VERSION ""

NS_ :

BS_:

BU_: Airbag_MQB BAP_Tester_MQB BMS_MQB Datenlogger_MQB Gateway_MQB Getriebe_DQ_Hybrid_MQB Getriebe_DQ_MQB LEH_MQB Motor_Diesel_MQB Motor_Hybrid_MQB Motor_Otto_MQB SAK_MQB Waehlhebel_MQB Vector__XXX l c i XXX

BO_ 290 ACC_06: 8 XXX
 SG_ CHECKSUM : 0|8@1+ (1,0) [0|255] ""  XXX
 SG_ COUNTER : 8|4@1+ (1,0) [0|15] ""  XXX
 SG_ ACC_Limited_PullAwayDyn : 12|1@1+ (1,0) [0|1] ""  XXX
 SG_ ACC_Retrofit_Stop_Req : 13|1@1+ (1,0) [0|1] ""  XXX
 SG_ ACC_DynIncrease : 14|1@1+ (1.0,0.0) [0.0|1] ""  XXX
 SG_ ACC_FreewheelStrategy_TSK : 15|1@1+ (1.0,0.0) [0.0|1] ""  XXX
 SG_ ACC_Allowed_ControlDeviation_Bottom : 16|6@1+ (0.024,0) [0|1.512] "Unit_MeterPerSeconSquar"  XXX
 SG_ ACC_StartStop_Info : 22|2@1+ (1,0) [0|3] ""  XXX
 SG_ ACC_TargetAcceleration_02 : 24|11@1+ (0.005,-7.22) [-7.22|3.005] "Unit_MeterPerSeconSquar"  XXX
 SG_ ACC_Allowed_ControlDeviation_Top : 35|5@1+ (0.0625,0) [0|1.9375] "Unit_MeterPerSeconSquar"  XXX
 SG_ ACC_Neg_TargetAccel_Degree_02 : 40|8@1+ (0.05,0) [0|12.75] "Unit_MeterPerCubicSecon"  XXX
 SG_ ACC_pos_TargetAccel_Degree_02 : 48|8@1+ (0.05,0) [0|12.75] "Unit_MeterPerCubicSecon"  XXX
 SG_ ACC_PullAway : 56|1@1+ (1,0) [0|1] ""  XXX
 SG_ ACC_Stop : 57|1@1+ (1,0) [0|1] ""  XXX
 SG_ ACC_Type : 58|2@1+ (1,0) [0|3] ""  XXX
 SG_ ACC_Status_ACC : 60|3@1+ (1,0) [0|7] ""  XXX
 SG_ ACC_Minimum_Braking : 63|1@1+ (1,0) [0|1] ""  XXX

BO_ 279 ACC_10: 8 XXX
 SG_ CHECKSUM : 0|8@1+ (1,0) [0|255] ""  XXX
 SG_ COUNTER : 8|4@1+ (1,0) [0|15] ""  XXX
 SG_ AWV_AWA_Status_EPS : 12|4@1+ (1,0) [0|7] ""  XXX
 SG_ AWV1_Req_Prefill : 16|1@1+ (1,0) [0|1] ""  XXX
 SG_ ANB_CM_Info : 17|1@1+ (1,0) [0|1] ""  XXX
 SG_ AWV2_Enable : 18|1@1+ (1,0) [0|1] ""  XXX
 SG_ AWV1_HBA_Param : 19|2@1+ (1,0) [0|3] ""  XXX
 SG_ AWV2_JerkProfile : 21|3@1+ (1,0) [0|7] ""  XXX
 SG_ AWV2_PrioWarning : 24|1@1+ (1,0) [0|1] ""  XXX
 SG_ ANB_CM_Request : 25|1@1+ (1,0) [0|1] ""  XXX
 SG_ ANB_Info_PartialBraking : 26|1@1+ (1,0) [0|1] ""  XXX
 SG_ ANB_EmergencyFlash : 27|1@1+ (1,0) [0|1] ""  XXX
 SG_ ANB_PartialBraking_Enable : 28|1@1+ (1,0) [0|1] ""  XXX
 SG_ ANB_TargetBrake_Teilbrems_Decel_Req : 29|10@1+ (0.024,-20.016) [-20.016|4.536] "Unit_MeterPerSeconSquar"  XXX
 SG_ ANB_TargetBraking_Enable : 39|1@1+ (1,0) [0|1] ""  XXX
 SG_ AWV_BeforeStage : 40|1@1+ (1,0) [0|1] ""  XXX
 SG_ AWV_Hold : 41|1@1+ (1,0) [0|1] ""  XXX
 SG_ AWV_CityANB_Variant : 42|1@1+ (1,0) [0|1] ""  XXX
 SG_ PCF_Enable : 43|1@1+ (1,0) [0|1] ""  XXX
 SG_ AWV1_ECD_StartUp : 44|1@1+ (1,0) [0|1] ""  XXX
 SG_ AWV_AWA_VZ_Req_Lenkmomoffset : 46|1@1+ (1.0,0.0) [0.0|1] ""  XXX
 SG_ AWV_AWA_Req_Lenkmomoffset : 47|9@1+ (0.01,0) [0.00|5.11] "Unit_NewtoMeter"  XXX
 SG_ PCF_Time_to_collision : 56|8@1+ (0.01,0) [0|2.5] "Unit_Secon"  XXX

BO_ 304 PLA_01: 8 XXX
 SG_ CHECKSUM : 0|8@1+ (1,0) [0|255] ""  XXX
 SG_ COUNTER : 8|4@1+ (1,0) [0|15] ""  XXX
 SG_ PLA_Status_PLA_ESP : 12|4@1+ (1.0,0.0) [0.0|15] ""  XXX
 SG_ PLA_LW_Target : 16|13@1+ (0.1,0) [0.0|819.1] "Unit_DegreOfArc"  XXX
 SG_ PLA_VZ_LW_Target : 31|1@1+ (1.0,0.0) [0.0|1] ""  XXX
 SG_ PLA_Status_PLA_EPS : 32|4@1+ (1.0,0.0) [0.0|15] ""  XXX
 SG_ PLA_BrakeTorque m0 : 36|13@1+ (4,0) [0|32760] "Unit_NewtoMeter" XXX
 SG_ PLA_BrakeDeceleration m1 : 36|7@1+ (0.1,0) [0|12] "Unit_MeterPerSeconSquar" XXX
 SG_ PLA_Req_BrakeDeceleration m1 : 43|1@1+ (1,0) [0|1] "" XXX
 SG_ PLA_BrakeTorque_Decel M : 50|1@1+ (1,0) [0|1] "" XXX
 SG_ PLA_Stop : 51|1@1+ (1.0,0.0) [0.0|1] ""  XXX
 SG_ PLA_StoppingDistance : 52|11@1+ (0.01,0) [0.01|20.45] "Unit_Meter"  XXX
 SG_ PLA_01_Signal_red_cyclic : 63|1@1+ (1.0,0.0) [0.0|1] ""  XXX

BO_ 679 ACC_13: 8 XXX
 SG_ ACC_ControlSpeed : 12|10@1+ (0.32,0) [0|327.04] "Unit_KiloMeterPerHour"  XXX
 SG_ ACC_Unit_maxSetSpeed : 22|1@1+ (1,0) [0|1] ""  XXX
 SG_ ACC_maxSetSpeed : 23|9@1+ (1,0) [0|510] ""  XXX
 SG_ ACC_minControlSpeed : 32|8@1+ (0.32,0) [0|81.28] "Unit_KiloMeterPerHour"  XXX
 SG_ ACC_maxControlSpeed : 40|8@1+ (0.32,0) [0|81.28] "Unit_KiloMeterPerHour"  XXX
 SG_ ACC_SpeedLimitAssist : 48|2@1+ (1,0) [0|3] ""  XXX
 SG_ ACC_CurveAssist : 52|3@1+ (1,0) [0|7] ""  XXX
 SG_ ACC_RUV : 56|2@1+ (1,0) [0|3] ""  XXX
 SG_ ACC_SpeedoScale : 58|1@1+ (1,0) [0|1] ""  XXX
 SG_ ACC_Type_SpeedoScale_Bottom : 59|1@1+ (1,0) [0|1] ""  XXX
 SG_ ACC_ENG_Texte : 60|2@1+ (1,0) [0|3] ""  XXX
 SG_ ACC_ADAPTIVE : 63|2@0+ (1,0) [0|3] "" XXX

BO_ 681 ACC_15: 8 XXX
 SG_ AWV_Warning : 16|3@1+ (1,0) [0|7] ""  XXX
 SG_ AWV_Texte : 24|3@1+ (1,0) [0|7] ""  XXX
 SG_ AWV_Status_Display : 32|2@1+ (1,0) [0|3] ""  XXX
 SG_ AWV_OnPosition_System_FSG : 34|1@1+ (1,0) [0|1] ""  XXX
 SG_ AWV_OnPosition_Warning_FSG : 36|3@1+ (1,0) [0|7] ""  XXX
 SG_ AWV_Warnlevel : 58|6@1+ (1,0) [0|63] ""  XXX

BO_ 64 Airbag_01: 8 Airbag_MQB
 SG_ CHECKSUM : 0|8@1+ (1,0) [0|255] "" BMS_MQB,Gateway_MQB,LEH_MQB,Motor_Diesel_MQB,Motor_Hybrid_MQB,Motor_Otto_MQB
 SG_ COUNTER : 8|4@1+ (1,0) [0|15] "" BMS_MQB,Gateway_MQB,LEH_MQB,Motor_Diesel_MQB,Motor_Hybrid_MQB,Motor_Otto_MQB
 SG_ FROM_RGS_Anst : 12|4@1+ (1,0) [0|15] "" Gateway_MQB
 SG_ FROM_Front_Crash : 16|1@1+ (1,0) [0|1] "" Gateway_MQB
 SG_ FROM_Rear_Crash : 17|1@1+ (1,0) [0|1] "" Gateway_MQB
 SG_ FROM_SF_Crash : 18|1@1+ (1,0) [0|1] "" Gateway_MQB
 SG_ FROM_SB_Crash : 19|1@1+ (1,0) [0|1] "" Gateway_MQB
 SG_ FROM_Rollover_Crash : 20|1@1+ (1,0) [0|1] "" Gateway_MQB
 SG_ FROM_Crash_Int : 21|3@1+ (1,0) [0|7] "" BMS_MQB,Gateway_MQB,LEH_MQB,Motor_Diesel_MQB,Motor_Hybrid_MQB,Motor_Otto_MQB
 SG_ FROM_Lamp : 24|1@1+ (1,0) [0|1] "" Gateway_MQB
 SG_ FROM_Deactivated : 25|1@1+ (1,0) [0|1] "" Gateway_MQB
 SG_ FROM_VB_Deactivated : 26|1@1+ (1,0) [0|1] "" Gateway_MQB
 SG_ FROM_SystemError : 27|1@1+ (1,0) [0|1] "" BMS_MQB,Gateway_MQB,LEH_MQB
 SG_ FROM_Diagnostics : 28|1@1+ (1,0) [0|1] "" Gateway_MQB
 SG_ FROM_ActuatorTest : 29|1@1+ (1,0) [0|1] "" BMS_MQB,Gateway_MQB,Motor_Diesel_MQB,Motor_Hybrid_MQB,Motor_Otto_MQB
 SG_ FROM_Erh_Open_VB : 30|2@1+ (1,0) [0|3] "" Gateway_MQB
 SG_ FROM_BeltWarn_VF : 32|1@1+ (1,0) [0|1] "" Gateway_MQB
 SG_ FROM_BeltWarn_VB : 33|1@1+ (1,0) [0|1] "" Gateway_MQB
 SG_ FROM_Display_Pedestrian : 34|2@1+ (1,0) [0|3] "" Gateway_MQB
 SG_ FROM_Texte_AKS : 36|2@1+ (1,0) [0|3] "" Gateway_MQB
 SG_ FROM_PAO_Lamp_Req : 38|1@1+ (1,0) [0|1] "" Gateway_MQB
 SG_ FROM_MKB_Valid : 39|1@1+ (1,0) [0|1] "" Gateway_MQB
 SG_ FROM_MKB_Request : 40|1@1+ (1,0) [0|1] "" Gateway_MQB
 SG_ FROM_SupplyVoltage : 41|1@1+ (1,0) [0|1] "" Gateway_MQB
 SG_ FROM_Deactivation_HV : 42|3@1+ (1.0,0.0) [0.0|7] ""  BMS,Gateway_MQB,LEH_MQB,Motor_Hybrid_MQB
 SG_ FROM_EDR_Trigger : 45|2@1+ (1.0,0.0) [0.0|3] ""  Gateway_MQB
 SG_ FROM_BeltWarn_HFS : 47|1@1+ (1.0,0.0) [0.0|1] ""  Gateway_MQB
 SG_ FROM_BeltWarn_HBFS : 48|1@1+ (1.0,0.0) [0.0|1] ""  Gateway_MQB
 SG_ SC_MasterTime_Offset : 53|2@1+ (5.08,0) [0.00|15.24] "Unit_Secon"  Gateway_MQB
 SG_ SC_MasterTime : 57|7@1+ (0.04,0) [0.00|5.04] "Unit_Secon"  Gateway_MQB

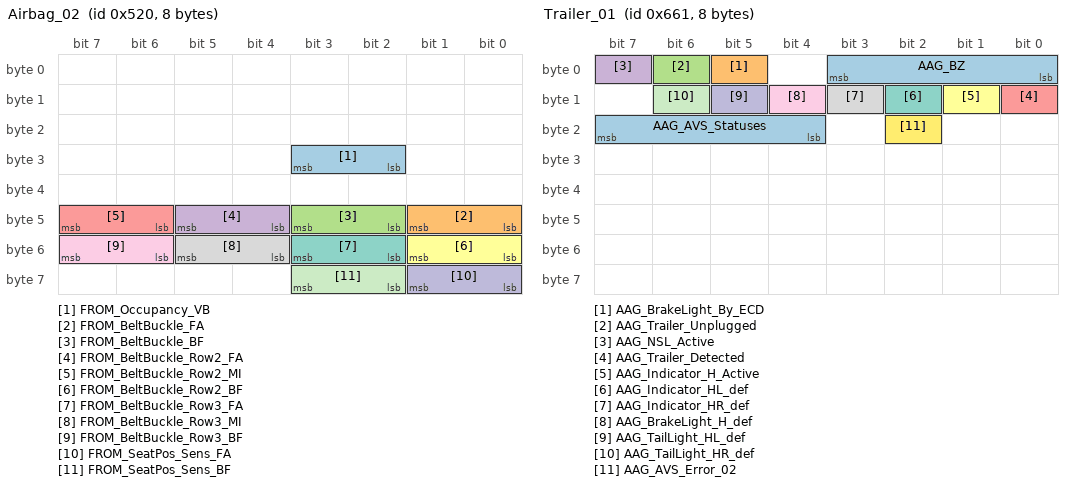
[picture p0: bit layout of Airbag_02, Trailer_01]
BO_ 1312 Airbag_02: 8 Airbag_MQB
 SG_ FROM_Occupancy_VB : 26|2@1+ (1,0) [0|3] "" Gateway_MQB
 SG_ FROM_BeltBuckle_FA : 40|2@1+ (1,0) [0|3] "" Gateway_MQB,Motor_Diesel_MQB,Motor_Otto_MQB
 SG_ FROM_BeltBuckle_BF : 42|2@1+ (1,0) [0|3] "" Gateway_MQB
 SG_ FROM_BeltBuckle_Row2_FA : 44|2@1+ (1,0) [0|3] "" Gateway_MQB
 SG_ FROM_BeltBuckle_Row2_MI : 46|2@1+ (1,0) [0|3] "" Gateway_MQB
 SG_ FROM_BeltBuckle_Row2_BF : 48|2@1+ (1,0) [0|3] "" Gateway_MQB
 SG_ FROM_BeltBuckle_Row3_FA : 50|2@1+ (1,0) [0|3] "" Gateway_MQB
 SG_ FROM_BeltBuckle_Row3_MI : 52|2@1+ (1,0) [0|3] "" Gateway_MQB
 SG_ FROM_BeltBuckle_Row3_BF : 54|2@1+ (1,0) [0|3] "" Gateway_MQB
 SG_ FROM_SeatPos_Sens_FA : 56|2@1+ (1,0) [0|3] "" Gateway_MQB
 SG_ FROM_SeatPos_Sens_BF : 58|2@1+ (1,0) [0|3] "" Gateway_MQB

BO_ 65 Airbag_03: 8 Airbag_MQB
 SG_ Airbag_03_CRC : 0|8@1+ (1,0) [0|255] "" Gateway_MQB
 SG_ Airbag_03_BZ : 8|4@1+ (1,0) [0|15] "" Gateway_MQB
 SG_ FROM_MKB_Safing : 63|1@1+ (1,0) [0|1] "" Gateway_MQB

BO_ 1633 Trailer_01: 8 Gateway_MQB
 SG_ AAG_BZ : 0|4@1+ (1,0) [0|15] "" Motor_Diesel_MQB,Motor_Hybrid_MQB,Motor_Otto_MQB
 SG_ AAG_BrakeLight_By_ECD : 5|1@1+ (1,0) [0|1] "" Motor_Diesel_MQB,Motor_Hybrid_MQB,Motor_Otto_MQB
 SG_ AAG_Trailer_Unplugged : 6|1@1+ (1,0) [0|1] "" Vector__XXX
 SG_ AAG_NSL_Active : 7|1@1+ (1,0) [0|1] "" Vector__XXX
 SG_ AAG_Trailer_Detected : 8|1@1+ (1,0) [0|1] "" Motor_Diesel_MQB,Motor_Hybrid_MQB,Motor_Otto_MQB
 SG_ AAG_Indicator_H_Active : 9|1@1+ (1,0) [0|1] "" Vector__XXX
 SG_ AAG_Indicator_HL_def : 10|1@1+ (1,0) [0|1] "" Vector__XXX
 SG_ AAG_Indicator_HR_def : 11|1@1+ (1,0) [0|1] "" Vector__XXX
 SG_ AAG_BrakeLight_H_def : 12|1@1+ (1,0) [0|1] "" Motor_Diesel_MQB,Motor_Hybrid_MQB,Motor_Otto_MQB
 SG_ AAG_TailLight_HL_def : 13|1@1+ (1,0) [0|1] "" Vector__XXX
 SG_ AAG_TailLight_HR_def : 14|1@1+ (1,0) [0|1] "" Vector__XXX
 SG_ AAG_AVS_Error_02 : 18|1@1+ (1,0) [0|1] "" Vector__XXX
 SG_ AAG_AVS_Statuses : 20|4@1+ (1,0) [0|15] "" Vector__XXX

BO_ 1626 BCM_01: 8 Gateway_MQB
 SG_ BCM_BrakePad_Sensor : 12|1@1+ (1,0) [0|1] "" Vector__XXX
 SG_ BCM_BrakeFluid_Sensor : 13|1@1+ (1,0) [0|1] "" Vector__XXX
 SG_ BCM1_Light_Warn : 14|1@1+ (1,0) [0|1] "" Vector__XXX
 SG_ BCM_WasherFluid_Sensor : 15|1@1+ (1,0) [0|1] "" Vector__XXX
 SG_ BCM_Coolant_Sensor : 16|1@1+ (1,0) [0|1] "" Motor_Diesel_MQB,Motor_Otto_MQB
 SG_ BCM1_Term_15_HW_Detected : 17|1@1+ (1,0) [0|1] "" Vector__XXX
 SG_ BCM_Eis_Offroad_Key : 18|1@1+ (1,0) [0|1] "" Getriebe_DQ_Hybrid_MQB,Getriebe_DQ_MQB,Motor_Diesel_MQB,Motor_Otto_MQB
 SG_ ZZH_EndPosition_Top : 19|1@1+ (1,0) [0|1] "" Vector__XXX
 SG_ ZZH_EndPosition_Bottom : 20|1@1+ (1,0) [0|1] "" Vector__XXX
 SG_ ZZH_EndPosition_Implausible : 21|1@1+ (1,0) [0|1] "" Vector__XXX
 SG_ BCM2_EZS_Pressed : 22|1@1+ (1,0) [0|1] "" Vector__XXX
 SG_ BCM2_SST_Pressed : 23|1@1+ (1,0) [0|1] "" Vector__XXX
 SG_ BCM_Hybrid_StartStop_Key : 24|1@1+ (1,0) [0|1] "" Getriebe_DQ_Hybrid_MQB,Getriebe_DQ_MQB,Motor_Diesel_MQB,Motor_Hybrid_MQB,Motor_Otto_MQB
 SG_ BCM1_HazardFlash_PushButton : 25|1@1+ (1,0) [0|1] "" Vector__XXX
 SG_ BCM1_Valet_Parking_PushButton : 26|1@1+ (1,0) [0|1] "" Vector__XXX
 SG_ BCM_Remotestart_Operation : 27|1@1+ (1,0) [0|1] "" Motor_Diesel_MQB,Motor_Otto_MQB
 SG_ BCM1_HSK_PushButton : 28|1@1+ (1,0) [0|1] "" Vector__XXX
 SG_ BCM1_RearBlind_PushButton : 29|1@1+ (1,0) [0|1] "" Vector__XXX
 SG_ BCM1_ReversingLight_Switch : 30|1@1+ (1,0) [0|1] "" Getriebe_DQ_Hybrid_MQB,Getriebe_DQ_MQB,Motor_Diesel_MQB,Motor_Hybrid_MQB,Motor_Otto_MQB
 SG_ BCM1_MH_Switch : 31|1@1+ (1,0) [0|1] "" Motor_Diesel_MQB,Motor_Otto_MQB
 SG_ BCM1_MH_WIV_Switch : 32|1@1+ (1,0) [0|1] "" Motor_Diesel_MQB,Motor_Hybrid_MQB,Motor_Otto_MQB
 SG_ BCM_Eco_Charisma_Key : 33|1@1+ (1,0) [0|1] "" Getriebe_DQ_Hybrid_MQB,Getriebe_DQ_MQB
 SG_ BCM_ThermalManagement : 34|2@1+ (1,0) [0|3] "" Motor_Diesel_MQB,Motor_Hybrid_MQB,Motor_Otto_MQB
 SG_ BCM_ThermalManagement_Error : 36|1@1+ (1,0) [0|1] "" Motor_Diesel_MQB,Motor_Hybrid_MQB,Motor_Otto_MQB
 SG_ BCM_ThermalManagement_Valid : 37|1@1+ (1,0) [0|1] "" Motor_Diesel_MQB,Motor_Hybrid_MQB,Motor_Otto_MQB
 SG_ BCM1_LightWarn_Texte : 38|2@1+ (1,0) [0|3] "" Vector__XXX

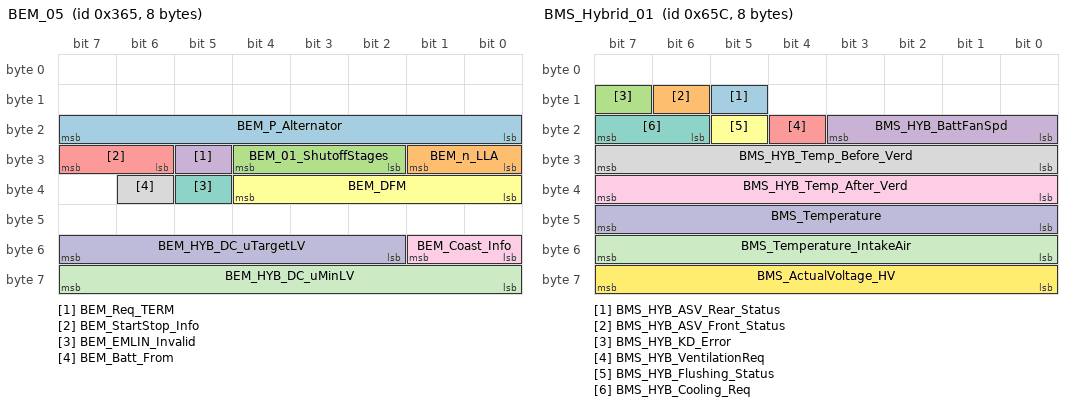
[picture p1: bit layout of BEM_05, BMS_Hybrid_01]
BO_ 869 BEM_05: 8 Gateway_MQB
 SG_ BEM_P_Alternator : 16|8@1+ (50,0) [0|12700] "Unit_Watt" Motor_Diesel_MQB,Motor_Hybrid_MQB,Motor_Otto_MQB
 SG_ BEM_n_LLA : 24|2@1+ (1,0) [0|3] "" Motor_Diesel_MQB,Motor_Hybrid_MQB,Motor_Otto_MQB
 SG_ BEM_01_ShutoffStages : 26|3@1+ (1,0) [0|7] "" Motor_Diesel_MQB,Motor_Hybrid_MQB,Motor_Otto_MQB
 SG_ BEM_Req_TERM : 29|1@1+ (1,0) [0|1] "" Motor_Diesel_MQB,Motor_Hybrid_MQB,Motor_Otto_MQB
 SG_ BEM_StartStop_Info : 30|2@1+ (1,0) [0|3] "" Motor_Diesel_MQB,Motor_Otto_MQB
 SG_ BEM_DFM : 32|5@1+ (3.225,0.025) [0.025|100] "" Motor_Diesel_MQB,Motor_Hybrid_MQB,Motor_Otto_MQB
 SG_ BEM_EMLIN_Invalid : 37|1@1+ (1,0) [0|1] "" Motor_Diesel_MQB,Motor_Hybrid_MQB,Motor_Otto_MQB
 SG_ BEM_Batt_From : 38|1@1+ (1,0) [0|1] "" Motor_Diesel_MQB,Motor_Hybrid_MQB,Motor_Otto_MQB
 SG_ BEM_Coast_Info : 48|2@1+ (1,0) [0|3] "" Getriebe_DQ_Hybrid_MQB,Getriebe_DQ_MQB,Motor_Diesel_MQB,Motor_Hybrid_MQB,Motor_Otto_MQB
 SG_ BEM_HYB_DC_uTargetLV : 50|6@1+ (0.1,10.6) [10.6|16] "Unit_Volt" LEH_MQB
 SG_ BEM_HYB_DC_uMinLV : 56|8@1+ (0.1,0) [0|25.3] "Unit_Volt" LEH_MQB

BO_ 1628 BMS_Hybrid_01: 8 BMS_MQB
 SG_ BMS_HYB_ASV_Rear_Status : 13|1@1+ (1,0) [0|1] "" Gateway_MQB
 SG_ BMS_HYB_ASV_Front_Status : 14|1@1+ (1,0) [0|1] "" Gateway_MQB
 SG_ BMS_HYB_KD_Error : 15|1@1+ (1,0) [0|1] "" Gateway_MQB
 SG_ BMS_HYB_BattFanSpd : 16|4@1+ (10,0) [0|100] "Unit_PerCent" Gateway_MQB
 SG_ BMS_HYB_VentilationReq : 20|1@1+ (1,0) [0|1] "" Gateway_MQB
 SG_ BMS_HYB_Flushing_Status : 21|1@1+ (1,0) [0|1] "" Gateway_MQB
 SG_ BMS_HYB_Cooling_Req : 22|2@1+ (1,0) [0|3] "" Gateway_MQB
 SG_ BMS_HYB_Temp_Before_Verd : 24|8@1+ (0.5,-40) [-40|86.5] "Unit_DegreCelsi" Gateway_MQB
 SG_ BMS_HYB_Temp_After_Verd : 32|8@1+ (0.5,-40) [-40|86.5] "Unit_DegreCelsi" Gateway_MQB
 SG_ BMS_Temperature : 40|8@1+ (0.5,-40) [-40|86.5] "Unit_DegreCelsi" Gateway_MQB
 SG_ BMS_Temperature_IntakeAir : 48|8@1+ (0.5,-40) [-40|86.5] "Unit_DegreCelsi" Gateway_MQB
 SG_ BMS_ActualVoltage_HV : 56|8@1+ (1,100) [100|350] "Unit_Volt" Gateway_MQB

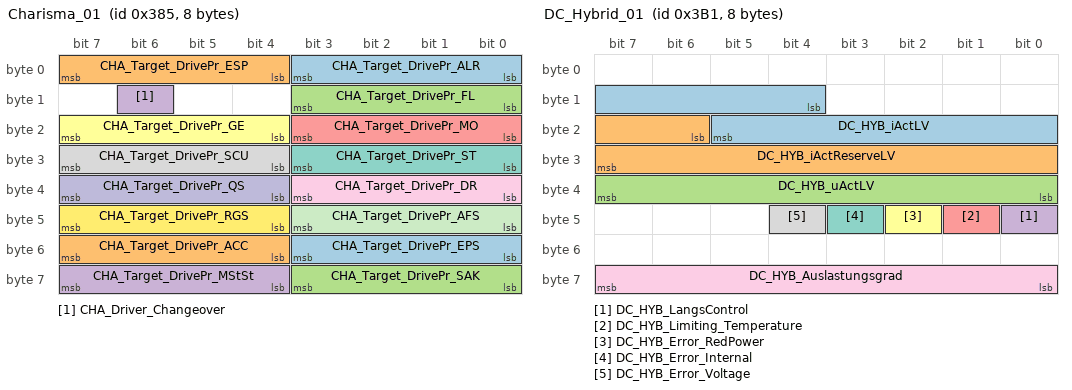
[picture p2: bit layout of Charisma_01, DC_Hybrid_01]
BO_ 901 Charisma_01: 8 Gateway_MQB
 SG_ CHA_Target_DrivePr_ALR : 0|4@1+ (1,0) [0|15] "" Vector__XXX
 SG_ CHA_Target_DrivePr_ESP : 4|4@1+ (1,0) [0|15] "" Vector__XXX
 SG_ CHA_Target_DrivePr_FL : 8|4@1+ (1,0) [0|15] "" Vector__XXX
 SG_ CHA_Driver_Changeover : 14|1@1+ (1,0) [0|1] "" Airbag_MQB,Getriebe_DQ_Hybrid_MQB,Getriebe_DQ_MQB,Motor_Diesel_MQB,Motor_Hybrid_MQB,Motor_Otto_MQB,SAK_MQB
 SG_ CHA_Target_DrivePr_MO : 16|4@1+ (1,0) [0|15] "" Motor_Diesel_MQB,Motor_Hybrid_MQB,Motor_Otto_MQB
 SG_ CHA_Target_DrivePr_GE : 20|4@1+ (1,0) [0|15] "" Getriebe_DQ_Hybrid_MQB,Getriebe_DQ_MQB
 SG_ CHA_Target_DrivePr_ST : 24|4@1+ (1,0) [0|15] "" Vector__XXX
 SG_ CHA_Target_DrivePr_SCU : 28|4@1+ (1,0) [0|15] "" Vector__XXX
 SG_ CHA_Target_DrivePr_DR : 32|4@1+ (1,0) [0|15] "" Vector__XXX
 SG_ CHA_Target_DrivePr_QS : 36|4@1+ (1,0) [0|15] "" Vector__XXX
 SG_ CHA_Target_DrivePr_AFS : 40|4@1+ (1,0) [0|15] "" Vector__XXX
 SG_ CHA_Target_DrivePr_RGS : 44|4@1+ (1,0) [0|15] "" Airbag_MQB
 SG_ CHA_Target_DrivePr_EPS : 48|4@1+ (1,0) [0|15] "" Vector__XXX
 SG_ CHA_Target_DrivePr_ACC : 52|4@1+ (1,0) [0|15] "" Vector__XXX
 SG_ CHA_Target_DrivePr_SAK : 56|4@1+ (1,0) [0|15] "" SAK_MQB
 SG_ CHA_Target_DrivePr_MStSt : 60|4@1+ (1,0) [0|15] "" Vector__XXX

BO_ 945 DC_Hybrid_01: 8 LEH_MQB
 SG_ DC_HYB_iActLV : 12|10@1+ (1,-511) [-511|510] "Unit_Amper" Gateway_MQB
 SG_ DC_HYB_iActReserveLV : 22|10@1+ (1,-511) [-511|510] "Unit_Amper" Gateway_MQB
 SG_ DC_HYB_uActLV : 32|8@1+ (0.1,0) [0|25.3] "Unit_Volt" Gateway_MQB
 SG_ DC_HYB_LangsControl : 40|1@1+ (1,0) [0|1] "" Gateway_MQB
 SG_ DC_HYB_Limiting_Temperature : 41|1@1+ (1,0) [0|1] "" Gateway_MQB
 SG_ DC_HYB_Error_RedPower : 42|1@1+ (1,0) [0|1] "" Gateway_MQB
 SG_ DC_HYB_Error_Internal : 43|1@1+ (1,0) [0|1] "" Gateway_MQB
 SG_ DC_HYB_Error_Voltage : 44|1@1+ (1,0) [0|1] "" Gateway_MQB
 SG_ DC_HYB_Auslastungsgrad : 56|8@1+ (0.4,0) [0|100] "Unit_PerCent" Gateway_MQB

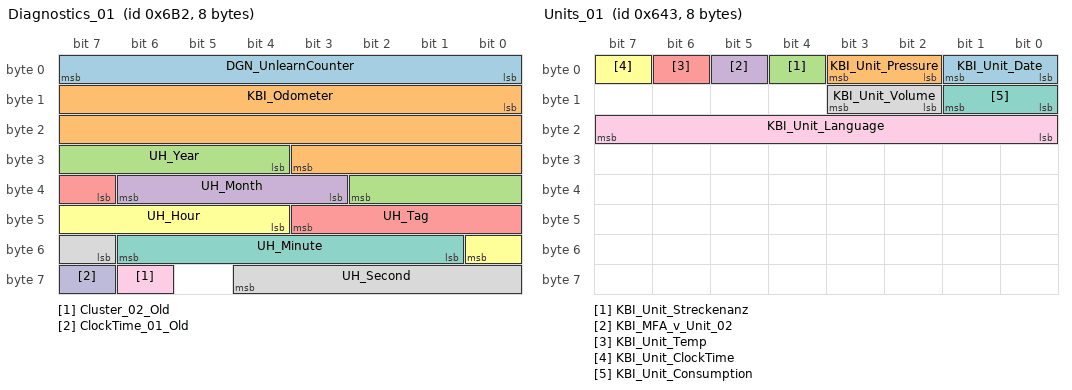
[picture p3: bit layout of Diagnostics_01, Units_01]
BO_ 1714 Diagnostics_01: 8 Gateway_MQB
 SG_ DGN_UnlearnCounter : 0|8@1+ (1,0) [0|254] "" Airbag_MQB,BMS_MQB,Getriebe_DQ_Hybrid_MQB,Getriebe_DQ_MQB,LEH_MQB,SAK_MQB
 SG_ KBI_Odometer : 8|20@1+ (1,0) [0|1048573] "Unit_KiloMeter" Airbag_MQB,BMS_MQB,Getriebe_DQ_Hybrid_MQB,Getriebe_DQ_MQB,LEH_MQB,Motor_Diesel_MQB,Motor_Hybrid_MQB,Motor_Otto_MQB,SAK_MQB
 SG_ UH_Year : 28|7@1+ (1,2000) [2000|2127] "Unit_Year" Airbag_MQB,BMS_MQB,Getriebe_DQ_Hybrid_MQB,Getriebe_DQ_MQB,LEH_MQB,Motor_Diesel_MQB,Motor_Hybrid_MQB,Motor_Otto_MQB,SAK_MQB
 SG_ UH_Month : 35|4@1+ (1,0) [1|12] "Unit_Month" Airbag_MQB,BMS_MQB,Getriebe_DQ_Hybrid_MQB,Getriebe_DQ_MQB,LEH_MQB,Motor_Diesel_MQB,Motor_Hybrid_MQB,Motor_Otto_MQB,SAK_MQB
 SG_ UH_Tag : 39|5@1+ (1,0) [1|31] "Unit_Day" Airbag_MQB,BMS_MQB,Getriebe_DQ_Hybrid_MQB,Getriebe_DQ_MQB,LEH_MQB,Motor_Diesel_MQB,Motor_Hybrid_MQB,Motor_Otto_MQB,SAK_MQB
 SG_ UH_Hour : 44|5@1+ (1,0) [0|23] "Unit_Hours" Airbag_MQB,BMS_MQB,Getriebe_DQ_Hybrid_MQB,Getriebe_DQ_MQB,LEH_MQB,Motor_Diesel_MQB,Motor_Hybrid_MQB,Motor_Otto_MQB,SAK_MQB
 SG_ UH_Minute : 49|6@1+ (1,0) [0|59] "Unit_Minut" Airbag_MQB,BMS_MQB,Getriebe_DQ_Hybrid_MQB,Getriebe_DQ_MQB,LEH_MQB,Motor_Diesel_MQB,Motor_Hybrid_MQB,Motor_Otto_MQB,SAK_MQB
 SG_ UH_Second : 55|6@1+ (1,0) [0|59] "Unit_Secon" Airbag_MQB,BMS_MQB,Getriebe_DQ_Hybrid_MQB,Getriebe_DQ_MQB,LEH_MQB,Motor_Diesel_MQB,Motor_Hybrid_MQB,Motor_Otto_MQB,SAK_MQB
 SG_ Cluster_02_Old : 62|1@1+ (1,0) [0|1] "" Airbag_MQB,BMS_MQB,LEH_MQB
 SG_ ClockTime_01_Old : 63|1@1+ (1,0) [0|1] "" Airbag_MQB,BMS_MQB,LEH_MQB

BO_ 1520 Dimming_01: 8 Gateway_MQB
 SG_ DI_TERM_58xd : 0|8@1+ (1,0) [0|253] "" Airbag_MQB
 SG_ DI_TERM_58xs : 8|7@1+ (1,0) [0|100] "Unit_PerCent" Vector__XXX
 SG_ DI_Display_NightDesign : 15|1@1+ (1,0) [0|1] "" Vector__XXX
 SG_ DI_TERM_58xt : 16|7@1+ (1,0) [0|100] "Unit_PerCent" Vector__XXX
 SG_ DI_PhotoSensor : 24|16@1+ (1,0) [0|65535] "" Vector__XXX

BO_ 1603 Units_01: 8 Gateway_MQB
 SG_ KBI_Unit_Date : 0|2@1+ (1,0) [0|3] "" Vector__XXX
 SG_ KBI_Unit_Pressure : 2|2@1+ (1,0) [0|3] "" Vector__XXX
 SG_ KBI_Unit_Streckenanz : 4|1@1+ (1,0) [0|1] "" Motor_Diesel_MQB
 SG_ KBI_MFA_v_Unit_02 : 5|1@1+ (1,0) [0|1] "" Vector__XXX
 SG_ KBI_Unit_Temp : 6|1@1+ (1,0) [0|1] "" Vector__XXX
 SG_ KBI_Unit_ClockTime : 7|1@1+ (1,0) [0|1] "" Vector__XXX
 SG_ KBI_Unit_Consumption : 8|2@1+ (1,0) [0|3] "" Vector__XXX
 SG_ KBI_Unit_Volume : 10|2@1+ (1,0) [0|3] "" Vector__XXX
 SG_ KBI_Unit_Language : 16|8@1+ (1,0) [0|255] "" Vector__XXX

BO_ 260 EPB_01: 8 Gateway_MQB
 SG_ EPB_01_CRC : 0|8@1+ (1,0) [0|255] "" Getriebe_DQ_Hybrid_MQB,Getriebe_DQ_MQB,Motor_Diesel_MQB,Motor_Hybrid_MQB,Motor_Otto_MQB
 SG_ EPB_01_BZ : 8|4@1+ (1,0) [0|15] "" Getriebe_DQ_Hybrid_MQB,Getriebe_DQ_MQB,Motor_Diesel_MQB,Motor_Hybrid_MQB,Motor_Otto_MQB
 SG_ EPB_QBit_LongAccel : 12|1@1+ (1,0) [0|1] "" Vector__XXX
 SG_ EPB_QBit_PedalTravel_Clutch : 13|1@1+ (1,0) [0|1] "" Vector__XXX
 SG_ EPB_BCM2_Engine_Wakeup : 14|1@1+ (1,0) [0|1] "" Vector__XXX
 SG_ EPB_Enable_Decel_Req : 15|1@1+ (1,0) [0|1] "" Motor_Diesel_MQB,Motor_Hybrid_MQB,Motor_Otto_MQB
 SG_ EPB_Decel_Req : 16|8@1+ (0.048,-7.968) [-7.968|4.224] "Unit_MeterPerSeconSquar" Vector__XXX
 SG_ EPB_LongAccel : 24|8@1+ (1,-128) [-128|126] "Unit_PerCentOfForceOfGravi" Vector__XXX
 SG_ EPB_PedalTravel_Clutch : 32|8@1+ (0.4,0) [8|92] "Unit_PerCent" Vector__XXX
 SG_ EPB_PullAwayRequest_Detected : 48|1@1+ (1,0) [0|1] "" Vector__XXX
 SG_ EPB_DAA_BoundaryCond_erf : 49|1@1+ (1,0) [0|1] "" Getriebe_DQ_Hybrid_MQB,Getriebe_DQ_MQB
 SG_ EPB_ErrorStatus : 50|2@1+ (1,0) [0|3] "" Vector__XXX
 SG_ EPB_Schalterposition : 52|2@1+ (1,0) [0|3] "" Motor_Diesel_MQB,Motor_Hybrid_MQB,Motor_Otto_MQB
 SG_ EPB_QBit_Schalterpos : 54|1@1+ (1,0) [0|1] "" Motor_Diesel_MQB,Motor_Hybrid_MQB,Motor_Otto_MQB
 SG_ EPB_Consistency_ACC : 55|1@1+ (1,0) [0|1] "" Vector__XXX
 SG_ EPB_ClampForce : 56|5@1+ (1,0) [0|29] "Unit_KiloNewto" Getriebe_DQ_Hybrid_MQB,Getriebe_DQ_MQB
 SG_ EPB_Status : 61|2@1+ (1,0) [0|3] "" Getriebe_DQ_Hybrid_MQB,Getriebe_DQ_MQB,Motor_Diesel_MQB,Motor_Hybrid_MQB,Motor_Otto_MQB

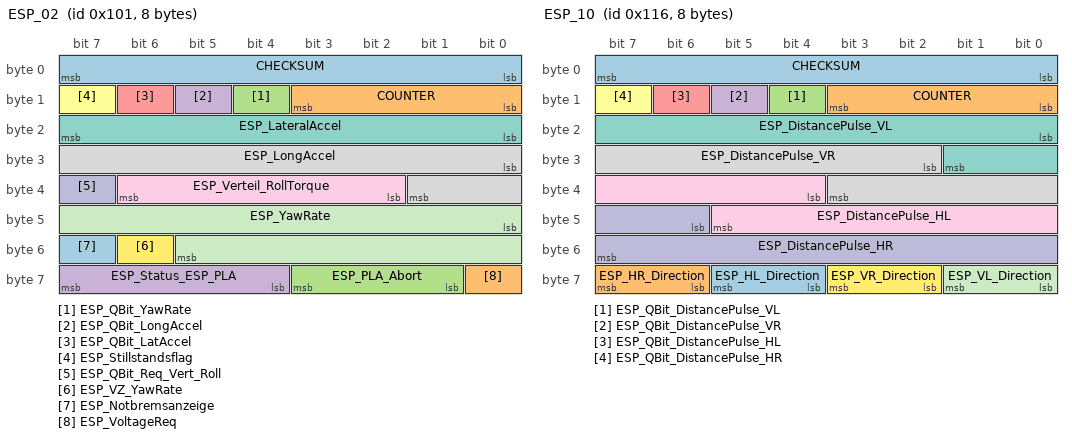
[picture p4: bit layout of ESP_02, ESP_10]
BO_ 257 ESP_02: 8 Gateway_MQB
 SG_ CHECKSUM : 0|8@1+ (1,0) [0|255] "" Airbag_MQB,Getriebe_DQ_Hybrid_MQB,Getriebe_DQ_MQB,Motor_Diesel_MQB,Motor_Hybrid_MQB,Motor_Otto_MQB
 SG_ COUNTER : 8|4@1+ (1,0) [0|15] "" Airbag_MQB,Getriebe_DQ_Hybrid_MQB,Getriebe_DQ_MQB,Motor_Diesel_MQB,Motor_Hybrid_MQB,Motor_Otto_MQB
 SG_ ESP_QBit_YawRate : 12|1@1+ (1,0) [0|1] "" Airbag_MQB,Getriebe_DQ_Hybrid_MQB,Getriebe_DQ_MQB
 SG_ ESP_QBit_LongAccel : 13|1@1+ (1,0) [0|1] "" Airbag_MQB,Getriebe_DQ_Hybrid_MQB,Getriebe_DQ_MQB,Motor_Diesel_MQB,Motor_Hybrid_MQB,Motor_Otto_MQB
 SG_ ESP_QBit_LatAccel : 14|1@1+ (1,0) [0|1] "" Airbag_MQB,Getriebe_DQ_Hybrid_MQB,Getriebe_DQ_MQB,Motor_Diesel_MQB,Motor_Hybrid_MQB,Motor_Otto_MQB
 SG_ ESP_Stillstandsflag : 15|1@1+ (1,0) [0|1] "" Vector__XXX
 SG_ ESP_LateralAccel : 16|8@1+ (0.01,-1.27) [-1.27|1.27] "Unit_ForceOfGravi" Airbag_MQB,Getriebe_DQ_Hybrid_MQB,Getriebe_DQ_MQB,Motor_Diesel_MQB,Motor_Hybrid_MQB,Motor_Otto_MQB
 SG_ ESP_LongAccel : 24|10@1+ (0.03125,-16) [-16|15.90625] "Unit_MeterPerSeconSquar" Airbag_MQB,Getriebe_DQ_Hybrid_MQB,Getriebe_DQ_MQB,Motor_Diesel_MQB,Motor_Hybrid_MQB,Motor_Otto_MQB
 SG_ ESP_Verteil_RollTorque : 34|5@1+ (0.1,-1) [-1|1] "" Vector__XXX
 SG_ ESP_QBit_Req_Vert_Roll : 39|1@1+ (1,0) [0|1] "" Vector__XXX
 SG_ ESP_YawRate : 40|14@1+ (0.01,0) [0|163.82] "Unit_DegreOfArcPerSecon" Airbag_MQB,Getriebe_DQ_Hybrid_MQB,Getriebe_DQ_MQB
 SG_ ESP_VZ_YawRate : 54|1@1+ (1,0) [0|1] "" Airbag_MQB,Getriebe_DQ_Hybrid_MQB,Getriebe_DQ_MQB
 SG_ ESP_Notbremsanzeige : 55|1@1+ (1,0) [0|1] "" Airbag_MQB
 SG_ ESP_VoltageReq : 56|1@1+ (1,0) [0|1] "" Vector__XXX
 SG_ ESP_PLA_Abort : 57|3@1+ (1,0) [0|7] "" Vector__XXX
 SG_ ESP_Status_ESP_PLA : 60|4@1+ (1,0) [0|15] "" Getriebe_DQ_Hybrid_MQB,Getriebe_DQ_MQB

BO_ 262 ESP_05: 8 Gateway_MQB
 SG_ CHECKSUM : 0|8@1+ (1,0) [0|255] "" Airbag_MQB,Getriebe_DQ_Hybrid_MQB,Getriebe_DQ_MQB,Motor_Diesel_MQB,Motor_Hybrid_MQB,Motor_Otto_MQB
 SG_ COUNTER : 8|4@1+ (1,0) [0|15] "" Airbag_MQB,Getriebe_DQ_Hybrid_MQB,Getriebe_DQ_MQB,Motor_Diesel_MQB,Motor_Hybrid_MQB,Motor_Otto_MQB
 SG_ ESP_QBit_BrakePressure : 12|1@1+ (1,0) [0|1] "" Airbag_MQB,Getriebe_DQ_Hybrid_MQB,Getriebe_DQ_MQB,Motor_Diesel_MQB,Motor_Hybrid_MQB,Motor_Otto_MQB
 SG_ ESP_QBit_Driver_Brakes : 13|1@1+ (1,0) [0|1] "" Motor_Diesel_MQB,Motor_Hybrid_MQB,Motor_Otto_MQB
 SG_ ESP_Threshold_Vacuum : 14|2@1+ (1,0) [0|3] "" Motor_Diesel_MQB,Motor_Hybrid_MQB,Motor_Otto_MQB
 SG_ ESP_BrakePressure : 16|10@1+ (0.3,-30) [-30|276.6] "Unit_Bar" Airbag_MQB,Getriebe_DQ_Hybrid_MQB,Getriebe_DQ_MQB,Motor_Diesel_MQB,Motor_Hybrid_MQB,Motor_Otto_MQB
 SG_ ESP_Driver_Brakes : 26|1@1+ (1,0) [0|1] "" Motor_Diesel_MQB,Motor_Hybrid_MQB,Motor_Otto_MQB
 SG_ ESP_Decel_TSK_Active : 27|1@1+ (1,0) [0|1] "" Getriebe_DQ_Hybrid_MQB,Getriebe_DQ_MQB,Motor_Diesel_MQB,Motor_Hybrid_MQB,Motor_Otto_MQB
 SG_ ESP_SteeringIntervention_ADS : 28|1@1+ (1,0) [0|1] "" Motor_Diesel_MQB,Motor_Hybrid_MQB,Motor_Otto_MQB
 SG_ ESP_Consistency_TSK : 29|1@1+ (1,0) [0|1] "" Motor_Diesel_MQB,Motor_Hybrid_MQB,Motor_Otto_MQB
 SG_ ESP_BrakeJerk_AWV2 : 30|1@1+ (1,0) [0|1] "" Getriebe_DQ_Hybrid_MQB,Getriebe_DQ_MQB,Motor_Diesel_MQB,Motor_Hybrid_MQB,Motor_Otto_MQB
 SG_ ESP_Consistency_AWV2 : 31|1@1+ (1,0) [0|1] "" Vector__XXX
 SG_ ECD_Error : 32|1@1+ (1,0) [0|1] "" Motor_Diesel_MQB,Motor_Hybrid_MQB,Motor_Otto_MQB
 SG_ ECD_Not_Available : 33|1@1+ (1,0) [0|1] "" Motor_Diesel_MQB,Motor_Hybrid_MQB,Motor_Otto_MQB
 SG_ ESP_Status_BrakesTemp : 34|1@1+ (1,0) [0|1] "" Motor_Diesel_MQB,Motor_Hybrid_MQB,Motor_Otto_MQB
 SG_ ESP_AutoHold_Standby : 35|1@1+ (1,0) [0|1] "" Vector__XXX
 SG_ ESP_HDC_Standby : 36|1@1+ (1,0) [0|1] "" Getriebe_DQ_Hybrid_MQB,Getriebe_DQ_MQB
 SG_ ESP_HBA_Active : 37|1@1+ (1,0) [0|1] "" Vector__XXX
 SG_ ESP_Prefill_Triggered : 38|1@1+ (1,0) [0|1] "" Motor_Diesel_MQB,Motor_Hybrid_MQB,Motor_Otto_MQB
 SG_ ESP_Reversing_Detected : 39|1@1+ (1,0) [0|1] "" Vector__XXX
 SG_ ESP_Status_HillStartAssist : 40|1@1+ (1,0) [0|1] "" Getriebe_DQ_Hybrid_MQB,Getriebe_DQ_MQB,Motor_Diesel_MQB,Motor_Hybrid_MQB,Motor_Otto_MQB
 SG_ ESP_HDC_Active : 41|1@1+ (1,0) [0|1] "" Getriebe_DQ_Hybrid_MQB,Getriebe_DQ_MQB
 SG_ ESP_StartStop_Info : 42|2@1+ (1,0) [0|3] "" Motor_Diesel_MQB,Motor_Otto_MQB
 SG_ ESP_Interv_HL : 44|1@1+ (1,0) [0|1] "" Vector__XXX
 SG_ ESP_Interv_HR : 45|1@1+ (1,0) [0|1] "" Vector__XXX
 SG_ ESP_Interv_VL : 46|1@1+ (1,0) [0|1] "" Vector__XXX
 SG_ ESP_Interv_VR : 47|1@1+ (1,0) [0|1] "" Vector__XXX
 SG_ ESP_BKV_Vacuum : 48|8@1+ (4,0) [0|1012] "Unit_MilliBar" Motor_Diesel_MQB,Motor_Hybrid_MQB,Motor_Otto_MQB
 SG_ ESP_AutoHold_Active : 56|1@1+ (1,0) [0|1] "" Getriebe_DQ_Hybrid_MQB,Getriebe_DQ_MQB,Motor_Diesel_MQB,Motor_Hybrid_MQB,Motor_Otto_MQB
 SG_ ESP_FStatus_HillStartAssist : 57|1@1+ (1,0) [0|1] "" Getriebe_DQ_Hybrid_MQB,Getriebe_DQ_MQB
 SG_ ESP_Decel_EPB_Active : 58|1@1+ (1,0) [0|1] "" Vector__XXX
 SG_ ECD_BrakeLight : 59|1@1+ (1,0) [0|1] "" Motor_Diesel_MQB,Motor_Hybrid_MQB,Motor_Otto_MQB
 SG_ ESP_Decel_EPB_Avail : 60|1@1+ (1,0) [0|1] "" Vector__XXX
 SG_ ESP_Status_BrakePressure : 61|1@1+ (1,0) [0|1] "" Motor_Diesel_MQB,Motor_Hybrid_MQB,Motor_Otto_MQB
 SG_ ESP_Request_EPB : 62|2@1+ (1,0) [0|3] "" Vector__XXX

BO_ 914 ESP_07: 8 Gateway_MQB
 SG_ ESP_07_CRC : 0|8@1+ (1,0) [0|255] "" Airbag_MQB,Motor_Diesel_MQB,Motor_Hybrid_MQB,Motor_Otto_MQB
 SG_ ESP_07_BZ : 8|4@1+ (1,0) [0|15] "" Airbag_MQB,Motor_Diesel_MQB,Motor_Hybrid_MQB,Motor_Otto_MQB
 SG_ ESP_ACC_LDE : 12|1@1+ (1,0) [0|1] "" Vector__XXX
 SG_ ESP_Quattro_Drive : 13|1@1+ (1,0) [0|1] "" Vector__XXX
 SG_ ESP_Coding_ADS : 14|2@1+ (1,0) [0|3] "" Vector__XXX
 SG_ ESP_RTA_HL : 16|8@1+ (0.048828125,-6.20117) [-6.20117|6.152345625] "Unit_PerCent" Vector__XXX
 SG_ ESP_RTA_HR : 24|8@1+ (0.048828125,-6.20117) [-6.20117|6.152345625] "Unit_PerCent" Vector__XXX
 SG_ ESP_RTA_VR : 32|8@1+ (0.048828125,-6.20117) [-6.20117|6.152345625] "Unit_PerCent" Vector__XXX
 SG_ OBD_Error_WheelSensor_HL : 40|4@1+ (1,0) [0|15] "" Motor_Diesel_MQB,Motor_Hybrid_MQB,Motor_Otto_MQB
 SG_ OBD_Error_WheelSensor_HR : 44|4@1+ (1,0) [0|15] "" Motor_Diesel_MQB,Motor_Hybrid_MQB,Motor_Otto_MQB
 SG_ OBD_Error_WheelSensor_VL : 48|4@1+ (1,0) [0|15] "" Motor_Diesel_MQB,Motor_Hybrid_MQB,Motor_Otto_MQB
 SG_ OBD_Error_WheelSensor_VR : 52|4@1+ (1,0) [0|15] "" Motor_Diesel_MQB,Motor_Hybrid_MQB,Motor_Otto_MQB
 SG_ ESP_Qualification_DriveType : 56|1@1+ (1,0) [0|1] "" Vector__XXX
 SG_ ESP_Offroad_Mode : 57|1@1+ (1,0) [0|1] "" Vector__XXX
 SG_ ESP_MKB_ausloesbar : 58|1@1+ (1,0) [0|1] "" Airbag_MQB
 SG_ ESP_MKB_Status : 59|1@1+ (1,0) [0|1] "" Airbag_MQB
 SG_ ESP_CM_Variant : 60|1@1+ (1,0) [0|1] "" Vector__XXX
 SG_ ESP_OBD_Status : 61|1@1+ (1,0) [0|1] "" Vector__XXX

BO_ 278 ESP_10: 8 Gateway_MQB
 SG_ CHECKSUM : 0|8@1+ (1,0) [0|255] "" Airbag_MQB,Motor_Diesel_MQB,Motor_Hybrid_MQB,Motor_Otto_MQB
 SG_ COUNTER : 8|4@1+ (1,0) [0|15] "" Airbag_MQB,Motor_Diesel_MQB,Motor_Hybrid_MQB,Motor_Otto_MQB
 SG_ ESP_QBit_DistancePulse_VL : 12|1@1+ (1,0) [0|1] "" Getriebe_DQ_Hybrid_MQB,Getriebe_DQ_MQB,Motor_Diesel_MQB,Motor_Hybrid_MQB,Motor_Otto_MQB
 SG_ ESP_QBit_DistancePulse_VR : 13|1@1+ (1,0) [0|1] "" Getriebe_DQ_Hybrid_MQB,Getriebe_DQ_MQB,Motor_Diesel_MQB,Motor_Hybrid_MQB,Motor_Otto_MQB
 SG_ ESP_QBit_DistancePulse_HL : 14|1@1+ (1,0) [0|1] "" Getriebe_DQ_Hybrid_MQB,Getriebe_DQ_MQB,Motor_Diesel_MQB,Motor_Hybrid_MQB,Motor_Otto_MQB
 SG_ ESP_QBit_DistancePulse_HR : 15|1@1+ (1,0) [0|1] "" Getriebe_DQ_Hybrid_MQB,Getriebe_DQ_MQB,Motor_Diesel_MQB,Motor_Hybrid_MQB,Motor_Otto_MQB
 SG_ ESP_DistancePulse_VL : 16|10@1+ (1,0) [0|1000] "" Getriebe_DQ_Hybrid_MQB,Getriebe_DQ_MQB,Motor_Diesel_MQB,Motor_Hybrid_MQB,Motor_Otto_MQB
 SG_ ESP_DistancePulse_VR : 26|10@1+ (1,0) [0|1000] "" Getriebe_DQ_Hybrid_MQB,Getriebe_DQ_MQB,Motor_Diesel_MQB,Motor_Hybrid_MQB,Motor_Otto_MQB
 SG_ ESP_DistancePulse_HL : 36|10@1+ (1,0) [0|1000] "" Getriebe_DQ_Hybrid_MQB,Getriebe_DQ_MQB,Motor_Diesel_MQB,Motor_Hybrid_MQB,Motor_Otto_MQB
 SG_ ESP_DistancePulse_HR : 46|10@1+ (1,0) [0|1000] "" Getriebe_DQ_Hybrid_MQB,Getriebe_DQ_MQB,Motor_Diesel_MQB,Motor_Hybrid_MQB,Motor_Otto_MQB
 SG_ ESP_VL_Direction : 56|2@1+ (1,0) [0|3] "" Airbag_MQB,Getriebe_DQ_Hybrid_MQB,Getriebe_DQ_MQB,Motor_Diesel_MQB,Motor_Hybrid_MQB,Motor_Otto_MQB
 SG_ ESP_VR_Direction : 58|2@1+ (1,0) [0|3] "" Airbag_MQB,Getriebe_DQ_Hybrid_MQB,Getriebe_DQ_MQB,Motor_Diesel_MQB,Motor_Hybrid_MQB,Motor_Otto_MQB
 SG_ ESP_HL_Direction : 60|2@1+ (1,0) [0|3] "" Airbag_MQB,Getriebe_DQ_Hybrid_MQB,Getriebe_DQ_MQB,Motor_Diesel_MQB,Motor_Hybrid_MQB,Motor_Otto_MQB
 SG_ ESP_HR_Direction : 62|2@1+ (1,0) [0|3] "" Airbag_MQB,Getriebe_DQ_Hybrid_MQB,Getriebe_DQ_MQB,Motor_Diesel_MQB,Motor_Hybrid_MQB,Motor_Otto_MQB

BO_ 178 ESP_19: 8 Gateway_MQB
 SG_ ESP_HL_WheelSpeed_02 : 0|16@1+ (0.0075,0) [0|491.49] "Unit_KiloMeterPerHour" Airbag_MQB,Getriebe_DQ_Hybrid_MQB,Getriebe_DQ_MQB,Motor_Diesel_MQB,Motor_Hybrid_MQB,Motor_Otto_MQB
 SG_ ESP_HR_WheelSpeed_02 : 16|16@1+ (0.0075,0) [0|491.49] "Unit_KiloMeterPerHour" Airbag_MQB,Getriebe_DQ_Hybrid_MQB,Getriebe_DQ_MQB,Motor_Diesel_MQB,Motor_Hybrid_MQB,Motor_Otto_MQB
 SG_ ESP_VL_WheelSpeed_02 : 32|16@1+ (0.0075,0) [0|491.49] "Unit_KiloMeterPerHour" Airbag_MQB,Getriebe_DQ_Hybrid_MQB,Getriebe_DQ_MQB,Motor_Diesel_MQB,Motor_Hybrid_MQB,Motor_Otto_MQB
 SG_ ESP_VR_WheelSpeed_02 : 48|16@1+ (0.0075,0) [0|491.49] "Unit_KiloMeterPerHour" Airbag_MQB,Getriebe_DQ_Hybrid_MQB,Getriebe_DQ_MQB,Motor_Diesel_MQB,Motor_Hybrid_MQB,Motor_Otto_MQB

BO_ 1629 ESP_20: 8 Gateway_MQB
 SG_ CHECKSUM : 0|8@1+ (1,0) [0|255] ""  XXX
 SG_ COUNTER : 8|4@1+ (1,0) [0|15] ""  XXX
 SG_ BR_SystemType : 12|2@1+ (1,0) [0|3] ""  XXX
 SG_ ESP_VoltageReq_02 : 14|2@1+ (1,0) [0|3] ""  XXX
 SG_ ESP_ToothCount : 16|8@1+ (1,0) [0|255] ""  XXX
 SG_ ESP_Charisma_DrivePr : 24|4@1+ (1,0) [0|15] ""  XXX
 SG_ ESP_Charisma_Status : 28|2@1+ (1,0) [0|3] ""  XXX
 SG_ ESP_Restart_Disp_01 : 30|1@1+ (1,0) [0|1] ""  XXX
 SG_ ESP_Restart_Disp_02 : 31|1@1+ (1,0) [0|1] ""  XXX
 SG_ ESP_Restart_Disp_03 : 32|1@1+ (1,0) [0|1] ""  XXX
 SG_ ESP_Restart_Disp_04 : 33|1@1+ (1,0) [0|1] ""  XXX
 SG_ ESP_StopInhibit_Disp_01 : 34|1@1+ (1,0) [0|1] ""  XXX
 SG_ ESP_StopInhibit_Disp_02 : 35|1@1+ (1,0) [0|1] ""  XXX
 SG_ ESP_StopInhibit_Disp_03 : 36|1@1+ (1,0) [0|1] ""  XXX
 SG_ ESP_StopInhibit_Disp_04 : 37|1@1+ (1,0) [0|1] ""  XXX
 SG_ ESP_StopInhibit_Disp_05 : 38|1@1+ (1,0) [0|1] ""  XXX
 SG_ ESP_StopInhibit_Disp_06 : 39|1@1+ (1,0) [0|1] ""  XXX
 SG_ ESP_StopInhibit_Disp_07 : 40|1@1+ (1,0) [0|1] ""  XXX
 SG_ ESP_StopInhibit_Disp_Std : 41|1@1+ (1,0) [0|1] ""  XXX
 SG_ ESP_Dachrelingsensor : 42|2@1+ (1,0) [0|3] ""  XXX
 SG_ ESP_StopInhibit_Disp_08 : 44|1@1+ (1,0) [0|1] ""  XXX
 SG_ HDC_Charisma_DrivePr : 45|4@1+ (1,0) [0|15] ""  XXX
 SG_ HDC_Charisma_Status : 49|2@1+ (1,0) [0|3] ""  XXX
 SG_ BR_QBit_TyreCircumference : 51|1@1+ (1,0) [0|1] ""  XXX
 SG_ BR_TyreCircumference : 52|12@1+ (1,0) [0|4095] "Unit_MilliMeter"  XXX

BO_ 253 ESP_21: 8 Gateway_MQB
 SG_ CHECKSUM : 0|8@1+ (1,0) [0|255] ""  XXX
 SG_ COUNTER : 8|4@1+ (1,0) [0|15] ""  XXX
 SG_ BR_InterventionTorque : 12|10@1+ (1,-509) [-509|509] ""  XXX
 SG_ ESP_PLA_BrakeIntervention : 22|1@1+ (1.0,0.0) [0.0|1] ""  XXX
 SG_ ESP_Diagnostics : 23|1@1+ (1.0,0.0) [0.0|1] ""  XXX
 SG_ ESC_Recup_Enable : 24|1@1+ (1.0,0.0) [0.0|1] ""  XXX
 SG_ ESC_v_Signal_Qualifier_High_Low : 25|3@1+ (1.0,0.0) [0.0|7] ""  XXX
 SG_ ESP_BeforeControl : 28|1@1+ (1.0,0.0) [0.0|1] ""  XXX
 SG_ ESP_AWV3_Brake_Active : 29|1@1+ (1.0,0.0) [0.0|1] ""  XXX
 SG_ OBD_RoughRoad : 30|1@1+ (1.0,0.0) [0.0|1] ""  XXX
 SG_ OBD_QBit_RoughRoad : 31|1@1+ (1.0,0.0) [0.0|1] ""  XXX
 SG_ ESP_v_Signal : 32|16@1+ (0.01,0) [0.00|655.32] "Unit_KiloMeterPerHour"  XXX
 SG_ ASR_Keying_Passive : 48|1@1+ (1.0,0.0) [0.0|1] ""  XXX
 SG_ ESP_Keying_Passive : 49|1@1+ (1.0,0.0) [0.0|1] ""  XXX
 SG_ ESP_SystemStatus : 50|1@1+ (1.0,0.0) [0.0|1] ""  XXX
 SG_ ASR_ShiftIntervention : 51|2@1+ (1.0,0.0) [0.0|3] ""  XXX
 SG_ ESP_Haltebestaetigung : 53|1@1+ (1.0,0.0) [0.0|1] ""  XXX
 SG_ ESP_MKB_Abort_Speed : 54|1@1+ (1.0,0.0) [0.0|1] ""  XXX
 SG_ ESP_QBit_v_Signal : 55|1@1+ (1.0,0.0) [0.0|1] ""  XXX
 SG_ ABS_Braking : 56|1@1+ (1.0,0.0) [0.0|1] ""  XXX
 SG_ ASR_Req : 57|1@1+ (1.0,0.0) [0.0|1] ""  XXX
 SG_ MSR_Req : 58|1@1+ (1.0,0.0) [0.0|1] ""  XXX
 SG_ EBV_Intervention : 59|1@1+ (1.0,0.0) [0.0|1] ""  XXX
 SG_ EDS_Intervention : 60|1@1+ (1.0,0.0) [0.0|1] ""  XXX
 SG_ ESP_Intervention : 61|1@1+ (1.0,0.0) [0.0|1] ""  XXX
 SG_ ESP_ASP : 62|1@1+ (1.0,0.0) [0.0|1] ""  XXX
 SG_ ESP_TrailerOldBeforeGear_ACC_Active : 63|1@1+ (1.0,0.0) [0.0|1] ""  XXX

BO_ 987 Gateway_72: 8 Gateway_MQB
 SG_ BCM_01_Old : 0|1@1+ (1,0) [0|1] "" Airbag_MQB
 SG_ SMLS_01_Old : 1|1@1+ (1,0) [0|1] "" Motor_Diesel_MQB,Motor_Otto_MQB
 SG_ ZV_02_Old : 2|1@1+ (1,0) [0|1] "" Getriebe_DQ_Hybrid_MQB,Getriebe_DQ_MQB,Motor_Diesel_MQB,Motor_Hybrid_MQB,Motor_Otto_MQB
 SG_ Wiper_01_Old : 3|1@1+ (1,0) [0|1] "" Motor_Diesel_MQB,Motor_Hybrid_MQB,Motor_Otto_MQB
 SG_ Trailer_01_Old : 4|1@1+ (1,0) [0|1] "" Getriebe_DQ_Hybrid_MQB,Getriebe_DQ_MQB
 SG_ Climate_Sensor_02_Old : 5|1@1+ (1,0) [0|1] "" Getriebe_DQ_Hybrid_MQB,Getriebe_DQ_MQB,Motor_Diesel_MQB,Motor_Hybrid_MQB,Motor_Otto_MQB
 SG_ VSG_01_Old : 6|1@1+ (1,0) [0|1] "" Airbag_MQB
 SG_ Climate_01_Old : 7|1@1+ (1,0) [0|1] "" Vector__XXX
 SG_ WFS_01_Old : 8|1@1+ (1,0) [0|1] "" Vector__XXX
 SG_ Light_Req_01_Old : 9|1@1+ (1,0) [0|1] "" Vector__XXX
 SG_ ZV_HFS_Open : 20|1@1+ (1,0) [0|1] "" Vector__XXX
 SG_ ZV_HBFS_Open : 21|1@1+ (1,0) [0|1] "" Vector__XXX
 SG_ VS_VD_Open_ver : 22|1@1+ (1,0) [0|1] "" Airbag_MQB
 SG_ VS_VD_Closed_ver : 23|1@1+ (1,0) [0|1] "" Vector__XXX
 SG_ ZV_BT_Open : 24|1@1+ (1,0) [0|1] "" Vector__XXX
 SG_ BCM1_ReversingLight_Switch : 25|1@1+ (1,0) [0|1] "" Airbag_MQB
 SG_ ZV_FT_Open : 26|1@1+ (1,0) [0|1] "" Getriebe_DQ_Hybrid_MQB,Getriebe_DQ_MQB,Motor_Diesel_MQB,Motor_Hybrid_MQB,Motor_Otto_MQB
 SG_ Wiper_Front_Active : 27|1@1+ (1,0) [0|1] "" Motor_Diesel_MQB,Motor_Hybrid_MQB,Motor_Otto_MQB
 SG_ AAG_Trailer_Detected : 28|1@1+ (1,0) [0|1] "" Getriebe_DQ_Hybrid_MQB,Getriebe_DQ_MQB
 SG_ BCM1_MH_Switch : 29|1@1+ (1,0) [0|1] "" Vector__XXX
 SG_ ZV_HD_Open : 30|1@1+ (1,0) [0|1] "" Vector__XXX
 SG_ Wash_Front_Active : 31|1@1+ (1,0) [0|1] "" Vector__XXX
 SG_ TERM_ThermalManagement : 32|2@1+ (1,0) [0|3] "" Vector__XXX
 SG_ WFS_Key_DriveAuthorisation : 34|4@1+ (1,0) [0|15] "" Vector__XXX
 SG_ BCM1_RHeadlights_Veh_Req : 38|1@1+ (1,0) [0|1] "" Vector__XXX
 SG_ BCM1_RHeadlights_Ahg_Req : 39|1@1+ (1,0) [0|1] "" Vector__XXX
 SG_ BH_HighBeam : 49|1@1+ (1,0) [0|1] "" Vector__XXX
 SG_ BH_Indicator_Left : 50|1@1+ (1,0) [0|1] "" Motor_Diesel_MQB,Motor_Otto_MQB
 SG_ BH_Indicator_Right : 51|1@1+ (1,0) [0|1] "" Motor_Diesel_MQB,Motor_Otto_MQB
 SG_ BCM1_OBD_FStatus_ATemp : 52|4@1+ (1,0) [0|15] "" Getriebe_DQ_Hybrid_MQB,Getriebe_DQ_MQB,Motor_Diesel_MQB,Motor_Hybrid_MQB,Motor_Otto_MQB
 SG_ BCM1_Outside_Temp_Unfilt : 56|8@1+ (0.5,-50) [-50|76] "Unit_DegreCelsi" Getriebe_DQ_Hybrid_MQB,Getriebe_DQ_MQB,Motor_Diesel_MQB,Motor_Hybrid_MQB,Motor_Otto_MQB

BO_ 989 Gateway_74: 8 Gateway_MQB
 SG_ LH_EPS_01_Old : 0|1@1+ (1,0) [0|1] "" Motor_Diesel_MQB
 SG_ Kessy_04_Old : 1|1@1+ (1,0) [0|1] "" Motor_Diesel_MQB,Motor_Otto_MQB
 SG_ LIN_2_Old : 2|1@1+ (1,0) [0|1] "" Getriebe_DQ_Hybrid_MQB,Getriebe_DQ_MQB
 SG_ MFG_01_Old : 3|1@1+ (1,0) [0|1] "" Motor_Diesel_MQB,Motor_Otto_MQB
 SG_ GW_74_va_14 : 4|1@1+ (1,0) [0|1] "" Vector__XXX
 SG_ Climate_02_Old : 5|1@1+ (1,0) [0|1] "" BMS_MQB
 SG_ ParkAssist_01_Old : 6|1@1+ (1,0) [0|1] "" Motor_Diesel_MQB,Motor_Otto_MQB
 SG_ ELV_01_Old : 7|1@1+ (1,0) [0|1] "" Motor_Diesel_MQB,Motor_Hybrid_MQB,Motor_Otto_MQB
 SG_ KY_StartStop_Info : 16|2@1+ (1,0) [0|3] "" Motor_Diesel_MQB,Motor_Otto_MQB
 SG_ PH_StartStop_Info : 18|2@1+ (1,0) [0|3] "" Motor_Diesel_MQB,Motor_Otto_MQB
 SG_ EPS_HandlebarPosition : 20|2@1+ (1,0) [0|3] "" Motor_Diesel_MQB
 SG_ ELV_Req_Terminal_50 : 22|1@1+ (1,0) [0|1] "" Motor_Diesel_MQB,Motor_Hybrid_MQB,Motor_Otto_MQB
 SG_ MF_StartStop_Info : 25|2@1+ (1,0) [0|3] "" Motor_Diesel_MQB,Motor_Otto_MQB
 SG_ TERM_BlowerVoltage_Target : 40|8@1+ (0.05,0.5) [2|13] "Unit_Volt" BMS_MQB
 SG_ TERM_RecirculationFlap_Status : 48|4@1+ (1,0) [0|15] "" Vector__XXX
 SG_ MFL_Tip_Down : 56|1@1+ (1,0) [0|1] "" Getriebe_DQ_Hybrid_MQB,Getriebe_DQ_MQB
 SG_ MFL_Tip_Up : 57|1@1+ (1,0) [0|1] "" Getriebe_DQ_Hybrid_MQB,Getriebe_DQ_MQB
 SG_ LS_Tiptronic_Error : 58|1@1+ (1,0) [0|1] "" Getriebe_DQ_Hybrid_MQB,Getriebe_DQ_MQB

BO_ 296 Gearbox_06: 3 Getriebe_DQ_Hybrid_MQB
 SG_ GE_WH_Lock : 0|1@1+ (1,0) [0|1] "" Waehlhebel_MQB
 SG_ GE_Ausleuchtungsmode : 1|1@1+ (1,0) [0|1] "" Waehlhebel_MQB
 SG_ GE_Test_Enable : 2|1@1+ (1,0) [0|1] "" Waehlhebel_MQB
 SG_ GE_Actual_DriveRange : 4|4@1+ (1,0) [0|15] "" Waehlhebel_MQB
 SG_ GE_TestParameter_1 : 8|8@1+ (1,0) [0|255] "" Waehlhebel_MQB
 SG_ GE_TestParameter_2 : 16|8@1+ (1,0) [0|255] "" Waehlhebel_MQB

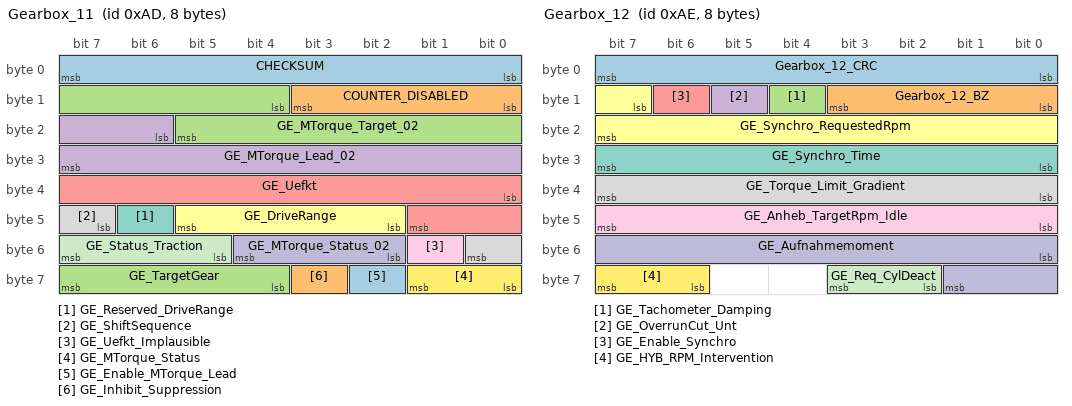
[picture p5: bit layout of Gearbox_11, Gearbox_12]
BO_ 173 Gearbox_11: 8 Getriebe_DQ_Hybrid_MQB
 SG_ CHECKSUM : 0|8@1+ (1,0) [0|255] ""  XXX
 SG_ COUNTER_DISABLED : 8|4@1+ (1,0) [0|15] ""  XXX
 SG_ GE_MTorque_Target_02 : 12|10@1+ (1,-509) [-509|509] ""  XXX
 SG_ GE_MTorque_Lead_02 : 22|10@1+ (1,-509) [-509|509] ""  XXX
 SG_ GE_Uefkt : 32|10@1+ (0.1,0) [0|102.2] ""  XXX
 SG_ GE_DriveRange : 42|4@1+ (1,0) [0|15] ""  XXX
 SG_ GE_Reserved_DriveRange : 46|1@1+ (1,0) [0|1] ""  XXX
 SG_ GE_ShiftSequence : 47|2@1+ (1,0) [0|3] ""  XXX
 SG_ GE_Uefkt_Implausible : 49|1@1+ (1,0) [0|1] ""  XXX
 SG_ GE_MTorque_Status_02 : 50|3@1+ (1,0) [0|7] ""  XXX
 SG_ GE_Status_Traction : 53|3@1+ (1,0) [0|7] ""  XXX
 SG_ GE_MTorque_Status : 56|2@1+ (1,0) [0|3] ""  XXX
 SG_ GE_Enable_MTorque_Lead : 58|1@1+ (1,0) [0|1] ""  XXX
 SG_ GE_Inhibit_Suppression : 59|1@1+ (1,0) [0|1] ""  XXX
 SG_ GE_TargetGear : 60|4@1+ (1,0) [0|15] ""  XXX

BO_ 174 Gearbox_12: 8 Getriebe_DQ_Hybrid_MQB
 SG_ Gearbox_12_CRC : 0|8@1+ (1,0) [0|255] "" Motor_Diesel_MQB,Motor_Hybrid_MQB,Motor_Otto_MQB
 SG_ Gearbox_12_BZ : 8|4@1+ (1,0) [0|15] "" Motor_Diesel_MQB,Motor_Hybrid_MQB,Motor_Otto_MQB
 SG_ GE_Tachometer_Damping : 12|1@1+ (1,0) [0|1] "" Motor_Diesel_MQB,Motor_Hybrid_MQB,Motor_Otto_MQB
 SG_ GE_OverrunCut_Unt : 13|1@1+ (1,0) [0|1] "" Motor_Diesel_MQB,Motor_Hybrid_MQB,Motor_Otto_MQB
 SG_ GE_Enable_Synchro : 14|1@1+ (1,0) [0|1] "" Motor_Diesel_MQB,Motor_Hybrid_MQB,Motor_Otto_MQB
 SG_ GE_Synchro_RequestedRpm : 15|9@1+ (25,0) [0|12750] "Unit_MinutInver" Motor_Diesel_MQB,Motor_Hybrid_MQB,Motor_Otto_MQB
 SG_ GE_Synchro_Time : 24|8@1+ (20,0) [0|5080] "Unit_MilliSecon" Motor_Diesel_MQB,Motor_Hybrid_MQB,Motor_Otto_MQB
 SG_ GE_Torque_Limit_Gradient : 32|8@1+ (10,0) [0|2540] "Unit_NewtoMeterPerSecon" Motor_Diesel_MQB,Motor_Hybrid_MQB,Motor_Otto_MQB
 SG_ GE_Anheb_TargetRpm_Idle : 40|8@1+ (10,0) [0|2540] "Unit_MinutInver" Motor_Diesel_MQB,Motor_Hybrid_MQB,Motor_Otto_MQB
 SG_ GE_Aufnahmemoment : 48|10@1+ (1,-509) [-509|509] "Unit_NewtoMeter" Motor_Diesel_MQB,Motor_Hybrid_MQB,Motor_Otto_MQB
 SG_ GE_Req_CylDeact : 58|2@1+ (1,0) [0|3] "" Vector__XXX
 SG_ GE_HYB_RPM_Intervention : 62|2@1+ (1,0) [0|3] "" Motor_Hybrid_MQB

BO_ 301 Gearbox_13: 8 Getriebe_DQ_Hybrid_MQB
 SG_ Gearbox_13_CRC : 0|8@1+ (1,0) [0|255] "" Motor_Diesel_MQB,Motor_Hybrid_MQB,Motor_Otto_MQB
 SG_ Gearbox_13_BZ : 8|4@1+ (1,0) [0|15] "" Motor_Diesel_MQB,Motor_Hybrid_MQB,Motor_Otto_MQB
 SG_ GE_StartStop_Info : 12|2@1+ (1,0) [0|3] "" Motor_Diesel_MQB,Motor_Otto_MQB
 SG_ GE_Langfr_ProtectionTorque_02 : 14|9@1+ (1,0) [0|509] "Unit_NewtoMeter" Motor_Diesel_MQB,Motor_Hybrid_MQB,Motor_Otto_MQB
 SG_ GE_InputSpeed : 48|14@1+ (1,0) [0|16381] "Unit_MinutInver" Motor_Diesel_MQB,Motor_Hybrid_MQB,Motor_Otto_MQB
 SG_ GE_LimpHome : 62|1@1+ (1,0) [0|1] "" Gateway_MQB,Motor_Diesel_MQB,Motor_Hybrid_MQB,Motor_Otto_MQB
 SG_ GE_Enable_Langfr_ProtectionTorque : 63|1@1+ (1,0) [0|1] "" Motor_Diesel_MQB,Motor_Hybrid_MQB,Motor_Otto_MQB

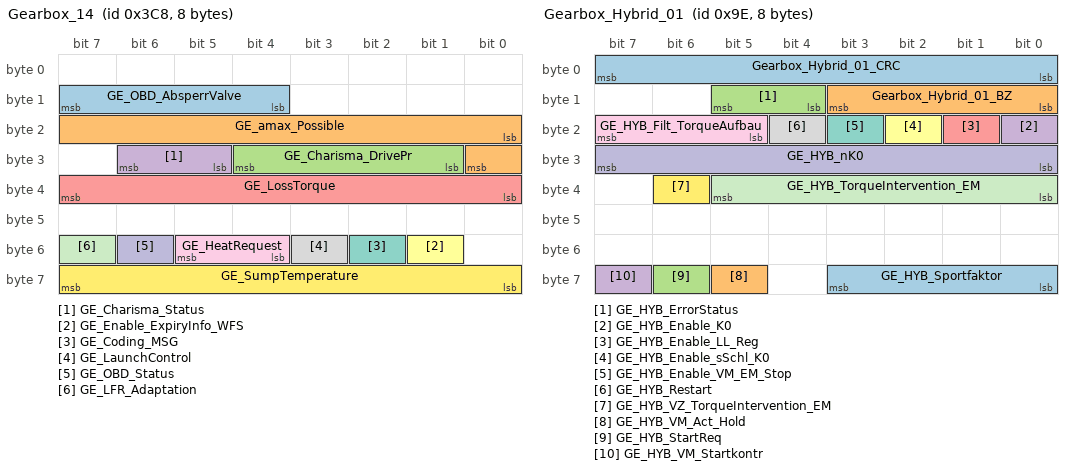
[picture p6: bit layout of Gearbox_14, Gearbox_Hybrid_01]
BO_ 968 Gearbox_14: 8 Getriebe_DQ_Hybrid_MQB
 SG_ GE_OBD_AbsperrValve : 12|4@1+ (1,0) [0|15] "" Gateway_MQB,Motor_Diesel_MQB,Motor_Hybrid_MQB,Motor_Otto_MQB
 SG_ GE_amax_Possible : 16|9@1+ (0.024,-2.016) [-2.016|10.224] "Unit_MeterPerSeconSquar" Gateway_MQB,Motor_Diesel_MQB,Motor_Hybrid_MQB,Motor_Otto_MQB
 SG_ GE_Charisma_DrivePr : 25|4@1+ (1,0) [0|15] "" Gateway_MQB
 SG_ GE_Charisma_Status : 29|2@1+ (1,0) [0|3] "" Gateway_MQB
 SG_ GE_LossTorque : 32|8@1+ (1,0) [0|254] "" Gateway_MQB,Motor_Diesel_MQB,Motor_Hybrid_MQB,Motor_Otto_MQB
 SG_ GE_Enable_ExpiryInfo_WFS : 49|1@1+ (1,0) [0|1] "" Gateway_MQB
 SG_ GE_Coding_MSG : 50|1@1+ (1,0) [0|1] "" Gateway_MQB
 SG_ GE_LaunchControl : 51|1@1+ (1,0) [0|1] "" Gateway_MQB
 SG_ GE_HeatRequest : 52|2@1+ (1,0) [0|3] "" Gateway_MQB,Motor_Diesel_MQB,Motor_Hybrid_MQB,Motor_Otto_MQB
 SG_ GE_OBD_Status : 54|1@1+ (1,0) [0|1] "" Gateway_MQB,Motor_Diesel_MQB,Motor_Hybrid_MQB,Motor_Otto_MQB
 SG_ GE_LFR_Adaptation : 55|1@1+ (1,0) [0|1] "" Gateway_MQB,Motor_Diesel_MQB,Motor_Hybrid_MQB,Motor_Otto_MQB
 SG_ GE_SumpTemperature : 56|8@1+ (1,-58) [-58|196] "Unit_DegreCelsi" Gateway_MQB,Motor_Diesel_MQB,Motor_Hybrid_MQB,Motor_Otto_MQB

BO_ 158 Gearbox_Hybrid_01: 8 Getriebe_DQ_Hybrid_MQB
 SG_ Gearbox_Hybrid_01_CRC : 0|8@1+ (1,0) [0|255] "" Motor_Hybrid_MQB
 SG_ Gearbox_Hybrid_01_BZ : 8|4@1+ (1,0) [0|15] "" Motor_Hybrid_MQB
 SG_ GE_HYB_ErrorStatus : 12|2@1+ (1,0) [0|3] "" Motor_Hybrid_MQB
 SG_ GE_HYB_Enable_K0 : 16|1@1+ (1,0) [0|1] "" Motor_Hybrid_MQB
 SG_ GE_HYB_Enable_LL_Reg : 17|1@1+ (1,0) [0|1] "" Motor_Hybrid_MQB
 SG_ GE_HYB_Enable_sSchl_K0 : 18|1@1+ (1,0) [0|1] "" Motor_Hybrid_MQB
 SG_ GE_HYB_Enable_VM_EM_Stop : 19|1@1+ (1,0) [0|1] "" Motor_Hybrid_MQB
 SG_ GE_HYB_Restart : 20|1@1+ (1,0) [0|1] "" Motor_Hybrid_MQB
 SG_ GE_HYB_Filt_TorqueAufbau : 21|3@1+ (1,0) [0|7] "" Motor_Hybrid_MQB
 SG_ GE_HYB_nK0 : 24|8@1+ (25,0) [0|6350] "Unit_MinutInver" Vector__XXX
 SG_ GE_HYB_TorqueIntervention_EM : 32|6@1+ (0.5,0) [0|31.5] "Unit_NewtoMeter" LEH_MQB
 SG_ GE_HYB_VZ_TorqueIntervention_EM : 38|1@1+ (1,0) [0|1] "" LEH_MQB
 SG_ GE_HYB_Sportfaktor : 56|4@1+ (1,0) [0|15] "" Motor_Hybrid_MQB
 SG_ GE_HYB_VM_Act_Hold : 61|1@1+ (1,0) [0|1] "" Motor_Hybrid_MQB
 SG_ GE_HYB_StartReq : 62|1@1+ (1,0) [0|1] "" Motor_Hybrid_MQB
 SG_ GE_HYB_VM_Startkontr : 63|1@1+ (1,0) [0|1] "" Motor_Hybrid_MQB

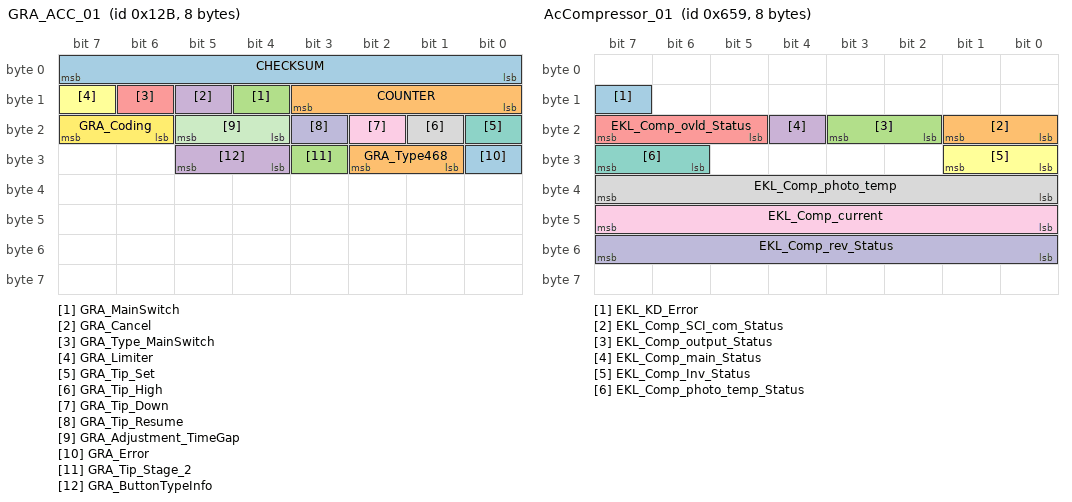
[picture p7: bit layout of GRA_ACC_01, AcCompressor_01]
BO_ 299 GRA_ACC_01: 8 Gateway_MQB
 SG_ CHECKSUM : 0|8@1+ (1,0) [0|255] "" Motor_Diesel_MQB,Motor_Hybrid_MQB,Motor_Otto_MQB
 SG_ COUNTER : 8|4@1+ (1,0) [0|15] "" Motor_Diesel_MQB,Motor_Hybrid_MQB,Motor_Otto_MQB
 SG_ GRA_MainSwitch : 12|1@1+ (1,0) [0|1] "" Motor_Diesel_MQB,Motor_Hybrid_MQB,Motor_Otto_MQB
 SG_ GRA_Cancel : 13|1@1+ (1,0) [0|1] "" Motor_Diesel_MQB,Motor_Hybrid_MQB,Motor_Otto_MQB
 SG_ GRA_Type_MainSwitch : 14|1@1+ (1,0) [0|1] "" Motor_Diesel_MQB,Motor_Hybrid_MQB,Motor_Otto_MQB
 SG_ GRA_Limiter : 15|1@1+ (1,0) [0|1] "" Getriebe_DQ_Hybrid_MQB,Getriebe_DQ_MQB,Motor_Diesel_MQB,Motor_Hybrid_MQB,Motor_Otto_MQB
 SG_ GRA_Tip_Set : 16|1@1+ (1,0) [0|1] "" Getriebe_DQ_Hybrid_MQB,Getriebe_DQ_MQB,Motor_Diesel_MQB,Motor_Hybrid_MQB,Motor_Otto_MQB
 SG_ GRA_Tip_High : 17|1@1+ (1,0) [0|1] "" Getriebe_DQ_Hybrid_MQB,Getriebe_DQ_MQB,Motor_Diesel_MQB,Motor_Hybrid_MQB,Motor_Otto_MQB
 SG_ GRA_Tip_Down : 18|1@1+ (1,0) [0|1] "" Getriebe_DQ_Hybrid_MQB,Getriebe_DQ_MQB,Motor_Diesel_MQB,Motor_Hybrid_MQB,Motor_Otto_MQB
 SG_ GRA_Tip_Resume : 19|1@1+ (1,0) [0|1] "" Getriebe_DQ_Hybrid_MQB,Getriebe_DQ_MQB,Motor_Diesel_MQB,Motor_Hybrid_MQB,Motor_Otto_MQB
 SG_ GRA_Adjustment_TimeGap : 20|2@1+ (1,0) [0|3] "" Motor_Diesel_MQB,Motor_Hybrid_MQB,Motor_Otto_MQB
 SG_ GRA_Coding : 22|2@1+ (1,0) [0|3] "" Motor_Diesel_MQB,Motor_Hybrid_MQB,Motor_Otto_MQB
 SG_ GRA_Error : 24|1@1+ (1,0) [0|1] "" Getriebe_DQ_Hybrid_MQB,Getriebe_DQ_MQB,Motor_Diesel_MQB,Motor_Hybrid_MQB,Motor_Otto_MQB
 SG_ GRA_Type468 : 25|2@1+ (1,0) [0|3] "" Motor_Diesel_MQB,Motor_Hybrid_MQB,Motor_Otto_MQB
 SG_ GRA_Tip_Stage_2 : 27|1@1+ (1,0) [0|1] "" Motor_Diesel_MQB,Motor_Hybrid_MQB,Motor_Otto_MQB
 SG_ GRA_ButtonTypeInfo : 28|2@1+ (1,0) [0|1] "" Motor_Diesel_MQB,Motor_Hybrid_MQB,Motor_Otto_MQB

BO_ 960 Terminals_Status_01: 4 Gateway_MQB
 SG_ CHECKSUM : 0|8@1+ (1,0) [0|255] "" Airbag_MQB,BMS_MQB,Motor_Diesel_MQB,Motor_Hybrid_MQB,Motor_Otto_MQB
 SG_ COUNTER : 8|4@1+ (1,0) [0|15] "" Airbag_MQB,BMS_MQB,Motor_Diesel_MQB,Motor_Hybrid_MQB,Motor_Otto_MQB
 SG_ ZAS_Term_S : 16|1@1+ (1,0) [0|1] "" Vector__XXX
 SG_ ZAS_Term_15 : 17|1@1+ (1,0) [0|1] "" Airbag_MQB,BMS_MQB,Motor_Diesel_MQB,Motor_Hybrid_MQB,Motor_Otto_MQB
 SG_ ZAS_Term_X : 18|1@1+ (1,0) [0|1] "" Vector__XXX
 SG_ ZAS_Term_50 : 19|1@1+ (1,0) [0|1] "" Vector__XXX

BO_ 949 Climate_11: 8 Gateway_MQB
 SG_ TERM_Rpm_Trailer : 0|1@1+ (1,0) [0|1] "" Motor_Diesel_MQB,Motor_Hybrid_MQB,Motor_Otto_MQB
 SG_ TERM_PreWarn_Compressor_On : 1|1@1+ (1,0) [0|1] "" Motor_Diesel_MQB,Motor_Hybrid_MQB,Motor_Otto_MQB
 SG_ TERM_AC_Switch : 2|1@1+ (1,0) [0|1] "" Vector__XXX
 SG_ TERM_Compressor_Torque_Old : 3|1@1+ (1,0) [0|1] "" Vector__XXX
 SG_ TERM_Zones : 4|2@1+ (1,0) [0|3] "" Motor_Diesel_MQB,Motor_Hybrid_MQB,Motor_Otto_MQB
 SG_ TERM_PreWarn_AuxHeater_On : 6|1@1+ (1,0) [0|1] "" Vector__XXX
 SG_ TERM_State : 7|1@1+ (1,0) [0|1] "" Motor_Diesel_MQB,Motor_Hybrid_MQB,Motor_Otto_MQB
 SG_ TERM_Comp_rev_rq : 8|8@1+ (50,0) [0|8600] "Unit_MinutInver" Vector__XXX
 SG_ TERM_Charisma_DrivePr : 16|4@1+ (1,0) [0|15] "" Vector__XXX
 SG_ TERM_Charisma_Status : 20|2@1+ (1,0) [0|3] "" Vector__XXX
 SG_ TERM_Comp_enable : 23|1@1+ (1,0) [0|1] "" Vector__XXX
 SG_ TERM_Load_Compressor : 24|8@1+ (0.25,0) [0|63.5] "Unit_NewtoMeter" Motor_Diesel_MQB,Motor_Hybrid_MQB,Motor_Otto_MQB
 SG_ TERM_Voltage_Req : 32|2@1+ (1,0) [0|3] "" Vector__XXX
 SG_ TERM_ThermalManagement : 34|2@1+ (1,0) [0|3] "" Motor_Diesel_MQB,Motor_Hybrid_MQB,Motor_Otto_MQB
 SG_ TERM_StartStop_Info : 36|2@1+ (1,0) [0|3] "" Motor_Diesel_MQB,Motor_Otto_MQB
 SG_ TERM_Req_TERM : 40|8@1+ (0.4,0) [0|101.6] "Unit_PerCent" Motor_Diesel_MQB,Motor_Hybrid_MQB,Motor_Otto_MQB
 SG_ TERM_el_AuxHeater_Stage : 48|3@1+ (1,0) [0|7] "" Motor_Diesel_MQB

BO_ 1625 AcCompressor_01: 8 Gateway_MQB
 SG_ EKL_KD_Error : 15|1@1+ (1,0) [0|1] "" Vector__XXX
 SG_ EKL_Comp_SCI_com_Status : 16|2@1+ (1,0) [0|3] "" Vector__XXX
 SG_ EKL_Comp_output_Status : 18|2@1+ (1,0) [0|3] "" Vector__XXX
 SG_ EKL_Comp_main_Status : 20|1@1+ (1,0) [0|1] "" Vector__XXX
 SG_ EKL_Comp_ovld_Status : 21|3@1+ (1,0) [0|7] "" Vector__XXX
 SG_ EKL_Comp_Inv_Status : 24|2@1+ (1,0) [0|3] "" Vector__XXX
 SG_ EKL_Comp_photo_temp_Status : 30|2@1+ (1,0) [0|3] "" Vector__XXX
 SG_ EKL_Comp_photo_temp : 32|8@1+ (1,0) [0|254] "Unit_DegreCelsi" Vector__XXX
 SG_ EKL_Comp_current : 40|8@1+ (0.1,0) [0|25.4] "Unit_Amper" Motor_Hybrid_MQB
 SG_ EKL_Comp_rev_Status : 48|8@1+ (50,0) [0|8600] "Unit_MinutInver" Vector__XXX

BO_ 2549088277 KN_Airbag_01: 8 Airbag_MQB
 SG_ Airbag_01_CompressorProtection : 0|1@1+ (1,0) [0|1] "" Vector__XXX
 SG_ Airbag_01_RunOnType : 4|4@1+ (1,0) [0|15] "" Gateway_MQB
 SG_ FROM_KD_Error : 63|1@1+ (1,0) [0|1] "" Gateway_MQB

BO_ 2549088380 KN_EEngine_01: 8 LEH_MQB
 SG_ EEngine_CompressorProtection : 0|1@1+ (1,0) [0|1] "" Vector__XXX
 SG_ EEngine_RunOnType : 4|4@1+ (1,0) [0|15] "" Gateway_MQB
 SG_ EM_HYB_KD_Error : 63|1@1+ (1,0) [0|1] "" Gateway_MQB

BO_ 2549088375 KN_Gearbox_01: 8 Getriebe_DQ_Hybrid_MQB
 SG_ Gearbox_CompressorProtection : 0|1@1+ (1,0) [0|1] "" Vector__XXX
 SG_ Gearbox_RunOnType : 4|4@1+ (1,0) [0|15] "" Gateway_MQB
 SG_ GE_KD_Error : 63|1@1+ (1,0) [0|1] "" Gateway_MQB

BO_ 2549088379 KN_Hybrid_01: 8 BMS_MQB
 SG_ Hybrid_CompressorProtection : 0|1@1+ (1,0) [0|1] "" Vector__XXX
 SG_ Hybrid_RunOnType : 4|4@1+ (1,0) [0|15] "" Gateway_MQB
 SG_ BMS_HYB_KD_Error : 63|1@1+ (1,0) [0|1] "" Gateway_MQB

BO_ 2549088374 KN_MO_01: 8 Motor_Diesel_MQB
 SG_ Engine_CompressorProtection : 0|1@1+ (1,0) [0|1] "" Vector__XXX
 SG_ Engine_RunOnType : 4|4@1+ (1,0) [0|15] "" Gateway_MQB
 SG_ MO_KD_Error : 63|1@1+ (1,0) [0|1] "" Gateway_MQB

BO_ 2549088284 KN_SAK: 8 SAK_MQB
 SG_ SAK_CompressorProtection : 0|1@1+ (1,0) [0|1] "" Vector__XXX
 SG_ SAK_RunOnType : 4|4@1+ (1,0) [0|15] "" Gateway_MQB
 SG_ SAK_KD_Error : 63|1@1+ (1,0) [0|1] "" Gateway_MQB

BO_ 779 Cluster_01: 8 Gateway_MQB
 SG_ KBI_ABS_Lamp : 0|1@1+ (1,0) [0|1] "" Vector__XXX
 SG_ KBI_ESP_Lamp : 1|1@1+ (1,0) [0|1] "" Vector__XXX
 SG_ KBI_BKL_Lamp : 2|1@1+ (1,0) [0|1] "" Vector__XXX
 SG_ KBI_Airbag_Lamp : 3|1@1+ (1,0) [0|1] "" Airbag_MQB
 SG_ KBI_SILA_Valid : 4|1@1+ (1,0) [0|1] "" Airbag_MQB
 SG_ KBI_Steering_Lamp : 5|1@1+ (1,0) [0|1] "" Vector__XXX
 SG_ KBI_Preheat_System_Lamp : 6|1@1+ (1,0) [0|1] "" Motor_Diesel_MQB
 SG_ KBI_NV_in_Display : 7|1@1+ (1,0) [0|1] "" Vector__XXX
 SG_ Cluster_01_BZ : 8|4@1+ (1,0) [0|15] "" Motor_Diesel_MQB,Motor_Hybrid_MQB,Motor_Otto_MQB
 SG_ KBI_DisplayStatus_ACC : 12|1@1+ (1,0) [0|1] "" Vector__XXX
 SG_ KBI_DisplayStatus_GRA : 13|2@1+ (1,0) [0|3] "" Motor_Diesel_MQB,Motor_Hybrid_MQB,Motor_Otto_MQB
 SG_ KBI_OilPressure_Switch : 15|1@1+ (1,0) [0|1] "" Vector__XXX
 SG_ KBI_LowFuelWarning : 16|1@1+ (1,0) [0|1] "" Motor_Diesel_MQB,Motor_Hybrid_MQB,Motor_Otto_MQB
 SG_ KBI_MFA_v_Unit_01 : 17|1@1+ (1,0) [0|1] "" Motor_Diesel_MQB,Motor_Hybrid_MQB,Motor_Otto_MQB
 SG_ KBI_In_ActuatorTest : 18|1@1+ (1,0) [0|1] "" Airbag_MQB
 SG_ KBI_DisplayFault_LDW : 19|2@1+ (1,0) [0|3] "" Vector__XXX
 SG_ KBI_Variant_USA : 21|1@1+ (1,0) [0|1] "" Vector__XXX
 SG_ KBI_OilPressureWarning : 22|1@1+ (1,0) [0|1] "" Vector__XXX
 SG_ KBI_Handbrake : 23|1@1+ (1,0) [0|1] "" Getriebe_DQ_Hybrid_MQB,Getriebe_DQ_MQB
 SG_ KBI_V_Digital : 24|9@1+ (1,0) [0|511] "" Vector__XXX
 SG_ KBI_PLA_in_Display : 33|1@1+ (1,0) [0|1] "" Vector__XXX
 SG_ KBI_DisplayFault_NV : 34|1@1+ (1,0) [0|1] "" Vector__XXX
 SG_ KBI_DisplayStatus_LIM : 35|2@1+ (1,0) [0|3] "" Motor_Diesel_MQB,Motor_Hybrid_MQB,Motor_Otto_MQB
 SG_ KBI_Displayed_Speed : 48|10@1+ (0.32,0) [0|325.12] "Unit_KiloMeterPerHour" Getriebe_DQ_Hybrid_MQB,Getriebe_DQ_MQB,Motor_Diesel_MQB,Motor_Hybrid_MQB,Motor_Otto_MQB
 SG_ KBI_Unit_Speedo : 58|1@1+ (1,0) [0|1] "" Motor_Diesel_MQB,Motor_Hybrid_MQB,Motor_Otto_MQB
 SG_ KBI_Consistency_ACC : 59|1@1+ (1,0) [0|1] "" Vector__XXX
 SG_ KBI_Error_Display_ACC : 60|1@1+ (1,0) [0|1] "" Vector__XXX
 SG_ KBI_DisplayFault_SWA : 61|2@1+ (1,0) [0|3] "" Vector__XXX

BO_ 1719 Cluster_02: 8 Gateway_MQB
 SG_ KBI_Odometer : 0|20@1+ (1,0) [0|1048573] "Unit_KiloMeter" Vector__XXX
 SG_ KBI_ParkedTime_02 : 20|17@1+ (1,0) [0|131068] "Unit_Secon" Getriebe_DQ_Hybrid_MQB,Getriebe_DQ_MQB,Motor_Diesel_MQB,Motor_Hybrid_MQB,Motor_Otto_MQB
 SG_ KBI_Contents_Tank : 40|7@1+ (1,0) [0|125] "Unit_Liter" Motor_Diesel_MQB,Motor_Hybrid_MQB,Motor_Otto_MQB
 SG_ KBI_FStatus_Tank : 47|1@1+ (1,0) [0|1] "" Motor_Diesel_MQB,Motor_Hybrid_MQB,Motor_Otto_MQB
 SG_ KBI_QBit_Outside_Temp_Filt : 55|1@1+ (1,0) [0|1] "" Getriebe_DQ_Hybrid_MQB,Getriebe_DQ_MQB,Motor_Diesel_MQB,Motor_Hybrid_MQB,Motor_Otto_MQB
 SG_ KBI_Outside_Temp_Filt : 56|8@1+ (0.5,-50) [-50|75] "Unit_DegreCelsi" Getriebe_DQ_Hybrid_MQB,Getriebe_DQ_MQB,Motor_Diesel_MQB,Motor_Hybrid_MQB,Motor_Otto_MQB

BO_ 982 Light_Rear_01: 8 Gateway_MQB
 SG_ Light_Rear_01_BZ : 0|4@1+ (1,0) [0|15] "" Motor_Diesel_MQB,Motor_Hybrid_MQB,Motor_Otto_MQB
 SG_ BCM2_BrakeLight_By_ECD : 5|1@1+ (1,0) [0|1] "" Motor_Diesel_MQB,Motor_Hybrid_MQB,Motor_Otto_MQB
 SG_ LH_OutsideLight_def : 7|1@1+ (1,0) [0|1] "" Vector__XXX
 SG_ LH_SideLight_H_Active : 8|1@1+ (1,0) [0|1] "" Vector__XXX
 SG_ LH_ParkingLight_HL_Active : 9|1@1+ (1,0) [0|1] "" Vector__XXX
 SG_ LH_ParkingLight_HR_Active : 10|1@1+ (1,0) [0|1] "" Vector__XXX
 SG_ LH_BrakeLight_H_Active : 11|1@1+ (1,0) [0|1] "" Vector__XXX
 SG_ LH_RearFog_Active : 12|1@1+ (1,0) [0|1] "" Vector__XXX
 SG_ LH_ReversingLight_Active : 13|1@1+ (1,0) [0|1] "" Vector__XXX
 SG_ LH_Indicator_HL_Act : 14|1@1+ (1,0) [0|1] "" Vector__XXX
 SG_ LH_Indicator_HR_Act : 15|1@1+ (1,0) [0|1] "" Vector__XXX
 SG_ LH_Indicator_Left_def : 16|1@1+ (1,0) [0|1] "" Vector__XXX
 SG_ LH_BrakeLight_Left_def : 17|1@1+ (1,0) [0|1] "" Vector__XXX
 SG_ LH_TailLight_Left_def : 18|1@1+ (1,0) [0|1] "" Vector__XXX
 SG_ LH_Reverse_Left_def : 19|1@1+ (1,0) [0|1] "" Vector__XXX
 SG_ LH_Fog_Left_def : 20|1@1+ (1,0) [0|1] "" Vector__XXX
 SG_ LH_End_Brake_Fog_Left_def : 21|1@1+ (1,0) [0|1] "" Vector__XXX
 SG_ LH_End_Brake_Fog_Right_def : 22|1@1+ (1,0) [0|1] "" Vector__XXX
 SG_ LH_End_Brake_Left_def : 24|1@1+ (1,0) [0|1] "" Vector__XXX
 SG_ LH_End_Fog_Left_def : 25|1@1+ (1,0) [0|1] "" Vector__XXX
 SG_ LH_SL_BRL_BLK_Left_def : 26|1@1+ (1,0) [0|1] "" Vector__XXX
 SG_ LH_Brake_Blk_Left_def : 27|1@1+ (1,0) [0|1] "" Vector__XXX
 SG_ LH_Indicator_Right_def : 32|1@1+ (1,0) [0|1] "" Vector__XXX
 SG_ LH_BrakeLight_Right_def : 33|1@1+ (1,0) [0|1] "" Vector__XXX
 SG_ LH_TailLight_Right_def : 34|1@1+ (1,0) [0|1] "" Vector__XXX
 SG_ LH_Reverse_Right_def : 35|1@1+ (1,0) [0|1] "" Vector__XXX
 SG_ LH_Fog_Right_def : 36|1@1+ (1,0) [0|1] "" Vector__XXX
 SG_ LH_End_Brake_Right_def : 40|1@1+ (1,0) [0|1] "" Vector__XXX
 SG_ LH_End_Fog_Right_def : 41|1@1+ (1,0) [0|1] "" Vector__XXX
 SG_ LH_SL_BRL_BLK_Right_def : 42|1@1+ (1,0) [0|1] "" Vector__XXX
 SG_ LH_Brake_Blk_Right_def : 43|1@1+ (1,0) [0|1] "" Vector__XXX
 SG_ LH_Kennzl_def : 48|1@1+ (1,0) [0|1] "" Vector__XXX
 SG_ LH_3_BrakeLight_def : 49|1@1+ (1,0) [0|1] "" Motor_Diesel_MQB,Motor_Hybrid_MQB,Motor_Otto_MQB
 SG_ LH_Fog_mi_def : 50|1@1+ (1,0) [0|1] "" Vector__XXX
 SG_ LH_Reverse_mi_def : 51|1@1+ (1,0) [0|1] "" Vector__XXX
 SG_ LH_BrakeLight_Left_Total_def : 54|1@1+ (1,0) [0|1] "" Motor_Diesel_MQB,Motor_Hybrid_MQB,Motor_Otto_MQB
 SG_ LH_BrakeLight_Right_Total_def : 55|1@1+ (1,0) [0|1] "" Motor_Diesel_MQB,Motor_Hybrid_MQB,Motor_Otto_MQB

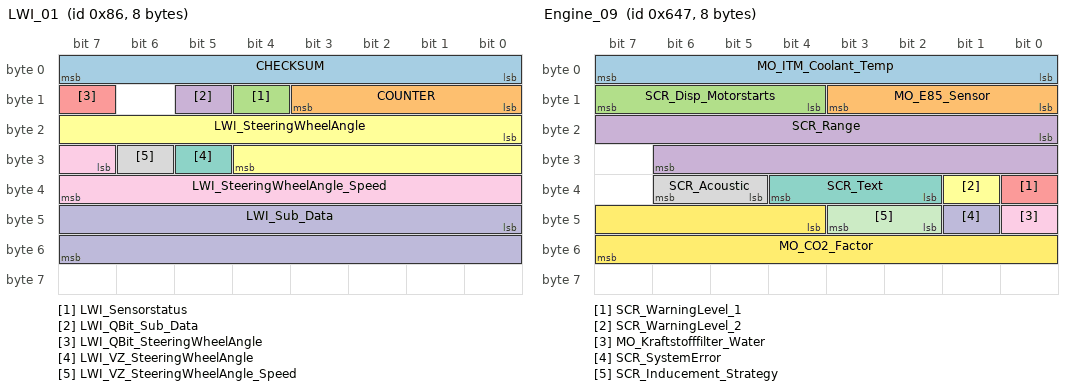
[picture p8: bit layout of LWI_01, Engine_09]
BO_ 134 LWI_01: 8 Gateway_MQB
 SG_ CHECKSUM : 0|8@1+ (1,0) [0|255] "" Airbag_MQB,Getriebe_DQ_Hybrid_MQB,Getriebe_DQ_MQB,Motor_Diesel_MQB,Motor_Hybrid_MQB,Motor_Otto_MQB
 SG_ COUNTER : 8|4@1+ (1,0) [0|15] "" Airbag_MQB,Getriebe_DQ_Hybrid_MQB,Getriebe_DQ_MQB,Motor_Diesel_MQB,Motor_Hybrid_MQB,Motor_Otto_MQB
 SG_ LWI_Sensorstatus : 12|1@1+ (1,0) [0|1] "" Airbag_MQB,Getriebe_DQ_Hybrid_MQB,Getriebe_DQ_MQB,Motor_Diesel_MQB,Motor_Hybrid_MQB,Motor_Otto_MQB
 SG_ LWI_QBit_Sub_Data : 13|1@1+ (1,0) [0|1] "" Vector__XXX
 SG_ LWI_QBit_SteeringWheelAngle : 15|1@1+ (1,0) [0|1] "" Airbag_MQB,Getriebe_DQ_Hybrid_MQB,Getriebe_DQ_MQB,Motor_Diesel_MQB,Motor_Hybrid_MQB,Motor_Otto_MQB
 SG_ LWI_SteeringWheelAngle : 16|13@1+ (0.1,0) [0|800] "Unit_DegreOfArc" Airbag_MQB,Getriebe_DQ_Hybrid_MQB,Getriebe_DQ_MQB,Motor_Diesel_MQB,Motor_Hybrid_MQB,Motor_Otto_MQB
 SG_ LWI_VZ_SteeringWheelAngle : 29|1@1+ (1,0) [0|1] "" Airbag_MQB,Getriebe_DQ_Hybrid_MQB,Getriebe_DQ_MQB,Motor_Diesel_MQB,Motor_Hybrid_MQB,Motor_Otto_MQB
 SG_ LWI_VZ_SteeringWheelAngle_Speed : 30|1@1+ (1,0) [0|1] "" Vector__XXX
 SG_ LWI_SteeringWheelAngle_Speed : 31|9@1+ (5,0) [0|2500] "Unit_DegreOfArcPerSecon" Vector__XXX
 SG_ LWI_Sub_Data : 40|16@1+ (1,0) [0|65535] "" Vector__XXX

BO_ 263 Engine_04: 8 Motor_Diesel_MQB
 SG_ MO_ActualGear : 8|4@1+ (1,0) [0|15] "" Gateway_MQB
 SG_ MO_TargetGear : 12|4@1+ (1,0) [0|15] "" Gateway_MQB
 SG_ MO_OilPressure : 16|8@1+ (0.04,0) [0|10] "Unit_Bar" Gateway_MQB
 SG_ MO_DisplayRpm : 24|12@1+ (3,0) [0|12282] "Unit_MinutInver" Gateway_MQB
 SG_ MO_ShiftRecommend_Available : 38|1@1+ (1,0) [0|1] "" Gateway_MQB
 SG_ MO_BoostPressure : 39|9@1+ (0.01,0) [0|5.1] "Unit_Bar" Gateway_MQB
 SG_ MO_KVS : 48|15@1+ (1,0) [0|32767] "Unit_MicroLiter" Gateway_MQB
 SG_ MO_KVS_Overflow : 63|1@1+ (1,0) [0|1] "" Gateway_MQB

BO_ 1600 Engine_07: 8 Motor_Diesel_MQB
 SG_ MO_QBit_IntakeAir_Temp : 0|1@1+ (1,0) [0|1] "" Gateway_MQB
 SG_ MO_QBit_Oil_Temp : 1|1@1+ (1,0) [0|1] "" Gateway_MQB,Getriebe_DQ_Hybrid_MQB,Getriebe_DQ_MQB
 SG_ MO_QBit_Coolant_Temp : 2|1@1+ (1,0) [0|1] "" Gateway_MQB,Getriebe_DQ_Hybrid_MQB,Getriebe_DQ_MQB,LEH_MQB
 SG_ MO_ActuatorTest_SoundActuator : 3|1@1+ (1,0) [0|1] "" Gateway_MQB
 SG_ MO_HYB_Error_HV_Network : 4|1@1+ (1,0) [0|1] "" Gateway_MQB
 SG_ MO_Active_GearboxHeat : 5|1@1+ (1,0) [0|1] "" Gateway_MQB,Getriebe_DQ_Hybrid_MQB,Getriebe_DQ_MQB
 SG_ MO_ShutOffValve_Open : 6|2@1+ (1,0) [0|3] "" Gateway_MQB
 SG_ MO_IntakeAir_Temp : 8|8@1+ (0.75,-48) [-48|141.75] "Unit_DegreCelsi" Gateway_MQB
 SG_ MO_Oil_Temp : 16|8@1+ (1,-60) [-60|192] "Unit_DegreCelsi" Gateway_MQB,Getriebe_DQ_Hybrid_MQB,Getriebe_DQ_MQB
 SG_ MO_Coolant_Temp : 24|8@1+ (0.75,-48) [-48|141.75] "Unit_DegreCelsi" Gateway_MQB,Getriebe_DQ_Hybrid_MQB,Getriebe_DQ_MQB,LEH_MQB
 SG_ MO_AltitudeInfo : 32|8@1+ (0.00781,0) [0|1.98374] "" Gateway_MQB,Getriebe_DQ_Hybrid_MQB,Getriebe_DQ_MQB
 SG_ MO_Kennfeldk : 40|1@1+ (1,0) [0|1] "" Gateway_MQB
 SG_ MO_VersionInfo : 41|6@1+ (1,0) [0|63] "" Gateway_MQB
 SG_ MO_Gearbox_Cool : 47|1@1+ (1,0) [0|1] "" Gateway_MQB,Getriebe_DQ_Hybrid_MQB,Getriebe_DQ_MQB
 SG_ MO_Torque_Inertia_02 : 48|5@1+ (0.01,0) [0|0.31] "Unit_KiloGramMeterSquar" Gateway_MQB,Getriebe_DQ_Hybrid_MQB,Getriebe_DQ_MQB
 SG_ MO_HeatingPumpActuation : 53|4@1+ (10,0) [0|100] "Unit_PerCent" Gateway_MQB
 SG_ MO_VoltageReq : 57|1@1+ (1,0) [0|1] "" Gateway_MQB
 SG_ MO_RunOnTime_HeatingPump : 58|6@1+ (15,0) [0|945] "Unit_Secon" Gateway_MQB

BO_ 1607 Engine_09: 8 Motor_Diesel_MQB
 SG_ MO_ITM_Coolant_Temp : 0|8@1+ (0.75,-48) [-45.75|143.25] "Unit_DegreCelsi" Gateway_MQB,Getriebe_DQ_Hybrid_MQB,Getriebe_DQ_MQB
 SG_ MO_E85_Sensor : 8|4@1+ (10,0) [0|100] "Unit_PerCent" Gateway_MQB
 SG_ SCR_Disp_Motorstarts : 12|4@1+ (1,0) [0|8] "" Gateway_MQB
 SG_ SCR_Range : 16|15@1+ (1,0) [0|32766] "" Gateway_MQB
 SG_ SCR_WarningLevel_1 : 32|1@1+ (1,0) [0|1] "" Gateway_MQB
 SG_ SCR_WarningLevel_2 : 33|1@1+ (1,0) [0|1] "" Gateway_MQB
 SG_ SCR_Text : 34|3@1+ (1,0) [0|7] "" Gateway_MQB
 SG_ SCR_Acoustic : 37|2@1+ (1,0) [0|3] "" Gateway_MQB
 SG_ MO_Kraftstofffilter_Water : 40|1@1+ (1,0) [0|1] "" Gateway_MQB
 SG_ SCR_SystemError : 41|1@1+ (1,0) [0|1] "" Gateway_MQB
 SG_ SCR_Inducement_Strategy : 42|2@1+ (1,0) [0|3] "" Gateway_MQB
 SG_ MO_CO2_Factor : 44|12@1+ (1,0) [1|4094] "Unit_GramPerLiter" Gateway_MQB

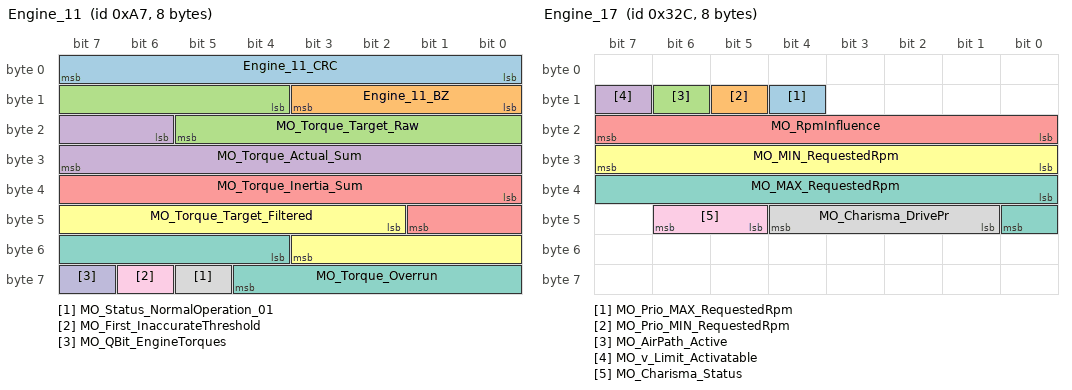
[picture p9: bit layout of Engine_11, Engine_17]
BO_ 167 Engine_11: 8 Motor_Diesel_MQB
 SG_ Engine_11_CRC : 0|8@1+ (1,0) [0|255] "" Gateway_MQB,Getriebe_DQ_Hybrid_MQB,Getriebe_DQ_MQB
 SG_ Engine_11_BZ : 8|4@1+ (1,0) [0|15] "" Gateway_MQB,Getriebe_DQ_Hybrid_MQB,Getriebe_DQ_MQB
 SG_ MO_Torque_Target_Raw : 12|10@1+ (1,-509) [-509|509] "Unit_NewtoMeter" Gateway_MQB,Getriebe_DQ_Hybrid_MQB,Getriebe_DQ_MQB
 SG_ MO_Torque_Actual_Sum : 22|10@1+ (1,-509) [-509|509] "Unit_NewtoMeter" Gateway_MQB,Getriebe_DQ_Hybrid_MQB,Getriebe_DQ_MQB,SAK_MQB
 SG_ MO_Torque_Inertia_Sum : 32|10@1+ (1,-509) [-509|509] "Unit_NewtoMeter" Gateway_MQB,Getriebe_DQ_Hybrid_MQB,Getriebe_DQ_MQB
 SG_ MO_Torque_Target_Filtered : 42|10@1+ (1,-509) [-509|509] "Unit_NewtoMeter" Gateway_MQB,Getriebe_DQ_Hybrid_MQB,Getriebe_DQ_MQB
 SG_ MO_Torque_Overrun : 52|9@1+ (1,-509) [-509|0] "Unit_NewtoMeter" Gateway_MQB,Getriebe_DQ_Hybrid_MQB,Getriebe_DQ_MQB
 SG_ MO_Status_NormalOperation_01 : 61|1@1+ (1,0) [0|1] "" Gateway_MQB,Getriebe_DQ_Hybrid_MQB,Getriebe_DQ_MQB
 SG_ MO_First_InaccurateThreshold : 62|1@1+ (1,0) [0|1] "" Gateway_MQB
 SG_ MO_QBit_EngineTorques : 63|1@1+ (1,0) [0|1] "" Gateway_MQB,Getriebe_DQ_Hybrid_MQB,Getriebe_DQ_MQB

BO_ 168 Engine_12: 8 Motor_Diesel_MQB
 SG_ Engine_12_CRC : 0|8@1+ (1,0) [0|255] "" Gateway_MQB,Getriebe_DQ_Hybrid_MQB,Getriebe_DQ_MQB,LEH_MQB
 SG_ Engine_12_BZ : 8|4@1+ (1,0) [0|15] "" BMS_MQB,Gateway_MQB,Getriebe_DQ_Hybrid_MQB,Getriebe_DQ_MQB,LEH_MQB
 SG_ MO_Torque_Neg_Available : 12|9@1+ (1,-509) [-509|0] "Unit_NewtoMeter" Gateway_MQB
 SG_ MO_Torque_Limit_Status : 21|9@1+ (1,0) [0|509] "Unit_NewtoMeter" Gateway_MQB,Getriebe_DQ_Hybrid_MQB,Getriebe_DQ_MQB
 SG_ MO_Torque_Limit_Dyn : 30|10@1+ (1,-509) [-509|509] "Unit_NewtoMeter" Gateway_MQB
 SG_ MO_TorqueIntegral_02 : 40|7@1+ (1,0) [0|100] "Unit_PerCent" Gateway_MQB,Getriebe_DQ_Hybrid_MQB,Getriebe_DQ_MQB
 SG_ MO_QBit_Rpm_01 : 47|1@1+ (1,0) [0|1] "" BMS_MQB,Gateway_MQB,Getriebe_DQ_Hybrid_MQB,Getriebe_DQ_MQB,LEH_MQB
 SG_ MO_Rpm_01 : 48|16@1+ (0.25,0) [0|16383] "Unit_MinutInver" BMS_MQB,Gateway_MQB,Getriebe_DQ_Hybrid_MQB,Getriebe_DQ_MQB,LEH_MQB,SAK_MQB

BO_ 958 Engine_14: 8 Motor_Diesel_MQB
 SG_ MO_StartStop_Status : 12|2@1+ (1,0) [0|3] "" Gateway_MQB,Getriebe_DQ_Hybrid_MQB,Getriebe_DQ_MQB
 SG_ MO_StartStop_Restart : 14|1@1+ (1,0) [0|1] "" Gateway_MQB,Getriebe_DQ_Hybrid_MQB,Getriebe_DQ_MQB
 SG_ MO_StartStop_EngineStop : 15|1@1+ (1,0) [0|1] "" Gateway_MQB,Getriebe_DQ_Hybrid_MQB,Getriebe_DQ_MQB
 SG_ MO_Enable_Recup : 16|2@1+ (1,0) [0|3] "" Gateway_MQB
 SG_ MO_Term_75 : 18|1@1+ (1,0) [0|1] "" Gateway_MQB
 SG_ MO_Term_50 : 19|1@1+ (1,0) [0|1] "" Gateway_MQB,LEH_MQB
 SG_ MO_GearPosition : 20|4@1+ (1,0) [0|15] "" Gateway_MQB
 SG_ MO_StartStop_DriverDemand : 24|2@1+ (1,0) [0|3] "" Gateway_MQB,Getriebe_DQ_Hybrid_MQB,Getriebe_DQ_MQB
 SG_ MO_HYB_ReadyToDrive : 26|1@1+ (1,0) [0|1] "" BMS_MQB,Gateway_MQB
 SG_ MO_Ext_E_Journey_Active : 27|1@1+ (1,0) [0|1] "" Gateway_MQB
 SG_ MO_Driver_Brakes : 28|1@1+ (1,0) [0|1] "" Gateway_MQB,Getriebe_DQ_Hybrid_MQB,Getriebe_DQ_MQB
 SG_ MO_QBit_Driver_Brakes : 29|1@1+ (1,0) [0|1] "" Gateway_MQB,Getriebe_DQ_Hybrid_MQB,Getriebe_DQ_MQB
 SG_ MO_BLS : 30|1@1+ (1,0) [0|1] "" Gateway_MQB,Getriebe_DQ_Hybrid_MQB,Getriebe_DQ_MQB
 SG_ MO_Consistency_BrakePedal : 31|1@1+ (1,0) [0|1] "" Gateway_MQB
 SG_ MO_Timeout_ESP : 32|1@1+ (1,0) [0|1] "" Gateway_MQB
 SG_ MO_Climate_Interv : 33|2@1+ (1,0) [0|3] "" Gateway_MQB
 SG_ MO_Aussp_Crank : 35|1@1+ (1,0) [0|1] "" Gateway_MQB
 SG_ MO_Enable_Crank : 36|1@1+ (1,0) [0|1] "" Gateway_MQB
 SG_ MO_Clutch_Switch : 37|1@1+ (1,0) [0|1] "" Gateway_MQB
 SG_ MO_Interlock : 38|1@1+ (1,0) [0|1] "" Gateway_MQB
 SG_ MO_Engine_Running : 39|1@1+ (1,0) [0|1] "" Gateway_MQB,Getriebe_DQ_Hybrid_MQB,Getriebe_DQ_MQB
 SG_ MO_Kickdown : 40|1@1+ (1,0) [0|1] "" Gateway_MQB,Getriebe_DQ_Hybrid_MQB,Getriebe_DQ_MQB
 SG_ MO_Status_CylDeact_01 : 41|1@1+ (1,0) [0|1] "" Gateway_MQB
 SG_ MO_ETermCommLeiRed : 42|2@1+ (1,0) [0|3] "" Gateway_MQB
 SG_ MO_Handshake_STH : 44|1@1+ (1,0) [0|1] "" Gateway_MQB
 SG_ MO_BKV_VacuumWarning : 45|1@1+ (1,0) [0|1] "" Gateway_MQB
 SG_ MO_Enable_Coasting : 46|1@1+ (1,0) [0|1] "" Gateway_MQB,Getriebe_DQ_Hybrid_MQB,Getriebe_DQ_MQB
 SG_ MO_PTC_Status : 47|3@1+ (1,0) [0|7] "" Gateway_MQB
 SG_ MO_QBit_GearPosition : 50|1@1+ (1,0) [0|1] "" Gateway_MQB
 SG_ MO_SignalSource_GearPosition : 51|1@1+ (1,0) [0|1] "" Gateway_MQB
 SG_ MO_Remotestart_Operation : 52|1@1+ (1,0) [0|1] "" Gateway_MQB

BO_ 1631 Engine_16: 8 Motor_Diesel_MQB
 SG_ TSK_QBit_Gradient : 12|1@1+ (1,0) [0|1] "" Gateway_MQB,Getriebe_DQ_Hybrid_MQB,Getriebe_DQ_MQB
 SG_ TSK_QBit_VehicleMass : 13|1@1+ (1,0) [0|1] "" Gateway_MQB,Getriebe_DQ_Hybrid_MQB,Getriebe_DQ_MQB
 SG_ MO_VoltageReq_02 : 14|2@1+ (1,0) [0|3] "" Gateway_MQB
 SG_ MO_DPF_reg : 16|1@1+ (1,0) [0|1] "" Gateway_MQB,Getriebe_DQ_Hybrid_MQB,Getriebe_DQ_MQB
 SG_ MO_HeaterCurrent_EKAT : 17|7@1+ (1,0) [0|126] "Unit_Amper" Gateway_MQB
 SG_ MO_HeaterCurrent_SCR : 24|6@1+ (1,0) [0|62] "Unit_Amper" Gateway_MQB
 SG_ TSK_VehicleMass_02 : 48|8@1+ (32,0) [0|8128] "Unit_KiloGram" Gateway_MQB,Getriebe_DQ_Hybrid_MQB,Getriebe_DQ_MQB
 SG_ TSK_Gradient : 56|8@1+ (0.8,-101.6) [-101.6|101.6] "Unit_PerCent" Gateway_MQB,Getriebe_DQ_Hybrid_MQB,Getriebe_DQ_MQB

BO_ 812 Engine_17: 8 Motor_Diesel_MQB
 SG_ MO_Prio_MAX_RequestedRpm : 12|1@1+ (1,0) [0|1] "" Getriebe_DQ_Hybrid_MQB,Getriebe_DQ_MQB
 SG_ MO_Prio_MIN_RequestedRpm : 13|1@1+ (1,0) [0|1] "" Getriebe_DQ_Hybrid_MQB,Getriebe_DQ_MQB
 SG_ MO_AirPath_Active : 14|1@1+ (1,0) [0|1] "" Vector__XXX
 SG_ MO_v_Limit_Activatable : 15|1@1+ (1,0) [0|1] "" Vector__XXX
 SG_ MO_RpmInfluence : 16|8@1+ (0.39,0) [0|99.45] "Unit_PerCent" Getriebe_DQ_Hybrid_MQB,Getriebe_DQ_MQB
 SG_ MO_MIN_RequestedRpm : 24|8@1+ (25,0) [0|6350] "Unit_MinutInver" Getriebe_DQ_Hybrid_MQB,Getriebe_DQ_MQB
 SG_ MO_MAX_RequestedRpm : 32|9@1+ (25,0) [0|12750] "Unit_MinutInver" Getriebe_DQ_Hybrid_MQB,Getriebe_DQ_MQB
 SG_ MO_Charisma_DrivePr : 41|4@1+ (1,0) [0|15] "" Gateway_MQB
 SG_ MO_Charisma_Status : 45|2@1+ (1,0) [0|3] "" Gateway_MQB

BO_ 1648 Engine_18: 8 Motor_Diesel_MQB
 SG_ MO_Hybrid_StartStop_LED : 43|2@1+ (1,0) [0|3] "" Gateway_MQB
 SG_ MO_Eis_Offroad_LED : 45|2@1+ (1,0) [0|3] "" Gateway_MQB
 SG_ MO_Count_Abgesch_Cyl : 47|3@1+ (1,0) [0|7] "" Gateway_MQB
 SG_ MO_CylDeact_Texte : 50|2@1+ (1,0) [0|3] "" Gateway_MQB
 SG_ MO_E85_BS_Texte : 52|3@1+ (1,0) [0|7] "" Gateway_MQB
 SG_ MO_Rpm_Warning : 55|1@1+ (1,0) [0|1] "" Gateway_MQB
 SG_ MO_Upper_RpmLimit : 56|8@1+ (50,0) [50|12750] "Unit_MinutInver" Gateway_MQB,Getriebe_DQ_Hybrid_MQB,Getriebe_DQ_MQB

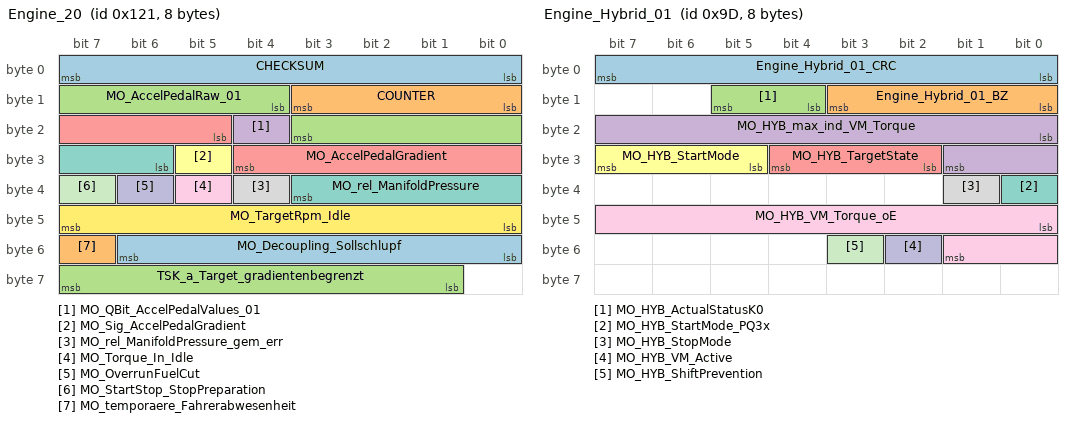
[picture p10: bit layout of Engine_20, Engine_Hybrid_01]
BO_ 289 Engine_20: 8 Motor_Diesel_MQB
 SG_ CHECKSUM : 0|8@1+ (1,0) [0|255] "" XXX
 SG_ COUNTER : 8|4@1+ (1,0) [0|255] "" XXX
 SG_ MO_AccelPedalRaw_01 : 12|8@1+ (0.4,0) [0.0|101.6] "Unit_PerCent"  XXX
 SG_ MO_QBit_AccelPedalValues_01 : 20|1@1+ (1.0,0.0) [0.0|1] ""  XXX
 SG_ MO_AccelPedalGradient : 21|8@1+ (25,0) [0|6350] "Unit_PerCentPerSecon"  XXX
 SG_ MO_Sig_AccelPedalGradient : 29|1@1+ (1.0,0.0) [0.0|1] ""  XXX
 SG_ MO_rel_ManifoldPressure : 30|6@1+ (18,0) [0|1116] "Unit_MilliBar"  XXX
 SG_ MO_rel_ManifoldPressure_gem_err : 36|1@1+ (1.0,0.0) [0.0|1] ""  XXX
 SG_ MO_Torque_In_Idle : 37|1@1+ (1.0,0.0) [0.0|1] ""  XXX
 SG_ MO_OverrunFuelCut : 38|1@1+ (1.0,0.0) [0.0|1] ""  XXX
 SG_ MO_StartStop_StopPreparation : 39|1@1+ (1.0,0.0) [0.0|1] ""  XXX
 SG_ MO_TargetRpm_Idle : 40|8@1+ (10,0) [0|2540] "Unit_MinutInver"  XXX
 SG_ MO_Decoupling_Sollschlupf : 48|7@1+ (20,0) [0|2480] "Unit_MinutInver"  XXX
 SG_ MO_temporaere_Fahrerabwesenheit : 55|1@1+ (1.0,0.0) [0.0|1] ""  XXX
 SG_ TSK_a_Target_gradientenbegrenzt : 57|7@1+ (0.1,-7.2) [-7.2|5.4] "Unit_MeterPerSeconSquar"  XXX

BO_ 967 Engine_26: 8 Motor_Diesel_MQB
 SG_ MO_HYB_Status_HV_Charge : 8|3@1+ (1,0) [0|7] "" Gateway_MQB
 SG_ WIV_Display_Active : 12|1@1+ (1,0) [0|1] "" Gateway_MQB
 SG_ WIV_Oelmin_Warn : 13|1@1+ (1,0) [0|1] "" Gateway_MQB
 SG_ WIV_SensorError : 14|1@1+ (1,0) [0|1] "" Gateway_MQB
 SG_ WIV_Tilt : 15|1@1+ (1,0) [0|1] "" Gateway_MQB
 SG_ WIV_OilLevel : 16|4@1+ (12.5,0) [0|100] "Unit_PerCent" Gateway_MQB
 SG_ MO_State_HWP : 20|2@1+ (1,0) [0|3] "" Gateway_MQB
 SG_ WIV_OilSystem_Active : 24|1@1+ (1,0) [0|1] "" Gateway_MQB
 SG_ WIV_Not_AtOperatingTemp : 25|1@1+ (1,0) [0|1] "" Gateway_MQB
 SG_ WIV_Overfill_Warn : 26|1@1+ (1,0) [0|1] "" Gateway_MQB
 SG_ WIV_Running_Engine : 27|1@1+ (1,0) [0|1] "" Gateway_MQB
 SG_ MO_HYB_Text_1 : 28|1@1+ (1,0) [0|1] "" Gateway_MQB
 SG_ MO_HYB_Text_2 : 29|1@1+ (1,0) [0|1] "" Gateway_MQB
 SG_ MO_HYB_Text_3 : 30|1@1+ (1,0) [0|1] "" Gateway_MQB
 SG_ MO_HYB_Text_4 : 31|1@1+ (1,0) [0|1] "" Gateway_MQB
 SG_ MO_Text_EngineStart : 32|4@1+ (1,0) [0|15] "" Gateway_MQB
 SG_ MO_HYB_Text_5 : 36|1@1+ (1,0) [0|1] "" Gateway_MQB
 SG_ MO_HYB_Text_6 : 37|1@1+ (1,0) [0|1] "" Gateway_MQB
 SG_ MO_HYB_Text_7 : 38|1@1+ (1,0) [0|1] "" Gateway_MQB
 SG_ MO_Text_ParticleFilter_Reg : 41|1@1+ (1,0) [0|1] "" Gateway_MQB
 SG_ WIV_OilQuantity : 43|5@1+ (125,0) [0|3875] "Unit_MilliLiter" Gateway_MQB
 SG_ MO_SystemLamp : 48|1@1+ (1,0) [0|1] "" Gateway_MQB
 SG_ MO_OBD2_Lamp : 49|1@1+ (1,0) [0|1] "" Gateway_MQB
 SG_ MO_HotWarningLamp : 50|1@1+ (1,0) [0|1] "" Gateway_MQB
 SG_ MO_Particle_Lamp : 51|1@1+ (1,0) [0|1] "" Gateway_MQB
 SG_ MO_WinterProgram : 52|1@1+ (1,0) [0|1] "" Gateway_MQB,Getriebe_DQ_Hybrid_MQB,Getriebe_DQ_MQB
 SG_ WIV_OilLevel_Not_Present : 53|1@1+ (1,0) [0|1] "" Gateway_MQB
 SG_ WIV_RefillDisplay_On : 54|1@1+ (1,0) [0|1] "" Gateway_MQB
 SG_ WIV_Overfill_Deactivated : 55|1@1+ (1,0) [0|1] "" Gateway_MQB
 SG_ WIV_Underfill_Warn : 56|1@1+ (1,0) [0|1] "" Gateway_MQB
 SG_ MO_FuelCap_Lamp : 57|1@1+ (1,0) [0|1] "" Gateway_MQB
 SG_ MO_Text_FuelCapWarn : 58|1@1+ (1,0) [0|1] "" Gateway_MQB
 SG_ WIV_OilPressure_Warn_Engine : 60|1@1+ (1,0) [0|1] "" Gateway_MQB

BO_ 1601 Engine_Code_01: 8 Motor_Diesel_MQB
 SG_ Engine_Code_01_CRC : 0|8@1+ (1,0) [0|255] "" Gateway_MQB
 SG_ Engine_Code_01_BZ : 8|4@1+ (1,0) [0|15] "" Gateway_MQB
 SG_ MO_Factor_Torques_02 : 12|2@1+ (1,0) [0|3] "" Gateway_MQB,Getriebe_DQ_Hybrid_MQB,Getriebe_DQ_MQB
 SG_ MO_HybridVehicle : 14|2@1+ (1,0) [0|3] "" Gateway_MQB
 SG_ MO_Code : 16|8@1+ (1,0) [0|255] "" Gateway_MQB,SAK_MQB
 SG_ MO_Gearbox_Code : 24|6@1+ (1,0) [0|63] "" Gateway_MQB
 SG_ MO_StartStop_Coded : 30|1@1+ (1,0) [0|1] "" Gateway_MQB
 SG_ MO_Count_Cyl : 32|4@1+ (1,0) [0|15] "" Gateway_MQB
 SG_ MO_FuelType : 36|4@1+ (1,0) [0|15] "" Gateway_MQB,Getriebe_DQ_Hybrid_MQB,Getriebe_DQ_MQB
 SG_ MO_Displacement : 40|7@1+ (0.1,0) [0|12.7] "Unit_Liter" Gateway_MQB
 SG_ MO_IntakeSystem : 47|1@1+ (1,0) [0|1] "" Gateway_MQB
 SG_ MO_Power : 48|9@1+ (1,0) [0|511] "Unit_KiloWatt" Gateway_MQB
 SG_ MO_ExhaustType_EOBD : 57|1@1+ (1,0) [0|1] "" BMS_MQB,Gateway_MQB,LEH_MQB
 SG_ MO_ExhaustType_OBD : 58|1@1+ (1,0) [0|1] "" BMS_MQB,Gateway_MQB,LEH_MQB
 SG_ MO_DPF_Fitted : 59|1@1+ (1,0) [0|1] "" Gateway_MQB
 SG_ TSK_Coding : 60|3@1+ (1,0) [0|7] "" Gateway_MQB,Getriebe_DQ_Hybrid_MQB,Getriebe_DQ_MQB
 SG_ MO_InjectionType : 63|1@1+ (1,0) [0|1] "" Gateway_MQB

BO_ 157 Engine_Hybrid_01: 8 Motor_Hybrid_MQB
 SG_ Engine_Hybrid_01_CRC : 0|8@1+ (1,0) [0|255] "" Getriebe_DQ_Hybrid_MQB
 SG_ Engine_Hybrid_01_BZ : 8|4@1+ (1,0) [0|15] "" BMS_MQB,Getriebe_DQ_Hybrid_MQB
 SG_ MO_HYB_ActualStatusK0 : 12|2@1+ (1,0) [0|3] "" Getriebe_DQ_Hybrid_MQB
 SG_ MO_HYB_max_ind_VM_Torque : 16|10@1+ (1,0) [0|1021] "Unit_NewtoMeter" Getriebe_DQ_Hybrid_MQB
 SG_ MO_HYB_TargetState : 26|3@1+ (1,0) [0|7] "" BMS_MQB,Getriebe_DQ_Hybrid_MQB
 SG_ MO_HYB_StartMode : 29|3@1+ (1,0) [0|7] "" Vector__XXX
 SG_ MO_HYB_StartMode_PQ3x : 32|1@1+ (1,0) [0|1] "" Getriebe_DQ_Hybrid_MQB
 SG_ MO_HYB_StopMode : 33|1@1+ (1,0) [0|1] "" Getriebe_DQ_Hybrid_MQB
 SG_ MO_HYB_VM_Torque_oE : 40|10@1+ (1,-100) [-100|922] "Unit_NewtoMeter" Getriebe_DQ_Hybrid_MQB
 SG_ MO_HYB_VM_Active : 50|1@1+ (1,0) [0|1] "" Getriebe_DQ_Hybrid_MQB
 SG_ MO_HYB_ShiftPrevention : 51|1@1+ (1,0) [0|1] "" Getriebe_DQ_Hybrid_MQB

BO_ 811 Engine_Hybrid_02: 8 Motor_Hybrid_MQB
 SG_ MO_HYB_E_Factor : 12|4@1+ (1,0) [0|15] "" Getriebe_DQ_Hybrid_MQB
 SG_ MO_HYB_Rpm_VM : 16|16@1+ (0.25,0) [0|16256] "Unit_MinutInver" Getriebe_DQ_Hybrid_MQB
 SG_ MO_HYB_LowSpeedMode : 32|1@1+ (1,0) [0|1] "" Getriebe_DQ_Hybrid_MQB

BO_ 2600468501 NMH_Airbag_01: 8 Airbag_MQB
 SG_ NM_Airbag_01_SNI : 0|8@1+ (1,0) [0|255] "" Vector__XXX
 SG_ NM_Airbag_01_NM_State : 16|6@1+ (1,0) [0|63] "" BMS_MQB,Getriebe_DQ_Hybrid_MQB,Getriebe_DQ_MQB,LEH_MQB,Motor_Diesel_MQB,Motor_Hybrid_MQB,Motor_Otto_MQB
 SG_ NM_Airbag_01_Car_Wakeup : 22|1@1+ (1,0) [0|1] "" Gateway_MQB
 SG_ NM_Airbag_01_Wakeup : 24|8@1+ (1,0) [0|255] "" Vector__XXX
 SG_ NM_Airbag_01_NM_Active_TERM15 : 32|1@1+ (1,0) [0|1] "" Vector__XXX
 SG_ NM_Airbag_01_NM_Active_Diagnostics : 33|1@1+ (1,0) [0|1] "" Vector__XXX
 SG_ NM_Airbag_01_NM_Active_Tmin : 34|1@1+ (1,0) [0|1] "" Vector__XXX
 SG_ NM_Airbag_01_UDS_CC : 63|1@1+ (1,0) [0|1] "" Vector__XXX

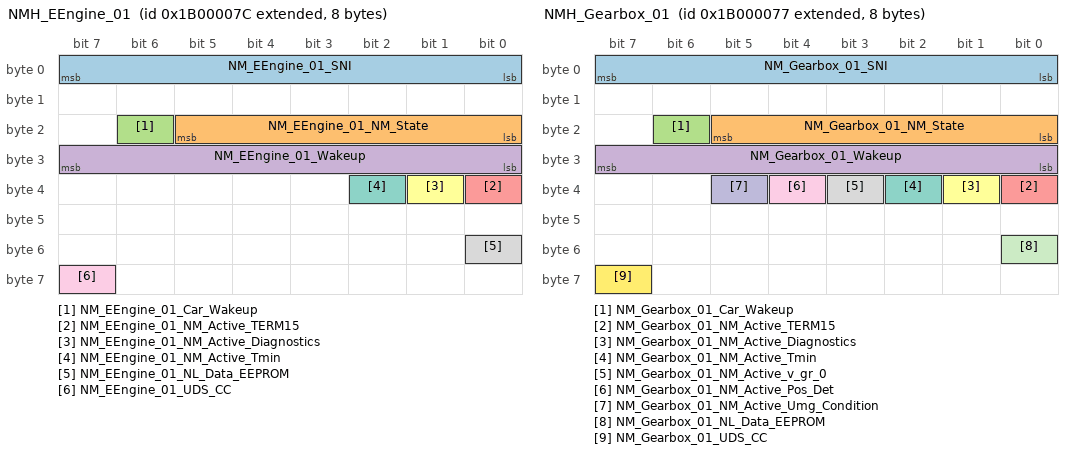
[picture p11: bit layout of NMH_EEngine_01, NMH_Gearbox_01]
BO_ 2600468604 NMH_EEngine_01: 8 LEH_MQB
 SG_ NM_EEngine_01_SNI : 0|8@1+ (1,0) [0|255] "" Vector__XXX
 SG_ NM_EEngine_01_NM_State : 16|6@1+ (1,0) [0|63] "" BMS_MQB,Getriebe_DQ_Hybrid_MQB,Getriebe_DQ_MQB,LEH_MQB,Motor_Diesel_MQB,Motor_Hybrid_MQB,Motor_Otto_MQB
 SG_ NM_EEngine_01_Car_Wakeup : 22|1@1+ (1,0) [0|1] "" Gateway_MQB
 SG_ NM_EEngine_01_Wakeup : 24|8@1+ (1,0) [0|255] "" Vector__XXX
 SG_ NM_EEngine_01_NM_Active_TERM15 : 32|1@1+ (1,0) [0|1] "" Vector__XXX
 SG_ NM_EEngine_01_NM_Active_Diagnostics : 33|1@1+ (1,0) [0|1] "" Vector__XXX
 SG_ NM_EEngine_01_NM_Active_Tmin : 34|1@1+ (1,0) [0|1] "" Vector__XXX
 SG_ NM_EEngine_01_NL_Data_EEPROM : 48|1@1+ (1,0) [0|1] "" Vector__XXX
 SG_ NM_EEngine_01_UDS_CC : 63|1@1+ (1,0) [0|1] "" Vector__XXX

BO_ 2600468496 NMH_Gateway: 8 Gateway_MQB
 SG_ NM_Gateway_SNI : 0|8@1+ (1,0) [0|255] "" Vector__XXX
 SG_ NM_Gateway_NM_State : 16|6@1+ (1,0) [0|63] "" BMS_MQB,Getriebe_DQ_Hybrid_MQB,Getriebe_DQ_MQB,LEH_MQB,Motor_Diesel_MQB,Motor_Hybrid_MQB,Motor_Otto_MQB
 SG_ NM_Gateway_Car_Wakeup : 22|1@1+ (1,0) [0|1] "" Vector__XXX
 SG_ NM_Gateway_Wakeup : 24|8@1+ (1,0) [0|255] "" Vector__XXX
 SG_ NM_Gateway_NM_Active_TERM15 : 32|1@1+ (1,0) [0|1] "" Vector__XXX
 SG_ NM_Gateway_NM_Active_Diagnostics : 33|1@1+ (1,0) [0|1] "" Vector__XXX
 SG_ NM_Gateway_NM_Active_Tmin : 34|1@1+ (1,0) [0|1] "" Vector__XXX
 SG_ NM_Gateway_ACAN_Activity : 35|1@1+ (1,0) [0|1] "" Vector__XXX
 SG_ NM_Gateway_FCAN_Activity : 36|1@1+ (1,0) [0|1] "" Vector__XXX
 SG_ NM_Gateway_KCAN_Activity : 37|1@1+ (1,0) [0|1] "" Vector__XXX
 SG_ NM_Gateway_ICAN_Activity : 38|1@1+ (1,0) [0|1] "" Vector__XXX
 SG_ NM_Gateway_DiagCAN_Activity : 39|1@1+ (1,0) [0|1] "" Vector__XXX
 SG_ NM_Gateway_ECAN_Activity : 40|1@1+ (1,0) [0|1] "" Vector__XXX
 SG_ NM_Gateway_Energy_LIN_Aktivi000 : 41|1@1+ (1,0) [0|1] "" Vector__XXX
 SG_ NM_Gateway_Bedien_LIN_Activity : 42|1@1+ (1,0) [0|1] "" Vector__XXX
 SG_ NM_Gateway_EM_Activity : 43|1@1+ (1,0) [0|1] "" Vector__XXX
 SG_ NM_Gateway_NL_EM : 48|1@1+ (1,0) [0|1] "" Vector__XXX
 SG_ NM_Gateway_NL_Shutdown : 49|1@1+ (1,0) [0|1] "" Vector__XXX
 SG_ NM_Gateway_NL_Volt_Measurement : 50|1@1+ (1,0) [0|1] "" Vector__XXX
 SG_ NM_Gateway_NL_Wakeup_Monitor : 51|1@1+ (1,0) [0|1] "" Vector__XXX
 SG_ NM_Gateway_UDS_CC : 63|1@1+ (1,0) [0|1] "" Vector__XXX

BO_ 2600468599 NMH_Gearbox_01: 8 Getriebe_DQ_Hybrid_MQB
 SG_ NM_Gearbox_01_SNI : 0|8@1+ (1,0) [0|255] "" Vector__XXX
 SG_ NM_Gearbox_01_NM_State : 16|6@1+ (1,0) [0|63] "" BMS_MQB,Getriebe_DQ_Hybrid_MQB,Getriebe_DQ_MQB,LEH_MQB,Motor_Diesel_MQB,Motor_Hybrid_MQB,Motor_Otto_MQB
 SG_ NM_Gearbox_01_Car_Wakeup : 22|1@1+ (1,0) [0|1] "" Gateway_MQB
 SG_ NM_Gearbox_01_Wakeup : 24|8@1+ (1,0) [0|255] "" Vector__XXX
 SG_ NM_Gearbox_01_NM_Active_TERM15 : 32|1@1+ (1,0) [0|1] "" Vector__XXX
 SG_ NM_Gearbox_01_NM_Active_Diagnostics : 33|1@1+ (1,0) [0|1] "" Vector__XXX
 SG_ NM_Gearbox_01_NM_Active_Tmin : 34|1@1+ (1,0) [0|1] "" Vector__XXX
 SG_ NM_Gearbox_01_NM_Active_v_gr_0 : 35|1@1+ (1,0) [0|1] "" Vector__XXX
 SG_ NM_Gearbox_01_NM_Active_Pos_Det : 36|1@1+ (1,0) [0|1] "" Vector__XXX
 SG_ NM_Gearbox_01_NM_Active_Umg_Condition : 37|1@1+ (1,0) [0|1] "" Vector__XXX
 SG_ NM_Gearbox_01_NL_Data_EEPROM : 48|1@1+ (1,0) [0|1] "" Vector__XXX
 SG_ NM_Gearbox_01_UDS_CC : 63|1@1+ (1,0) [0|1] "" Vector__XXX

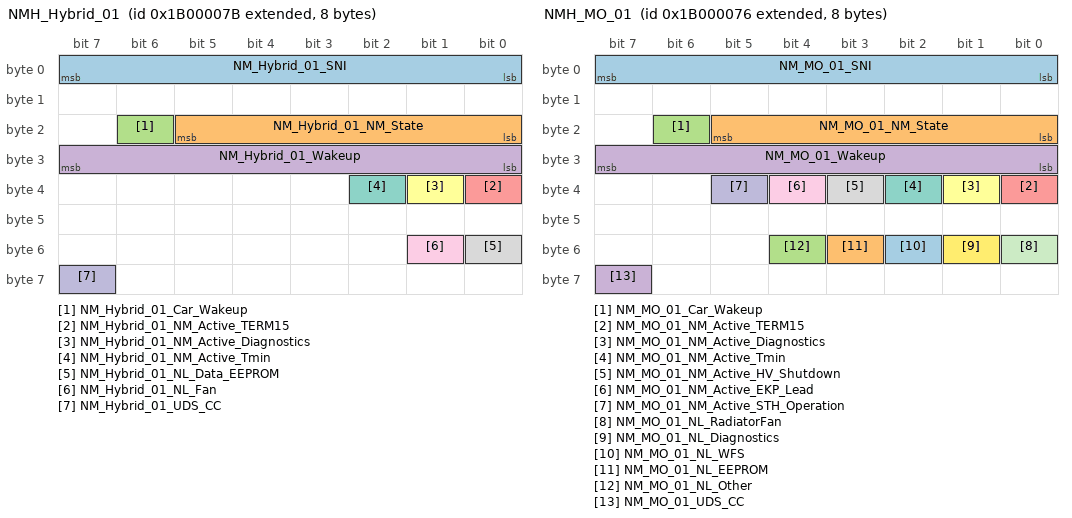
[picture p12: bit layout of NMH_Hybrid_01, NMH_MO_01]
BO_ 2600468603 NMH_Hybrid_01: 8 BMS_MQB
 SG_ NM_Hybrid_01_SNI : 0|8@1+ (1,0) [0|255] "" Vector__XXX
 SG_ NM_Hybrid_01_NM_State : 16|6@1+ (1,0) [0|63] "" BMS_MQB,Getriebe_DQ_Hybrid_MQB,Getriebe_DQ_MQB,LEH_MQB,Motor_Diesel_MQB,Motor_Hybrid_MQB,Motor_Otto_MQB
 SG_ NM_Hybrid_01_Car_Wakeup : 22|1@1+ (1,0) [0|1] "" Gateway_MQB
 SG_ NM_Hybrid_01_Wakeup : 24|8@1+ (1,0) [0|255] "" Vector__XXX
 SG_ NM_Hybrid_01_NM_Active_TERM15 : 32|1@1+ (1,0) [0|1] "" Vector__XXX
 SG_ NM_Hybrid_01_NM_Active_Diagnostics : 33|1@1+ (1,0) [0|1] "" Vector__XXX
 SG_ NM_Hybrid_01_NM_Active_Tmin : 34|1@1+ (1,0) [0|1] "" Vector__XXX
 SG_ NM_Hybrid_01_NL_Data_EEPROM : 48|1@1+ (1,0) [0|1] "" Vector__XXX
 SG_ NM_Hybrid_01_NL_Fan : 49|1@1+ (1,0) [0|1] "" Vector__XXX
 SG_ NM_Hybrid_01_UDS_CC : 63|1@1+ (1,0) [0|1] "" Vector__XXX

BO_ 2600468598 NMH_MO_01: 8 Motor_Diesel_MQB
 SG_ NM_MO_01_SNI : 0|8@1+ (1,0) [0|255] "" Vector__XXX
 SG_ NM_MO_01_NM_State : 16|6@1+ (1,0) [0|63] "" BMS_MQB,Getriebe_DQ_Hybrid_MQB,Getriebe_DQ_MQB,LEH_MQB,Motor_Diesel_MQB,Motor_Hybrid_MQB,Motor_Otto_MQB
 SG_ NM_MO_01_Car_Wakeup : 22|1@1+ (1,0) [0|1] "" Gateway_MQB
 SG_ NM_MO_01_Wakeup : 24|8@1+ (1,0) [0|255] "" Vector__XXX
 SG_ NM_MO_01_NM_Active_TERM15 : 32|1@1+ (1,0) [0|1] "" Vector__XXX
 SG_ NM_MO_01_NM_Active_Diagnostics : 33|1@1+ (1,0) [0|1] "" Vector__XXX
 SG_ NM_MO_01_NM_Active_Tmin : 34|1@1+ (1,0) [0|1] "" Vector__XXX
 SG_ NM_MO_01_NM_Active_HV_Shutdown : 35|1@1+ (1,0) [0|1] "" Vector__XXX
 SG_ NM_MO_01_NM_Active_EKP_Lead : 36|1@1+ (1,0) [0|1] "" Vector__XXX
 SG_ NM_MO_01_NM_Active_STH_Operation : 37|1@1+ (1,0) [0|1] "" Vector__XXX
 SG_ NM_MO_01_NL_RadiatorFan : 48|1@1+ (1,0) [0|1] "" Vector__XXX
 SG_ NM_MO_01_NL_Diagnostics : 49|1@1+ (1,0) [0|1] "" Vector__XXX
 SG_ NM_MO_01_NL_WFS : 50|1@1+ (1,0) [0|1] "" Vector__XXX
 SG_ NM_MO_01_NL_EEPROM : 51|1@1+ (1,0) [0|1] "" Vector__XXX
 SG_ NM_MO_01_NL_Other : 52|1@1+ (1,0) [0|1] "" Vector__XXX
 SG_ NM_MO_01_UDS_CC : 63|1@1+ (1,0) [0|1] "" Vector__XXX

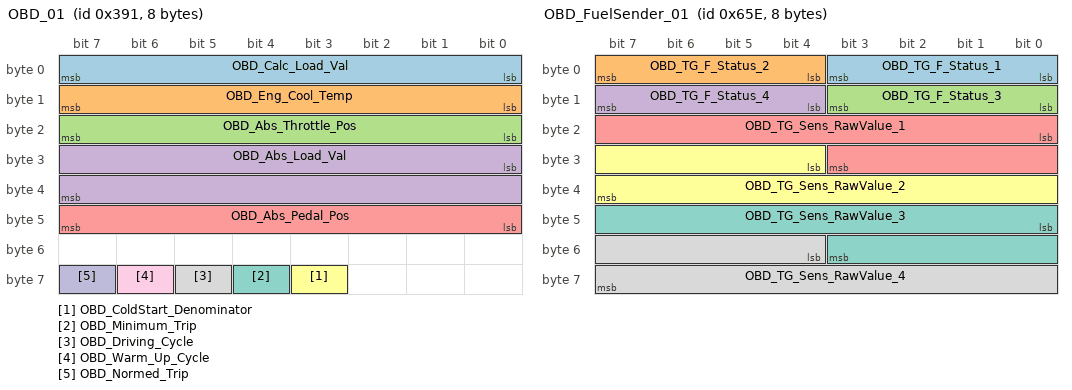
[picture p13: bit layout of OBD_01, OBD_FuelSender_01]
BO_ 913 OBD_01: 8 Motor_Diesel_MQB
 SG_ OBD_Calc_Load_Val : 0|8@1+ (0.39215686275,0) [0|100] "Unit_PerCent" BMS_MQB,Getriebe_DQ_Hybrid_MQB,Getriebe_DQ_MQB,LEH_MQB
 SG_ OBD_Eng_Cool_Temp : 8|8@1+ (1,-40) [-40|215] "Unit_DegreCelsi" BMS_MQB,Getriebe_DQ_Hybrid_MQB,Getriebe_DQ_MQB,LEH_MQB
 SG_ OBD_Abs_Throttle_Pos : 16|8@1+ (0.39215686275,0) [0|100] "Unit_PerCent" BMS_MQB,Getriebe_DQ_Hybrid_MQB,Getriebe_DQ_MQB,LEH_MQB
 SG_ OBD_Abs_Load_Val : 24|16@1+ (0.39215686275,0) [0|25700] "Unit_PerCent" BMS_MQB,Getriebe_DQ_Hybrid_MQB,Getriebe_DQ_MQB,LEH_MQB
 SG_ OBD_Abs_Pedal_Pos : 40|8@1+ (0.39215686275,0) [0|100] "Unit_PerCent" BMS_MQB,Getriebe_DQ_Hybrid_MQB,Getriebe_DQ_MQB,LEH_MQB
 SG_ OBD_ColdStart_Denominator : 59|1@1+ (1,0) [0|1] "" BMS_MQB,LEH_MQB
 SG_ OBD_Minimum_Trip : 60|1@1+ (1,0) [0|1] "" BMS_MQB,Getriebe_DQ_Hybrid_MQB,Getriebe_DQ_MQB,LEH_MQB
 SG_ OBD_Driving_Cycle : 61|1@1+ (1,0) [0|1] "" BMS_MQB,Getriebe_DQ_Hybrid_MQB,Getriebe_DQ_MQB,LEH_MQB
 SG_ OBD_Warm_Up_Cycle : 62|1@1+ (1,0) [0|1] "" BMS_MQB,Gateway_MQB,Getriebe_DQ_Hybrid_MQB,Getriebe_DQ_MQB,LEH_MQB
 SG_ OBD_Normed_Trip : 63|1@1+ (1,0) [0|1] "" BMS_MQB,Getriebe_DQ_Hybrid_MQB,Getriebe_DQ_MQB,LEH_MQB

BO_ 1630 OBD_FuelSender_01: 8 Gateway_MQB
 SG_ OBD_TG_F_Status_1 : 0|4@1+ (1,0) [0|15] "" Motor_Hybrid_MQB,Motor_Otto_MQB
 SG_ OBD_TG_F_Status_2 : 4|4@1+ (1,0) [0|15] "" Motor_Hybrid_MQB,Motor_Otto_MQB
 SG_ OBD_TG_F_Status_3 : 8|4@1+ (1,0) [0|15] "" Motor_Hybrid_MQB,Motor_Otto_MQB
 SG_ OBD_TG_F_Status_4 : 12|4@1+ (1,0) [0|15] "" Motor_Hybrid_MQB,Motor_Otto_MQB
 SG_ OBD_TG_Sens_RawValue_1 : 16|12@1+ (0.5,0) [0|2047.5] "Unit_Ohm" Motor_Hybrid_MQB,Motor_Otto_MQB
 SG_ OBD_TG_Sens_RawValue_2 : 28|12@1+ (0.5,0) [0|2047.5] "Unit_Ohm" Motor_Hybrid_MQB,Motor_Otto_MQB
 SG_ OBD_TG_Sens_RawValue_3 : 40|12@1+ (0.5,0) [0|2047.5] "Unit_Ohm" Motor_Hybrid_MQB,Motor_Otto_MQB
 SG_ OBD_TG_Sens_RawValue_4 : 52|12@1+ (0.5,0) [0|2047.5] "Unit_Ohm" Motor_Hybrid_MQB,Motor_Otto_MQB

BO_ 1437 Remotestart_FFB: 8 Gateway_MQB
 SG_ RSF_KeyCode_1 : 0|8@1+ (1,0) [0|255] "" Motor_Diesel_MQB,Motor_Otto_MQB
 SG_ RSF_KeyCode_2 : 8|8@1+ (1,0) [0|255] "" Motor_Diesel_MQB,Motor_Otto_MQB
 SG_ RSF_KeyCode_Maske : 16|8@1+ (1,0) [0|255] "" Motor_Diesel_MQB,Motor_Otto_MQB

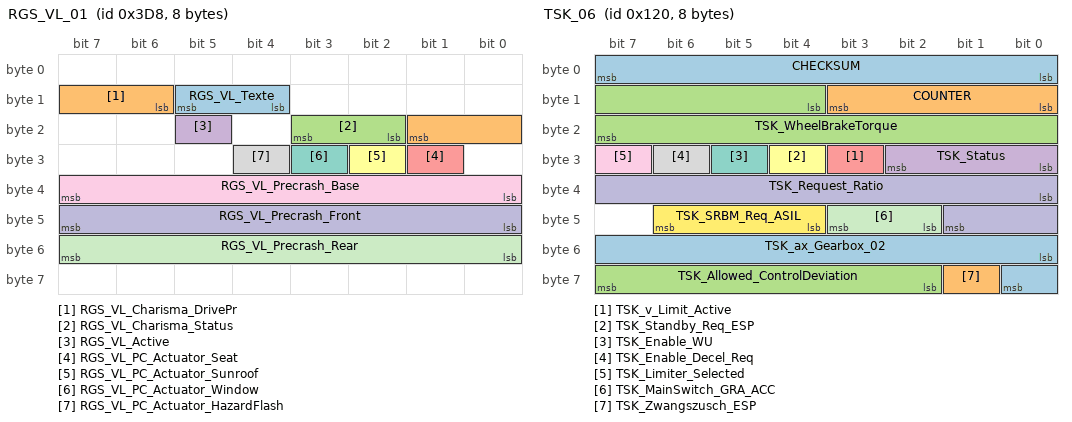
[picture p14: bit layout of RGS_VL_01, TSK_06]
BO_ 984 RGS_VL_01: 8 Airbag_MQB
 SG_ RGS_VL_Texte : 12|2@1+ (1,0) [0|3] "" Gateway_MQB
 SG_ RGS_VL_Charisma_DrivePr : 14|4@1+ (1,0) [0|15] "" Gateway_MQB
 SG_ RGS_VL_Charisma_Status : 18|2@1+ (1,0) [0|3] "" Gateway_MQB
 SG_ RGS_VL_Active : 21|1@1+ (1,0) [0|1] "" Gateway_MQB
 SG_ RGS_VL_PC_Actuator_Seat : 25|1@1+ (1,0) [0|1] "" Gateway_MQB
 SG_ RGS_VL_PC_Actuator_Sunroof : 26|1@1+ (1,0) [0|1] "" Gateway_MQB
 SG_ RGS_VL_PC_Actuator_Window : 27|1@1+ (1,0) [0|1] "" Gateway_MQB
 SG_ RGS_VL_PC_Actuator_HazardFlash : 28|1@1+ (1,0) [0|1] "" Gateway_MQB
 SG_ RGS_VL_Precrash_Base : 32|8@1+ (1,0) [0|255] "" Gateway_MQB
 SG_ RGS_VL_Precrash_Front : 40|8@1+ (1,0) [0|255] "" Gateway_MQB
 SG_ RGS_VL_Precrash_Rear : 48|8@1+ (1,0) [0|255] "" Gateway_MQB

BO_ 1528 SAK_01: 8 SAK_MQB
 SG_ SAK_Charisma_DrivePr : 16|4@1+ (1,0) [0|15] "" Gateway_MQB
 SG_ SAK_Charisma_Status : 20|2@1+ (1,0) [0|3] "" Gateway_MQB

BO_ 1313 STH_01: 8 Gateway_MQB
 SG_ STH_Radio_On : 0|1@1+ (1,0) [0|1] "" Vector__XXX
 SG_ STH_Radio_Off : 1|1@1+ (1,0) [0|1] "" Vector__XXX
 SG_ STH_AuxHeater : 2|1@1+ (1,0) [0|1] "" Vector__XXX
 SG_ STH_LED : 3|1@1+ (1,0) [0|1] "" Motor_Diesel_MQB,Motor_Hybrid_MQB,Motor_Otto_MQB
 SG_ STH_Pump_On : 4|1@1+ (1,0) [0|1] "" Vector__XXX
 SG_ STH_Blower : 5|1@1+ (1,0) [0|1] "" Vector__XXX
 SG_ STH_EKP_Anst : 6|1@1+ (1,0) [0|1] "" Motor_Diesel_MQB,Motor_Hybrid_MQB,Motor_Otto_MQB
 SG_ STH_Start_Follows : 7|1@1+ (1,0) [0|1] "" Vector__XXX
 SG_ STH_ValveOpeningTime : 8|6@1+ (1,0) [0|63] "Unit_Minut" Vector__XXX
 SG_ STH_Valve_Status : 14|1@1+ (1,0) [0|1] "" Vector__XXX
 SG_ STH_Waermeeintrag : 16|6@1+ (1,0) [0|63] "" Vector__XXX
 SG_ STH_KVS : 24|13@1+ (1,0) [0|8191] "Unit_MilliLiter" Vector__XXX
 SG_ STH_ErrorStatus : 37|3@1+ (1,0) [0|7] "" Vector__XXX
 SG_ STH_HeatPower : 40|8@1+ (1,0) [0|255] "" Vector__XXX
 SG_ STH_WaterTemp : 48|8@1+ (0.75,-40) [-40|142.25] "Unit_DegreCelsi" Vector__XXX
 SG_ STH_Motorvorwaermung : 59|1@1+ (1,0) [0|1] "" Motor_Diesel_MQB,Motor_Hybrid_MQB,Motor_Otto_MQB
 SG_ STH_Servicemode : 60|1@1+ (1,0) [0|1] "" Vector__XXX
 SG_ STH_Was_Active : 61|1@1+ (1,0) [0|1] "" Motor_Diesel_MQB,Motor_Hybrid_MQB,Motor_Otto_MQB
 SG_ STH_KVS_Overflow : 62|1@1+ (1,0) [0|1] "" Vector__XXX
 SG_ STH_KD_Error : 63|1@1+ (1,0) [0|1] "" Vector__XXX

BO_ 1172 Status_01: 8 Gateway_MQB
 SG_ Status_01_CRC : 0|8@1+ (1,0) [0|255] "" Motor_Diesel_MQB,Motor_Hybrid_MQB,Motor_Otto_MQB
 SG_ Status_01_BZ : 8|4@1+ (1,0) [0|15] "" Motor_Diesel_MQB,Motor_Hybrid_MQB,Motor_Otto_MQB
 SG_ Status_Car_not_under_theft : 12|1@1+ (1,0) [0|1] "" Vector__XXX
 SG_ Status_Car_under_theft : 13|1@1+ (1,0) [0|1] "" Vector__XXX
 SG_ Status_StarterLock : 15|1@1+ (1,0) [0|1] "" Vector__XXX
 SG_ Status_TypeCoding : 16|5@1+ (1,0) [0|31] "" Vector__XXX
 SG_ Status_LIN_Active : 23|1@1+ (1,0) [0|1] "" Vector__XXX
 SG_ Status_SideLight : 24|1@1+ (1,0) [0|1] "" Vector__XXX
 SG_ Status_Headlights : 25|1@1+ (1,0) [0|1] "" Vector__XXX
 SG_ Status_Alarm_still : 26|1@1+ (1,0) [0|1] "" Vector__XXX
 SG_ Status_Texte : 27|4@1+ (1,0) [0|15] "" Vector__XXX
 SG_ Status_ChargeRelay : 38|1@1+ (1,0) [0|1] "" Vector__XXX
 SG_ Status_Buzzer : 48|1@1+ (1,0) [0|1] "" Vector__XXX
 SG_ Status_Alarm_Indicator : 50|1@1+ (1,0) [0|1] "" Vector__XXX
 SG_ Status_EmergencyStart : 51|1@1+ (1,0) [0|1] "" Vector__XXX
 SG_ Status_Horn : 55|1@1+ (1,0) [0|1] "" Vector__XXX
 SG_ Status_IdleShift : 56|1@1+ (1,0) [0|1] "" Motor_Diesel_MQB,Motor_Hybrid_MQB,Motor_Otto_MQB

BO_ 1413 SystemInfo_01: 8 Gateway_MQB
 SG_ SI_Collective_ECU_Error : 0|6@1+ (1,0) [0|60] "" Vector__XXX
 SG_ SI_Rollenmode : 6|2@1+ (1,0) [0|3] "" Vector__XXX
 SG_ SI_QRS_Mode : 8|1@1+ (1,0) [0|1] "" Motor_Diesel_MQB,Motor_Hybrid_MQB,Motor_Otto_MQB
 SG_ SI_T_Mode : 9|1@1+ (1,0) [0|1] "" Vector__XXX
 SG_ SI_NWDF : 10|1@1+ (1,0) [0|1] "" SAK_MQB
 SG_ SI_NWDF_Valid : 11|1@1+ (1,0) [0|1] "" SAK_MQB
 SG_ SI_GeneralFault : 12|1@1+ (1,0) [0|1] "" Vector__XXX
 SG_ GW_KD_Error : 13|1@1+ (1,0) [0|1] "" Vector__XXX
 SG_ SI_BUS_01 : 16|1@1+ (1,0) [0|1] "" Vector__XXX
 SG_ SI_BUS_02 : 17|1@1+ (1,0) [0|1] "" Vector__XXX
 SG_ SI_BUS_03 : 18|1@1+ (1,0) [0|1] "" Vector__XXX
 SG_ SI_BUS_04 : 19|1@1+ (1,0) [0|1] "" Vector__XXX
 SG_ SI_BUS_05 : 20|1@1+ (1,0) [0|1] "" Vector__XXX
 SG_ SI_BUS_06 : 21|1@1+ (1,0) [0|1] "" Vector__XXX
 SG_ SI_BUS_07 : 22|1@1+ (1,0) [0|1] "" Vector__XXX
 SG_ SI_BUS_08 : 23|1@1+ (1,0) [0|1] "" Vector__XXX
 SG_ SI_BUS_09 : 24|1@1+ (1,0) [0|1] "" Vector__XXX
 SG_ SI_BUS_10 : 25|1@1+ (1,0) [0|1] "" Vector__XXX
 SG_ SI_BUS_11 : 26|1@1+ (1,0) [0|1] "" Vector__XXX
 SG_ SI_BUS_12 : 27|1@1+ (1,0) [0|1] "" Vector__XXX
 SG_ SI_BUS_13 : 28|1@1+ (1,0) [0|1] "" Vector__XXX
 SG_ SI_BUS_14 : 29|1@1+ (1,0) [0|1] "" Vector__XXX
 SG_ SI_BUS_15 : 30|1@1+ (1,0) [0|1] "" Vector__XXX

BO_ 288 TSK_06: 8 Motor_Diesel_MQB
 SG_ CHECKSUM : 0|8@1+ (1,0) [0|255] "" Gateway_MQB,Getriebe_DQ_Hybrid_MQB,Getriebe_DQ_MQB
 SG_ COUNTER : 8|4@1+ (1,0) [0|15] "" Gateway_MQB,Getriebe_DQ_Hybrid_MQB,Getriebe_DQ_MQB
 SG_ TSK_WheelBrakeTorque : 12|12@1+ (8,0) [0|32760] "Unit_NewtoMeter" Gateway_MQB,Getriebe_DQ_Hybrid_MQB,Getriebe_DQ_MQB
 SG_ TSK_Status : 24|3@1+ (1,0) [0|7] "" Gateway_MQB,Getriebe_DQ_Hybrid_MQB,Getriebe_DQ_MQB
 SG_ TSK_v_Limit_Active : 27|1@1+ (1,0) [0|1] "" Gateway_MQB,Getriebe_DQ_Hybrid_MQB,Getriebe_DQ_MQB
 SG_ TSK_Standby_Req_ESP : 28|1@1+ (1,0) [0|1] "" Gateway_MQB
 SG_ TSK_Enable_WU : 29|1@1+ (1.0,0.0) [0.0|1] ""  Gateway_MQB
 SG_ TSK_Enable_Decel_Req : 30|1@1+ (1,0) [0|1] "" Gateway_MQB,Getriebe_DQ_Hybrid_MQB,Getriebe_DQ_MQB
 SG_ TSK_Limiter_Selected : 31|1@1+ (1,0) [0|1] "" Gateway_MQB,Getriebe_DQ_Hybrid_MQB,Getriebe_DQ_MQB
 SG_ TSK_Request_Ratio : 32|10@1+ (0.0245,0) [0.0245|25.0635] ""  Gateway_MQB
 SG_ TSK_MainSwitch_GRA_ACC : 42|2@1+ (1.0,0.0) [0.0|3] ""  Gateway_MQB
 SG_ TSK_SRBM_Req_ASIL : 44|3@1+ (1.0,0.0) [0.0|7] ""  Gateway_MQB
 SG_ TSK_ax_Gearbox_02 : 48|9@1+ (0.024,-2.016) [-2.016|10.224] "Unit_MeterPerSeconSquar" Gateway_MQB,Getriebe_DQ_Hybrid_MQB,Getriebe_DQ_MQB
 SG_ TSK_Zwangszusch_ESP : 57|1@1+ (1,0) [0|1] "" Gateway_MQB
 SG_ TSK_Allowed_ControlDeviation : 58|6@1+ (0.024,0) [0|1.512] "Unit_MeterPerSeconSquar" Gateway_MQB,Getriebe_DQ_Hybrid_MQB,Getriebe_DQ_MQB

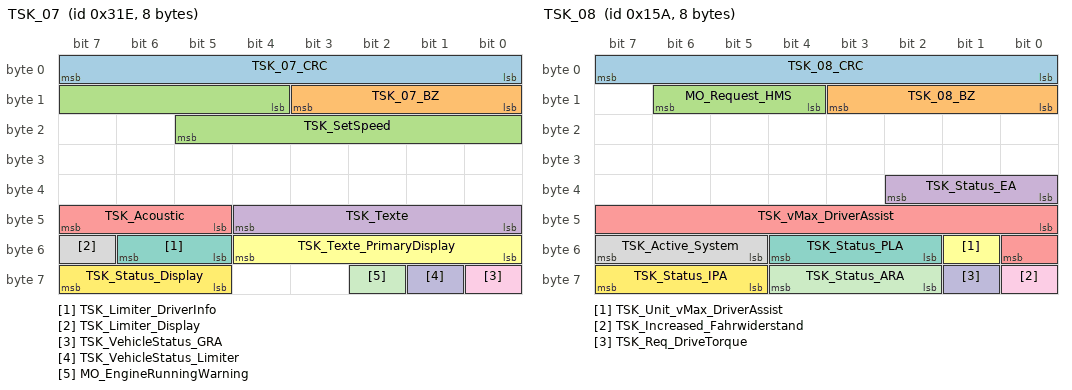
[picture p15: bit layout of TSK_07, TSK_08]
BO_ 798 TSK_07: 8 Motor_Diesel_MQB
 SG_ TSK_07_CRC : 0|8@1+ (1,0) [0|255] ""  Gateway_MQB,Getriebe_AQ
 SG_ TSK_07_BZ : 8|4@1+ (1,0) [0|15] ""  Gateway_MQB,Getriebe_AQ
 SG_ TSK_SetSpeed : 12|10@1+ (0.32,0) [0.00|326.72] "Unit_KiloMeterPerHour"  Gateway_MQB,Getriebe_AQ
 SG_ TSK_Texte : 40|5@1+ (1.0,0.0) [0.0|31] ""  Gateway_MQB
 SG_ TSK_Acoustic : 45|3@1+ (1.0,0.0) [0.0|7] ""  Gateway_MQB
 SG_ TSK_Texte_PrimaryDisplay : 48|5@1+ (1.0,0.0) [0.0|31] ""  Gateway_MQB
 SG_ TSK_Limiter_DriverInfo : 53|2@1+ (1.0,0.0) [0.0|3] ""  Gateway_MQB
 SG_ TSK_Limiter_Display : 55|1@1+ (1.0,0.0) [0.0|1] ""  Gateway_MQB
 SG_ TSK_VehicleStatus_GRA : 56|1@1+ (1.0,0.0) [0.0|1] ""  Gateway_MQB
 SG_ TSK_VehicleStatus_Limiter : 57|1@1+ (1.0,0.0) [0.0|1] ""  Gateway_MQB
 SG_ MO_EngineRunningWarning : 58|1@1+ (1.0,0.0) [0.0|1] ""  Gateway_MQB
 SG_ TSK_Status_Display : 61|3@1+ (1.0,0.0) [0.0|7] ""  Gateway_MQB

BO_ 346 TSK_08: 8 Motor_Diesel_MQB
 SG_ TSK_08_CRC : 0|8@1+ (1,0) [0|255] ""  Frontradar
 SG_ TSK_08_BZ : 8|4@1+ (1,0) [0|15] ""  Frontradar
 SG_ MO_Request_HMS : 12|3@1+ (1,0) [0|7] "" Vector__XXX
 SG_ TSK_Status_EA : 32|3@1+ (1,0) [0|7] "" Vector__XXX
 SG_ TSK_vMax_DriverAssist : 40|9@1+ (1,0) [0|510] ""  Frontradar
 SG_ TSK_Unit_vMax_DriverAssist : 49|1@1+ (1,0) [0|1] ""  Frontradar
 SG_ TSK_Status_PLA : 50|3@1+ (1,0) [0|7] "" Vector__XXX
 SG_ TSK_Active_System : 53|3@1+ (1,0) [0|7] "" Vector__XXX
 SG_ TSK_Increased_Fahrwiderstand : 56|1@1+ (1,0) [0|1] "" Vector__XXX
 SG_ TSK_Req_DriveTorque : 57|1@1+ (1,0) [0|1] "" Vector__XXX
 SG_ TSK_Status_ARA : 58|3@1+ (1,0) [0|7] "" Vector__XXX
 SG_ TSK_Status_IPA : 61|3@1+ (1,0) [0|7] "" Vector__XXX

BO_ 1716 VIN_01: 8 Gateway_MQB
 SG_ VIN_01_MUX M : 0|2@1+ (1,0) [0|3] ""  Airbag_MQB
 SG_ KS_Secret_1 m0 : 8|8@1+ (1,0) [0|255] "" Vector__XXX
 SG_ VIN_4 m1 : 8|8@1+ (1,0) [0|255] ""  Airbag_MQB
 SG_ VIN_11 m2 : 8|8@1+ (1,0) [0|255] ""  Airbag_MQB
 SG_ KS_Secret_2 m0 : 16|8@1+ (1,0) [0|255] "" Vector__XXX
 SG_ VIN_5 m1 : 16|8@1+ (1,0) [0|255] ""  Airbag_MQB
 SG_ VIN_12 m2 : 16|8@1+ (1,0) [0|255] ""  Airbag_MQB
 SG_ KS_Secret_3 m0 : 24|8@1+ (1,0) [0|255] "" Vector__XXX
 SG_ VIN_6 m1 : 24|8@1+ (1,0) [0|255] ""  Airbag_MQB
 SG_ VIN_13 m2 : 24|8@1+ (1,0) [0|255] ""  Airbag_MQB
 SG_ KS_Secret_4 m0 : 32|8@1+ (1,0) [0|255] "" Vector__XXX
 SG_ VIN_7 m1 : 32|8@1+ (1,0) [0|255] ""  Airbag_MQB
 SG_ VIN_14 m2 : 32|8@1+ (1,0) [0|255] ""  Airbag_MQB
 SG_ VIN_1 m0 : 40|8@1+ (1,0) [0|255] ""  Airbag_MQB
 SG_ VIN_8 m1 : 40|8@1+ (1,0) [0|255] ""  Airbag_MQB
 SG_ VIN_15 m2 : 40|8@1+ (1,0) [0|255] ""  Airbag_MQB
 SG_ VIN_2 m0 : 48|8@1+ (1,0) [0|255] ""  Airbag_MQB
 SG_ VIN_9 m1 : 48|8@1+ (1,0) [0|255] ""  Airbag_MQB
 SG_ VIN_16 m2 : 48|8@1+ (1,0) [0|255] ""  Airbag_MQB
 SG_ VIN_3 m0 : 56|8@1+ (1,0) [0|255] ""  Airbag_MQB
 SG_ VIN_10 m1 : 56|8@1+ (1,0) [0|255] ""  Airbag_MQB
 SG_ VIN_17 m2 : 56|8@1+ (1,0) [0|255] ""  Airbag_MQB

BO_ 175 SelectorLever_03: 4 Waehlhebel_MQB
 SG_ WH_Status_Lock : 0|3@1+ (1,0) [0|7] "" Getriebe_DQ_Hybrid_MQB,Getriebe_DQ_MQB
 SG_ WH_Initialisation : 3|1@1+ (1,0) [0|1] "" Getriebe_DQ_Hybrid_MQB,Getriebe_DQ_MQB
 SG_ WH_SensorPos_Raw : 4|4@1+ (1,0) [0|15] "" Getriebe_DQ_Hybrid_MQB,Getriebe_DQ_MQB
 SG_ WH_03_BZ : 8|4@1+ (1,0) [0|15] "" Getriebe_DQ_Hybrid_MQB,Getriebe_DQ_MQB
 SG_ WH_SensorPos_Raw_inv : 12|4@1+ (1,0) [0|15] "" Getriebe_DQ_Hybrid_MQB,Getriebe_DQ_MQB
 SG_ WH_TestResult : 16|8@1+ (1,0) [0|255] "" Getriebe_DQ_Hybrid_MQB,Getriebe_DQ_MQB
 SG_ WH_Test_Active : 24|1@1+ (1,0) [0|1] "" Getriebe_DQ_Hybrid_MQB,Getriebe_DQ_MQB
 SG_ WH_Status : 25|7@1+ (1,0) [0|127] "" Getriebe_DQ_Hybrid_MQB,Getriebe_DQ_MQB

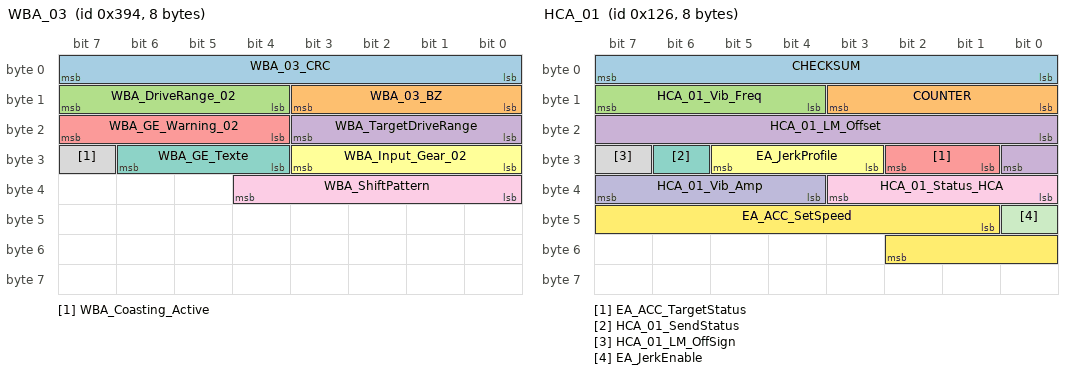
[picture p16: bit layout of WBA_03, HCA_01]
BO_ 916 WBA_03: 8 Getriebe_DQ_Hybrid_MQB
 SG_ WBA_03_CRC : 0|8@1+ (1,0) [0|255] "" Gateway_MQB
 SG_ WBA_03_BZ : 8|4@1+ (1,0) [0|15] "" Gateway_MQB
 SG_ WBA_DriveRange_02 : 12|4@1+ (1,0) [0|15] "" Gateway_MQB
 SG_ WBA_TargetDriveRange : 16|4@1+ (1,0) [0|15] "" Gateway_MQB
 SG_ WBA_GE_Warning_02 : 20|4@1+ (1,0) [0|15] "" Gateway_MQB
 SG_ WBA_Input_Gear_02 : 24|4@1+ (1,0) [0|15] "" Gateway_MQB,Motor_Diesel_MQB,Motor_Otto_MQB
 SG_ WBA_GE_Texte : 28|3@1+ (1,0) [0|7] "" Gateway_MQB
 SG_ WBA_Coasting_Active : 31|1@1+ (1,0) [0|1] "" Gateway_MQB
 SG_ WBA_ShiftPattern : 32|5@1+ (1,0) [0|31] "" Gateway_MQB

BO_ 1602 WIV_01: 8 Motor_Diesel_MQB
 SG_ WIV_WearIndex : 0|16@1+ (2e-8,0) [0|0.00131068] "" Gateway_MQB
 SG_ WIV_SootIndex : 16|16@1+ (2e-8,0) [0|0.00131068] "" Gateway_MQB
 SG_ WIV_t_min : 32|6@1+ (1,0) [0|63] "Unit_Month" Gateway_MQB
 SG_ WIV_t_max : 40|6@1+ (1,0) [0|63] "Unit_Month" Gateway_MQB
 SG_ WIV_W_min : 48|7@1+ (1000,0) [0|127000] "Unit_KiloMeter" Gateway_MQB
 SG_ WIV_W_max : 56|7@1+ (1000,0) [0|127000] "Unit_KiloMeter" Gateway_MQB

BO_ 294 HCA_01: 8 Frontsensorik
 SG_ CHECKSUM : 0|8@1+ (1,0) [0|255] "" Vector__XXX
 SG_ COUNTER : 8|4@1+ (1,0) [0|15] "" Vector__XXX
 SG_ HCA_01_Vib_Freq : 12|4@1+ (1,15) [15|30] "Unit_Hertz" Vector__XXX
 SG_ HCA_01_LM_Offset : 16|9@1+ (1,0) [0|511] "Unit_centiNewtoMeter" Vector__XXX
 SG_ EA_ACC_TargetStatus : 25|2@1+ (1,0) [0|3] ""  Frontradar
 SG_ EA_JerkProfile : 27|3@1+ (1,0) [0|7] "" Vector__XXX
 SG_ HCA_01_SendStatus : 30|1@1+ (1,0) [0|1] "" Vector__XXX
 SG_ HCA_01_LM_OffSign : 31|1@1+ (1,0) [0|1] "" Vector__XXX
 SG_ HCA_01_Status_HCA : 32|4@1+ (1,0) [0|15] "" Vector__XXX
 SG_ HCA_01_Vib_Amp : 36|4@1+ (0.2,0) [0|3] "Unit_NewtoMeter" Vector__XXX
 SG_ EA_JerkEnable : 40|1@1+ (1,0) [0|1] "" Vector__XXX
 SG_ EA_ACC_SetSpeed : 41|10@1+ (0.32,0) [0|327.04] "Unit_KiloMeterPerHour"  Frontradar

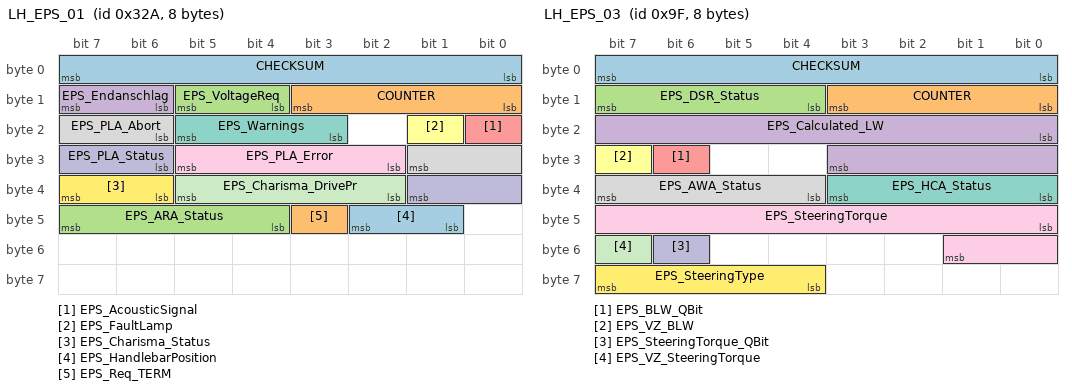
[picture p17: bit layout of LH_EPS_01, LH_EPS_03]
BO_ 810 LH_EPS_01: 8 XXX
 SG_ CHECKSUM : 0|8@1+ (1,0) [0|255] "" XXX
 SG_ COUNTER : 8|4@1+ (1,0) [0|15] "" XXX
 SG_ EPS_VoltageReq : 12|2@1+ (1.0,0.0) [0.0|3] "" XXX
 SG_ EPS_Endanschlag : 14|2@1+ (1.0,0.0) [0.0|3] "" XXX
 SG_ EPS_AcousticSignal : 16|1@1+ (1.0,0.0) [0.0|1] "" XXX
 SG_ EPS_FaultLamp : 17|1@1+ (1.0,0.0) [0.0|1] "" XXX
 SG_ EPS_Warnings : 19|3@1+ (1.0,0.0) [0.0|7] "" XXX
 SG_ EPS_PLA_Abort : 22|4@1+ (1,0) [0|15] "" XXX
 SG_ EPS_PLA_Error : 26|4@1+ (1,0) [0|15] "" XXX
 SG_ EPS_PLA_Status : 30|4@1+ (1.0,0.0) [0.0|15] "" XXX
 SG_ EPS_Charisma_DrivePr : 34|4@1+ (1.0,0.0) [0.0|15] "" XXX
 SG_ EPS_Charisma_Status : 38|2@1+ (1.0,0.0) [0.0|3] "" XXX
 SG_ EPS_HandlebarPosition : 41|2@1+ (1.0,0.0) [0.0|3] "" XXX
 SG_ EPS_Req_TERM : 43|1@1+ (1.0,0.0) [0.0|1] "" XXX
 SG_ EPS_ARA_Status : 44|4@1+ (1.0,0.0) [0.0|15] "" XXX

BO_ 159 LH_EPS_03: 8 XXX
 SG_ CHECKSUM : 0|8@1+ (1,0) [0|255] ""  XXX
 SG_ COUNTER : 8|4@1+ (1,0) [0|15] ""  XXX
 SG_ EPS_DSR_Status : 12|4@1+ (1,0) [0|15] ""  XXX
 SG_ EPS_Calculated_LW : 16|12@1+ (0.15,0) [0|613.95] "Unit_DegreOfArc"  XXX
 SG_ EPS_BLW_QBit : 30|1@1+ (1,0) [0|1] ""  XXX
 SG_ EPS_VZ_BLW : 31|1@1+ (1,0) [0|1] ""  XXX
 SG_ EPS_HCA_Status : 32|4@1+ (1,0) [0|15] ""  XXX
 SG_ EPS_AWA_Status : 36|4@1+ (1,0) [0|14] ""  XXX
 SG_ EPS_SteeringTorque : 40|10@1+ (1,0) [0|8] "Unit_centiNewtoMeter"  XXX
 SG_ EPS_SteeringTorque_QBit : 54|1@1+ (1,0) [0|1] ""  XXX
 SG_ EPS_VZ_SteeringTorque : 55|1@1+ (1,0) [0|1] ""  XXX
 SG_ EPS_SteeringType : 60|4@1+ (1,0) [0|15] ""  XXX

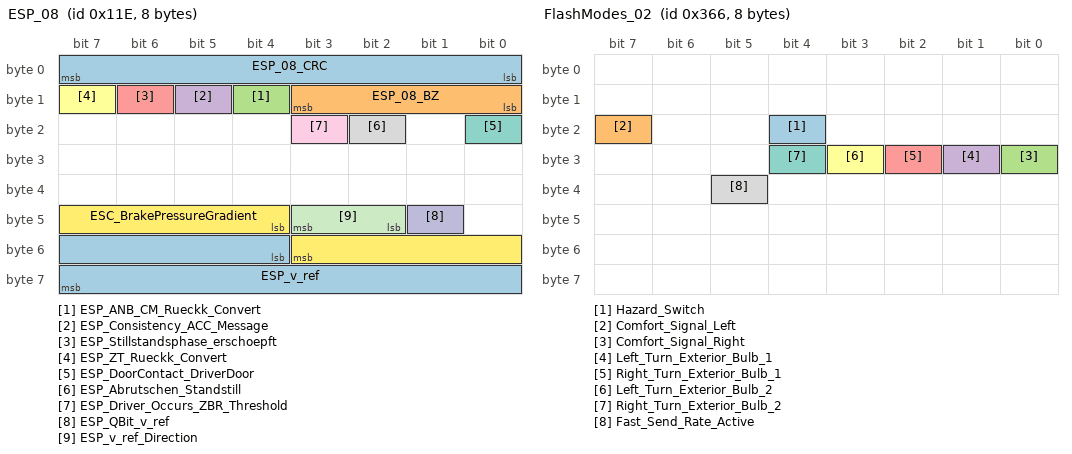
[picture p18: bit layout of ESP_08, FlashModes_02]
BO_ 286 ESP_08: 8 Gateway_MQB
 SG_ ESP_08_CRC : 0|8@1+ (1,0) [0|255] ""  XXX
 SG_ ESP_08_BZ : 8|4@1+ (1,0) [0|15] ""  XXX
 SG_ ESP_ANB_CM_Rueckk_Convert : 12|1@1+ (1.0,0.0) [0.0|1] ""  XXX
 SG_ ESP_Consistency_ACC_Message : 13|1@1+ (1.0,0.0) [0.0|1] ""  XXX
 SG_ ESP_Stillstandsphase_erschoepft : 14|1@1+ (1.0,0.0) [0.0|1] ""  XXX
 SG_ ESP_ZT_Rueckk_Convert : 15|1@1+ (1.0,0.0) [0.0|1] ""  XXX
 SG_ ESP_DoorContact_DriverDoor : 16|1@1+ (1.0,0.0) [0.0|1] ""  XXX
 SG_ ESP_Abrutschen_Standstill : 18|1@1+ (1.0,0.0) [0.0|1] ""  XXX
 SG_ ESP_Driver_Occurs_ZBR_Threshold : 19|1@1+ (1.0,0.0) [0.0|1] ""  XXX
 SG_ ESP_QBit_v_ref : 41|1@1+ (1.0,0.0) [0.0|1] ""  XXX
 SG_ ESP_v_ref_Direction : 42|2@1+ (1.0,0.0) [0.0|3] ""  XXX
 SG_ ESC_BrakePressureGradient : 44|8@1+ (10,0) [0|2500] "Unit_BarPerSecon"  XXX
 SG_ ESP_v_ref : 52|12@1+ (0.125,0) [0.000|511.500] "Unit_KiloMeterPerHour"  XXX

BO_ 919 LDW_02: 8 XXX
 SG_ LDW_Chime : 12|2@1+ (1,0) [0|3] ""  XXX
 SG_ LDW_SW_Warning_Left : 14|1@1+ (1,0) [0|1] ""  XXX
 SG_ LDW_SW_Warning_Right : 15|1@1+ (1,0) [0|1] ""  XXX
 SG_ LDW_Texte : 16|4@1+ (1,0) [0|15] ""  XXX
 SG_ LDW_Side_DLCTLC : 20|1@1+ (1,0) [0|1] ""  XXX
 SG_ LDW_LearnMode : 21|3@1+ (1,0) [0|7] ""  XXX
 SG_ LDW_Anlaufsp_VLR : 24|4@1+ (1,0) [0|15] ""  XXX
 SG_ LDW_Vib_Amp_VLR : 28|4@1+ (1,0) [0|15] ""  XXX
 SG_ LDW_StartUpTime_VLR : 32|4@1+ (1,0) [0|15] ""  XXX
 SG_ LDW_LearnMode_Right : 36|2@1+ (1,0) [0|3] ""  XXX
 SG_ LDW_LearnMode_Left : 38|2@1+ (1,0) [0|3] ""  XXX
 SG_ LDW_DLC : 40|8@1+ (0.01,-1.25) [-1.25|1.25] "Unit_Meter"  XXX
 SG_ LDW_TLC : 48|5@1+ (0.1,0) [0|3] "Unit_Secon"  XXX
 SG_ LDW_Warning_Left : 56|1@1+ (1,0) [0|1] ""  XXX
 SG_ LDW_Warning_Right : 57|1@1+ (1,0) [0|1] ""  XXX
 SG_ LDW_CodingInfo_For_VLR : 58|2@1+ (1,0) [0|3] ""  XXX
 SG_ LDW_WindscreenHeating_Active : 60|1@1+ (1,0) [0|1] ""  XXX
 SG_ LDW_Status_LED_Yellow : 61|1@1+ (1,0) [0|1] ""  XXX
 SG_ LDW_Status_LED_Green : 62|1@1+ (1,0) [0|1] ""  XXX
 SG_ LDW_KD_Error : 63|1@1+ (1,0) [0|1] ""  XXX

BO_ 780 ACC_02: 8 XXX
 SG_ CHECKSUM : 0|8@1+ (1,0) [0|255] ""  XXX
 SG_ COUNTER : 8|4@1+ (1,0) [0|15] ""  XXX
 SG_ ACC_SetSpeed_02 : 12|10@1+ (0.32,0) [0|327.04] "Unit_KiloMeterPerHour"  XXX
 SG_ ACC_Status_Prim_Disp : 22|2@1+ (1,0) [0|3] ""  XXX
 SG_ ACC_DistanceIndex : 24|10@1+ (1,0) [1|1021] ""  XXX
 SG_ ACC_Acoustic_02 : 34|2@1+ (1,0) [0|3] ""  XXX
 SG_ ACC_Warning_TrafficSign_1 : 36|1@1+ (1,0) [0|1] ""  XXX
 SG_ ACC_Set_TimeGap : 37|3@1+ (1,0) [0|7] ""  XXX
 SG_ ACC_Optical_DriverNotice : 40|1@1+ (1,0) [0|1] ""  XXX
 SG_ ACC_Type_SpeedoScale : 41|1@1+ (1,0) [0|1] ""  XXX
 SG_ ACC_Display_TimeGap : 42|1@1+ (1,0) [0|1] ""  XXX
 SG_ ACC_SpeedoScale : 43|1@1+ (1,0) [0|1] ""  XXX
 SG_ ACC_Display_Prio : 44|2@1+ (1,0) [0|3] ""  XXX
 SG_ ACC_Relevant_Object : 46|2@1+ (1,0) [0|3] ""  XXX
 SG_ ACC_Texte_PrimaryDisplay : 48|7@1+ (1,0) [0|127] ""  XXX
 SG_ ACC_SetSpeed_Reached : 55|1@1+ (1,0) [0|1] ""  XXX
 SG_ ACC_Type_SpeedoScale_Bottom : 60|1@1+ (1,0) [0|1] ""  XXX
 SG_ ACC_Status_Display : 61|3@1+ (1,0) [0|7] ""  XXX

BO_ 302 ACC_07: 8 XXX
 SG_ CHECKSUM : 0|8@1+ (1,0) [0|255] ""  XXX
 SG_ COUNTER : 8|4@1+ (1,0) [0|15] ""  XXX
 SG_ ACC_StoppingDistance : 12|11@1+ (0.01,0) [0|20.45] "Unit_Meter"  XXX
 SG_ ACC_Stop : 23|1@1+ (1,0) [0|1] ""  XXX
 SG_ ACC_Boost_Req : 24|1@1+ (1,0) [0|1] ""  XXX
 SG_ ACC_Freewheel_Req : 25|1@1+ (1,0) [0|1] ""  XXX
 SG_ ACC_Freewheel_Info : 26|2@1+ (1,0) [0|3] ""  XXX
 SG_ ACC_Request_HMS : 28|3@1+ (1,0) [0|7] ""  XXX
 SG_ ACC_PullAway : 31|1@1+ (1,0) [0|1] ""  XXX
 SG_ ACC_Folgebeschl : 32|8@1+ (0.03,-4.6) [-4.6|2.99] "Unit_MeterPerSeconSquar"  XXX
 SG_ ACC_TargetAcceleration_02 : 53|11@1+ (0.005,-7.22) [-7.22|3.005] "Unit_MeterPerSeconSquar"  XXX

BO_ 264 Chassis_01: 8 XXX
 SG_ Chassis_01_BZ : 8|4@1+ (1,0) [0|15] "" XXX
 SG_ Chassis_01_CRC : 0|8@1+ (1,0) [0|255] "" XXX

BO_ 695 RCTA_01: 8 XXX
 SG_ RCTA_01_BZ : 8|4@1+ (1,0) [0|15] "" XXX
 SG_ RCTA_01_CRC : 0|8@1+ (1,0) [0|255] "" XXX

BO_ 783 SWA_01: 8 Gateway_MQB
 SG_ CHECKSUM : 0|8@1+ (1,0) [0|255] ""  XXX
 SG_ COUNTER : 8|4@1+ (1,0) [0|15] ""  XXX
 SG_ SWA_Display : 12|4@1+ (1,0) [0|15] ""  XXX
 SG_ SWA_Blindness_Detected : 16|1@1+ (1,0) [0|1] ""  XXX
 SG_ SWA_rel_NotAvail : 17|1@1+ (1,0) [0|1] ""  XXX
 SG_ SWA_rel_Error : 18|1@1+ (1,0) [0|1] ""  XXX
 SG_ SWA_Status_Active : 19|1@1+ (1,0) [0|1] ""  XXX
 SG_ SWA_Status_Passive : 20|1@1+ (1,0) [0|1] ""  XXX
 SG_ SWA_FT_RueckLED : 21|1@1+ (1,0) [0|1] ""  XXX
 SG_ ASW_Status : 22|2@1+ (1,0) [0|3] ""  XXX
 SG_ SWA_StationaryTargets_Left : 24|1@1+ (1,0) [0|1] ""  XXX
 SG_ SWA_Queue_Left : 25|1@1+ (1,0) [0|1] ""  XXX
 SG_ SWA_InfoLevel_SWA_Left : 26|1@1+ (1,0) [0|1] ""  XXX
 SG_ SWA_Warning_SWA_Left : 27|1@1+ (1,0) [0|1] ""  XXX
 SG_ ASW_Warning_FS : 28|1@1+ (1,0) [0|1] ""  XXX
 SG_ ASW_Warning_BFS : 29|1@1+ (1,0) [0|1] ""  XXX
 SG_ ASW_Kombitexte : 30|3@1+ (1,0) [0|7] ""  XXX
 SG_ SWA_Queue_mi : 33|1@1+ (1,0) [0|1] ""  XXX
 SG_ SWA_StationaryTargets_Right : 40|1@1+ (1,0) [0|1] ""  XXX
 SG_ SWA_Queue_Right : 41|1@1+ (1,0) [0|1] ""  XXX
 SG_ SWA_InfoLevel_SWA_Right : 42|1@1+ (1,0) [0|1] ""  XXX
 SG_ SWA_Warning_SWA_Right : 43|1@1+ (1,0) [0|1] ""  XXX
 SG_ HRE_Anzeigetexte : 44|4@1+ (1,0) [0|15] ""  XXX
 SG_ SWA_Gischtzaehler : 48|7@1+ (1,0) [0|100] "Unit_PerCent"  XXX
 SG_ Heckradar_Kombitexte : 56|5@1+ (1,0) [0|31] ""  XXX
 SG_ RCTA_Kombitexte : 61|3@1+ (1,0) [0|7] ""  XXX

BO_ 804 ACC_04: 8 XXX
 SG_ CHECKSUM : 0|8@1+ (1,0) [0|255] ""  XXX
 SG_ COUNTER : 8|4@1+ (1,0) [0|15] ""  XXX
 SG_ ACC_Texte_SecondaryDisplay : 12|4@1+ (1,0) [0|15] ""  XXX
 SG_ ACC_Texte_AuxDisplay : 16|6@1+ (1,0) [0|63] ""  XXX
 SG_ ACC_Status_AuxDisplay : 22|5@1+ (1,0) [0|31] ""  XXX
 SG_ ACC_Texte : 27|5@1+ (1,0) [0|31] ""  XXX
 SG_ ACC_Texte_braking_guard : 32|3@1+ (1,0) [0|7] ""  XXX
 SG_ ACC_WarningNote : 35|1@1+ (1,0) [0|1] ""  XXX
 SG_ ACC_TimeGap_DistanceWarner : 36|6@1+ (0.1,0) [0|6] "Unit_Secon"  XXX
 SG_ ACC_Distance_DistanceWarner : 42|9@1+ (1,0) [0|508] ""  XXX
 SG_ ACC_SpeedLimit : 51|5@1+ (1,0) [0|31] ""  XXX
 SG_ ACC_Charisma_DrivePr : 56|4@1+ (1,0) [0|15] ""  XXX
 SG_ ACC_Charisma_Status : 60|2@1+ (1,0) [0|3] ""  XXX
 SG_ ACC_Texte_DistanceWarner : 62|2@1+ (1,0) [0|3] ""  XXX

BO_ 917 LWR_AFS_01: 8 XXX

BO_ 991 Gateway_76: 8 XXX

BO_ 997 DoorECU_FT_02: 8 XXX
 SG_ DoorECU_FT_02_BZ : 8|4@1+ (1,0) [0|15] "" XXX
 SG_ DoorECU_FT_02_CRC : 0|8@1+ (1,0) [0|255] "" XXX

BO_ 1175 ParkAssist_01: 8 XXX

BO_ 427 ESP_33: 8 Gateway_MQB
 SG_ CHECKSUM : 0|8@1+ (1,0) [0|255] ""  Motor_Hybrid_MQB,Motor_Otto_MQB
 SG_ COUNTER : 8|4@1+ (1,0) [0|15] ""  Motor_Hybrid_MQB,Motor_Otto_MQB
 SG_ ESC_AHW_Active : 12|3@1+ (1,0) [0|7] ""  Motor_Hybrid_MQB,Motor_Otto_MQB
 SG_ ESC_AHW_Not_Available : 15|1@1+ (1,0) [0|1] ""  Vector__XXX
 SG_ ESC_ANB_CM_Active : 16|2@1+ (1,0) [0|3] ""  Motor_Hybrid_MQB,Motor_Otto_MQB
 SG_ ESC_ANB_CM_Not_Available : 18|1@1+ (1,0) [0|1] ""  Vector__XXX
 SG_ ESC_WarnJerk_Active : 19|4@1+ (1,0) [0|15] ""  Motor_Hybrid_MQB,Motor_Otto_MQB
 SG_ ESC_WarnJerk_Not_Available : 23|1@1+ (1,0) [0|1] ""  Vector__XXX
 SG_ ESC_Prefill_Active : 24|1@1+ (1,0) [0|1] ""  Vector__XXX
 SG_ ESC_Prefill_Not_Available : 25|1@1+ (1,0) [0|1] ""  Vector__XXX
 SG_ ESC_HBA_Active : 26|1@1+ (1,0) [0|1] ""  Airbag_MQB
 SG_ ESC_HBA_Not_Available : 27|1@1+ (1,0) [0|1] ""  Airbag_MQB
 SG_ ESC_TSK_SRBM_Req : 28|1@1+ (1,0) [0|1] ""  Motor_Hybrid_MQB,Motor_Otto_MQB
 SG_ ESC_TSK_SRBM_Not_Available : 29|1@1+ (1,0) [0|1] ""  Motor_Hybrid_MQB,Motor_Otto_MQB
 SG_ ESC_Decel_Reg_Active : 30|4@1+ (1,0) [0|15] ""  Airbag_MQB,Motor_Hybrid_MQB,Motor_Otto_MQB
 SG_ ESC_Decel_Reg_Not_Available : 34|1@1+ (1,0) [0|1] ""  Airbag_MQB,Motor_Hybrid_MQB,Motor_Otto_MQB
 SG_ ESC_Decel_Reg_TB_Not_Available : 35|1@1+ (1,0) [0|1] ""  Vector__XXX
 SG_ ESC_Decel_Reg_ZB_Not_Available : 36|1@1+ (1,0) [0|1] ""  Vector__XXX
 SG_ ESC_BrakeLight_Implausible : 37|1@1+ (1,0) [0|1] ""  Motor_Hybrid_MQB,Motor_Otto_MQB
 SG_ ESC_Consistency_ACC : 38|1@1+ (1,0) [0|1] ""  Vector__XXX
 SG_ ESC_Consistency_AWV : 39|1@1+ (1,0) [0|1] ""  Vector__XXX
 SG_ ESC_Consistency_ARA : 40|1@1+ (1,0) [0|1] ""  Vector__XXX
 SG_ ESC_Consistency_IPA : 41|1@1+ (1,0) [0|1] ""  Vector__XXX
 SG_ ESC_Consistency_FCW : 42|1@1+ (1,0) [0|1] ""  Vector__XXX
 SG_ ESC_Consistency_NV : 43|1@1+ (1,0) [0|1] ""  Vector__XXX
 SG_ ESC_Consistency_RCTA : 44|1@1+ (1,0) [0|1] ""  Vector__XXX
 SG_ ESC_Consistency_TSK : 45|1@1+ (1,0) [0|1] ""  Motor_Hybrid_MQB,Motor_Otto_MQB
 SG_ ESC_Consistency_vFGS : 46|1@1+ (1,0) [0|1] ""  Vector__XXX
 SG_ ESC_Consistency_Status : 47|1@1+ (1,0) [0|1] ""  Vector__XXX
 SG_ ESC_Driver_BrakePressure_bestimmend : 48|1@1+ (1,0) [0|1] ""  Motor_Hybrid_MQB,Motor_Otto_MQB
 SG_ ESC_Consistency_EA : 49|1@1+ (1,0) [0|1] ""  Vector__XXX
 SG_ ESC_Consistency_BFF : 50|1@1+ (1,0) [0|1] ""  Vector__XXX
 SG_ ESC_Consistency_MKB : 51|1@1+ (1,0) [0|1] ""  Airbag_MQB
 SG_ ESC_Decel_ASIL_Availability : 52|3@1+ (1,0) [0|7] ""  Airbag_MQB,Motor_Hybrid_MQB,Motor_Otto_MQB
 SG_ ESC_PumpStartUp_Active : 55|1@1+ (1,0) [0|1] ""  Vector__XXX
 SG_ ESC_Consistency_AGW : 56|1@1+ (1,0) [0|1] ""  Vector__XXX
 SG_ ESC_Consistency_KAS : 57|1@1+ (1,0) [0|1] ""  Vector__XXX
 SG_ ESC_Consistency_PCF : 58|1@1+ (1,0) [0|1] ""  Vector__XXX
 SG_ ESC_Consistency_FAS_VK : 59|1@1+ (1,0) [0|1] ""  Vector__XXX
 SG_ ESC_Decel_Limit : 60|1@1+ (1,0) [0|1] ""  Vector__XXX
 SG_ ESC_Consistency_AWA : 61|1@1+ (1,0) [0|1] ""  Vector__XXX

BO_ 418 ESP_15: 8 XXX
 SG_ ESP_15_CRC : 0|8@1+ (1,0) [0|255] "" XXX
 SG_ ESP_15_BZ : 8|4@1+ (1,0) [0|15] "" XXX

BO_ 1122 PSD_04: 8 XXX
 SG_ PSD_Object_Index : 0|6@1+ (1,0) [0|63] "" XXX

BO_ 1123 PSD_05: 8 XXX
 SG_ PSD_Current_Route_Index : 0|6@1+ (1,0) [0|63] "" XXX
 SG_ Route_Distance_Remaining : 8|5@1+ (1,0) [0|31] "" XXX

BO_ 1124 PSD_06: 8 XXX

BO_ 988 Gateway_73: 8 XXX
 SG_ UNKNOWN_1 : 15|2@0+ (1,0) [0|3] "" XXX
 SG_ GE_DriveRange : 40|4@1+ (1,0) [0|15] "" XXX
 SG_ EPB_Status : 53|3@1+ (1,0) [0|7] "" XXX
 SG_ UNKNOWN_2 : 58|3@0+ (1,0) [0|7] "" XXX

BO_ 792 Camera_Status: 8 XXX

BO_ 981 Light_Req_01: 8 Vector__XXX
 SG_ CHECKSUM : 0|8@1+ (1,0) [0|255] "" Vector__XXX
 SG_ COUNTER : 8|4@1+ (1,0) [0|15] "" Vector__XXX
 SG_ BCM1_CorneringLight_Left_Req : 12|1@1+ (1,0) [0|1] "" Vector__XXX
 SG_ BCM1_CorneringLight_Right_Req : 13|1@1+ (1,0) [0|1] "" Vector__XXX
 SG_ BCM1_SideLight_Req : 14|1@1+ (1,0) [0|1] "" Vector__XXX
 SG_ BCM1_LowBeam_Req : 15|1@1+ (1,0) [0|1] "" Vector__XXX
 SG_ BCM1_HighBeam_Req : 16|1@1+ (1,0) [0|1] "" Vector__XXX
 SG_ BCM1_FogLight_Req : 17|1@1+ (1,0) [0|1] "" Vector__XXX
 SG_ BCM1_ParkingLight_Left_Req : 18|1@1+ (1,0) [0|1] "" Vector__XXX
 SG_ BCM1_ParkingLight_Right_Req : 19|1@1+ (1,0) [0|1] "" Vector__XXX
 SG_ BCM1_RearFog_Ahg_Req : 20|1@1+ (1,0) [0|1] "" Vector__XXX
 SG_ BCM1_RearFog_Veh_Req : 21|1@1+ (1,0) [0|1] "" Vector__XXX
 SG_ BCM1_TailLight_Req : 22|1@1+ (1,0) [0|1] "" Vector__XXX
 SG_ BCM_ReversingLight_Req : 23|1@1+ (1,0) [0|1] "" Vector__XXX
 SG_ BCM1_SignatureLight_Req : 24|1@1+ (1,0) [0|1] "" Vector__XXX
 SG_ BCM1_Umfeldleuchten_Req : 25|1@1+ (1,0) [0|1] "" Vector__XXX
 SG_ BCM1_DaytimeRunningLight_Req : 26|1@1+ (1,0) [0|1] "" Vector__XXX
 SG_ BCM1_RainLight_Req : 27|1@1+ (1,0) [0|1] "" Vector__XXX
 SG_ BCM1_MotorwayLight_Req : 28|1@1+ (1,0) [0|1] "" Vector__XXX
 SG_ BCM1_Tourist_Light_Req : 29|1@1+ (1,0) [0|1] ""  Frontradar
 SG_ BCM1_CH_Active : 30|1@1+ (1,0) [0|1] "" Vector__XXX
 SG_ BCM1_LH_Active : 31|1@1+ (1,0) [0|1] "" Vector__XXX
 SG_ BCM1_Sliding_Leuchtw_Req : 32|1@1+ (1,0) [0|1] "" Vector__XXX
 SG_ BCM1_GLW_HighBeam_Req : 33|1@1+ (1,0) [0|1] "" Vector__XXX
 SG_ BCM1_Adaptive_LightDistribution_Req : 34|1@1+ (1,0) [0|1] "" Vector__XXX
 SG_ BCM1_CH_LH_Active : 40|1@1+ (1,0) [0|1] "" Vector__XXX
 SG_ BCM1_AllWeatherLight_Req : 41|1@1+ (1,0) [0|1] ""  Frontradar

BO_ 1440 RLS_01: 8 XXX

BO_ 870 FlashModes_02: 8 XXX
 SG_ Hazard_Switch : 20|1@1+ (1,0) [0|1] ""  XXX
 SG_ Comfort_Signal_Left : 23|1@1+ (1,0) [0|1] ""  XXX
 SG_ Comfort_Signal_Right : 24|1@1+ (1,0) [0|1] ""  XXX
 SG_ Left_Turn_Exterior_Bulb_1 : 25|1@1+ (1,0) [0|1] ""  XXX
 SG_ Right_Turn_Exterior_Bulb_1 : 26|1@1+ (1,0) [0|1] ""  XXX
 SG_ Left_Turn_Exterior_Bulb_2 : 27|1@1+ (1,0) [0|1] ""  XXX
 SG_ Right_Turn_Exterior_Bulb_2 : 28|1@1+ (1,0) [0|1] ""  XXX
 SG_ Fast_Send_Rate_Active : 37|1@1+ (1,0) [0|1] ""  XXX

BO_ 1385 HVEM_04: 8 XXX

BO_ 1605 FLA_01: 8 XXX

BO_ 1624 Light_Front_01: 8 XXX

BO_ 1646 Climate_03: 8 XXX

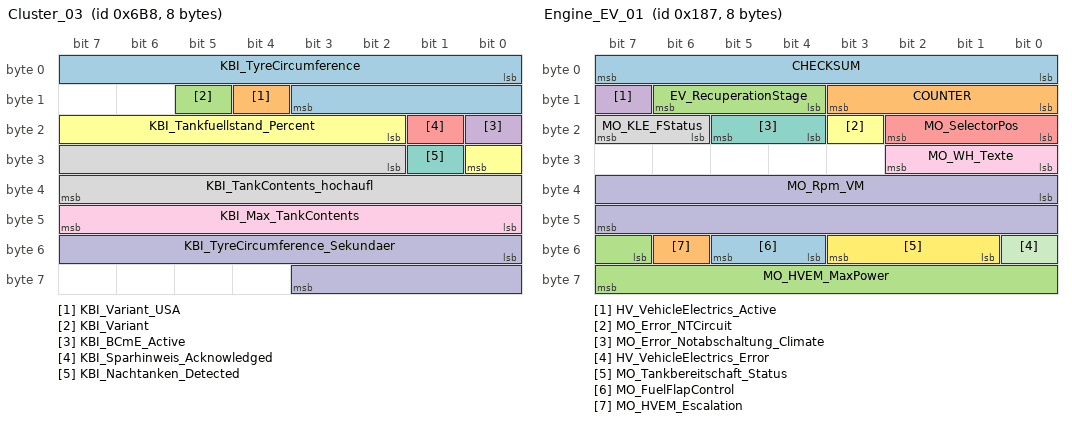
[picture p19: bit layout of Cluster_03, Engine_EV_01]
BO_ 1720 Cluster_03: 8 XXX
 SG_ KBI_TyreCircumference : 0|12@1+ (1,0) [0|4095] "Unit_MilliMeter"  XXX
 SG_ KBI_Variant_USA : 12|1@1+ (1.0,0.0) [0.0|1] ""  XXX
 SG_ KBI_Variant : 13|1@1+ (1.0,0.0) [0.0|1] ""  XXX
 SG_ KBI_BCmE_Active : 16|1@1+ (1.0,0.0) [0.0|1] ""  XXX
 SG_ KBI_Sparhinweis_Acknowledged : 17|1@1+ (1.0,0.0) [0.0|1] ""  XXX
 SG_ KBI_Tankfuellstand_Percent : 18|7@1+ (1,0) [0|100] "Unit_PerCent"  XXX
 SG_ KBI_Nachtanken_Detected : 25|1@1+ (1.0,0.0) [0.0|1] ""  XXX
 SG_ KBI_TankContents_hochaufl : 26|14@1+ (0.01,0) [0.00|163.81] "Unit_Liter"  XXX
 SG_ KBI_Max_TankContents : 40|8@1+ (0.5,0) [0.0|126.5] ""  XXX
 SG_ KBI_TyreCircumference_Sekundaer : 48|12@1+ (1,0) [0|4095] "Unit_MilliMeter"  XXX

BO_ 391 Engine_EV_01: 8 Motor_MQB_BEV
 SG_ CHECKSUM : 0|8@1+ (1,0) [0|255] ""  XXX
 SG_ COUNTER : 8|4@1+ (1,0) [0|15] ""  XXX
 SG_ EV_RecuperationStage : 12|3@1+ (1.0,0.0) [0.0|7] ""  XXX
 SG_ HV_VehicleElectrics_Active : 15|1@1+ (1.0,0.0) [0.0|1] ""  XXX
 SG_ MO_SelectorPos : 16|3@1+ (1.0,0.0) [0.0|7] ""  XXX
 SG_ MO_Error_NTCircuit : 19|1@1+ (1.0,0.0) [0.0|1] ""  XXX
 SG_ MO_Error_Notabschaltung_Climate : 20|2@1+ (1.0,0.0) [0.0|3] ""  XXX
 SG_ MO_KLE_FStatus : 22|2@1+ (1.0,0.0) [0.0|3] ""  XXX
 SG_ MO_WH_Texte : 24|3@1+ (1.0,0.0) [0.0|7] ""  XXX
 SG_ MO_Rpm_VM : 32|16@1+ (0.25,0) [0.00|16383.00] "Unit_MinutInver"  XXX
 SG_ HV_VehicleElectrics_Error : 48|1@1+ (1.0,0.0) [0.0|1] ""  XXX
 SG_ MO_Tankbereitschaft_Status : 49|3@1+ (1.0,0.0) [0.0|7] ""  XXX
 SG_ MO_FuelFlapControl : 52|2@1+ (1.0,0.0) [0.0|3] ""  XXX
 SG_ MO_HVEM_Escalation : 54|1@1+ (1.0,0.0) [0.0|1] ""  XXX
 SG_ MO_HVEM_MaxPower : 55|9@1+ (50,0) [0|25450] "Unit_Watt"  XXX

CM_ SG_ 134 LWI_SteeringWheelAngle "Steering angle WITH variable ratio effect included [DE: LWI_Lenkradwinkel]";
CM_ SG_ 159 EPS_HCA_Status "Status of Heading Control Assist feature";
CM_ SG_ 159 EPS_SteeringTorque "Steering input by driver, torque [DE: EPS_Lenkmoment]";
CM_ SG_ 159 EPS_VZ_SteeringTorque "Steering input by driver, direction [DE: EPS_VZ_Lenkmoment]";
CM_ SG_ 159 EPS_Calculated_LW "Raw steering angle, degrees [DE: EPS_Berechneter_LW]";
CM_ SG_ 159 EPS_VZ_BLW "Raw steering angle, direction";
CM_ SG_ 173 COUNTER_DISABLED "Message not renamed to COUNTER because J533 rate-limiting makes it look like messages are being lost";
CM_ SG_ 294 HCA_01_Vib_Freq "Frequenz der Lenkradvibration";
CM_ SG_ 294 HCA_01_LM_Offset "Von HCA angefordertes Lenkmoment (Betrag)";
CM_ SG_ 294 EA_ACC_TargetStatus "Status-Anforderung ACC von Emergency Alert. Statuswechsel bei Flanke. Solange Wert=1, wird EA_ACC_Wunschgeschwindigkeit übernommen. Wert=2 führt zu Zustand ¿ACC_GRA_passiv¿ [DE: EA_ACC_Sollstatus]";
CM_ SG_ 294 EA_JerkProfile "Emergency Alert Anforderung an ESP, welcher Ruck verwendet werden soll. Eine Umsetzung der Ruckanforderung im ESP erfolgt nur mit gesetztem Bit 'EA_Ruckfreigabe'. [DE: EA_Ruckprofil]";
CM_ SG_ 294 HCA_01_SendStatus "Gibt den Sendestatus der HCA_01 an (notwendig für IL-Unterstützung) [DE: HCA_01_Sendestatus]";
CM_ SG_ 294 HCA_01_LM_OffSign "Vorzeichen des HCA-Lenkmoments";
CM_ SG_ 294 HCA_01_Status_HCA "Statusinformation vom HCA und Manoevrierassistent für Handshakemechanismus mit der Lenkung";
CM_ SG_ 294 HCA_01_Vib_Amp "Momentenamplitude der Lenkradvibration";
CM_ SG_ 294 EA_JerkEnable "Emergency Alert Freigabit für die Warnruck-Anforderung an das ESP [DE: EA_Ruckfreigabe]";
CM_ SG_ 294 EA_ACC_SetSpeed "Emergency Alert Anforderung neue Wunschgeschwindigkeit [DE: EA_ACC_Wunschgeschwindigkeit]";
CM_ SG_ 302 ACC_Hold_Request "Active request for ABS brake hold in ACC_Hold_Type";
CM_ SG_ 302 ACC_Boost_Request "Hybrid engine start related";
CM_ SG_ 302 ACC_Freewheel_Request "Active request for DSG sailing/coasting in ACC_Freewheel_Type";
CM_ SG_ 302 ACC_Hold_Release "Request to ABS to release brake hold";
CM_ SG_ 302 ACC_Accel_Secondary "Target acceleration of the secondary controller";
CM_ SG_ 302 ACC_Accel_TSK "Mirror of request to TSK to implement a target acceleration";
CM_ SG_ 304 PLA_BrakeTorque_Decel "0=PLA_Bremsmoment, 1=PLA_Bremsverzoegerung/PLA_Anf_Bremsverzoegerung. [DE: PLA_BremsMom_Verzoeg]";
CM_ SG_ 870 Hazard_Switch "Four-way flashers active";
CM_ SG_ 870 Comfort_Signal_Left "Comfort turn signal active, left";
CM_ SG_ 870 Comfort_Signal_Right "Comfort turn signal active, right";
CM_ SG_ 870 Left_Turn_Exterior_Bulb_1 "Probably front";
CM_ SG_ 870 Right_Turn_Exterior_Bulb_1 "Probably front";
CM_ SG_ 870 Left_Turn_Exterior_Bulb_2 "Probably rear";
CM_ SG_ 870 Right_Turn_Exterior_Bulb_2 "Probably rear";
CM_ SG_ 870 Fast_Send_Rate_Active "CAN message send rate";
CM_ SG_ 919 LDW_DLC "Probable DLC (distance to line crossing)";
CM_ SG_ 919 LDW_TLC "Probable TLC (time to line crossing)";
CM_ SG_ 919 LDW_Unknown "Might be a steering pressed / driver active flag";
CM_ SG_ 919 Alert_Message "Static table of alert messages to be invoked in the instrument cluster, some with or without beeps, 0 = no current message";
CM_ SG_ 919 LDW_Direction "Left/right indicator for DLC and TLC";
CM_ SG_ 919 Right_Lane_Status "Display brightness range, 0 = no lane, 3 = full brightness";
CM_ SG_ 919 Left_Lane_Status "Display brightness range, 0 = no lane, 3 = full brightness";
CM_ SG_ 919 Kombi_Lamp_Orange "Enables orange LDW light in instrument cluster";
CM_ SG_ 919 Kombi_Lamp_Green "Enables green LDW light in instrument cluster";
CM_ SG_ 780 Folgefahrt "Following another vehicle";
CM_ SG_ 780 SetAbstand "Set following distance";
CM_ SG_ 780 Abstand "Following distance";
CM_ SG_ 780 SetSpeed "ACC set speed";
CM_ SG_ 391 MO_SelectorPos "Traditional PRND plus B-mode aggressive regen, B-mode mapped to Drive [DE: MO_Waehlpos]";
CM_ SG_ 679 ACC_ADAPTIVE "TSK_06.TSK_Limiter_ausgewaehlt seems to take precedence";
CM_ SG_ 960 ZAS_Term_15 "Indicates ignition on [DE: ZAS_Kl_15]";
CM_ SG_ 1720 KBI_BCmE_Active "Anzeige BCmE aktiv (BCmE-Screen oder Einsparhinweis in der Anzeige) [DE: KBI_BCmE_aktiv]";
CM_ SG_ 1720 KBI_Max_TankContents "Mitteilung des maximalen Tankinhalts an das Reichweitenmodul [DE: KBI_Max_Tankinhalt]";
CM_ SG_ 1720 KBI_Nachtanken_Detected "Statusinformation Nachtankmodus [DE: KBI_Nachtanken_erkannt]";
CM_ SG_ 1720 KBI_TyreCircumference "Mittlerer Radumfang aus der K-Zahl gerechnet in Millimeter.  Byte 2 Bit 5,4 reserviert, Byte 2 Bit 3..0 und Byte 1 Bit 7..0; Wertebereich 0..4096 mm
 [DE: KBI_Reifenumfang]";
CM_ SG_ 1720 KBI_TyreCircumference_Sekundaer "Fahrzeuge mit unterschiedlichen Reifenumfängen Vorderachse / Hinterachse:

Primärachse: KBI_Reifenumfang
Sekundärachse: KBI_Reifenumfang_Sekundaer
 [DE: KBI_Reifenumfang_Sekundaer]";
CM_ SG_ 1720 KBI_Sparhinweis_Acknowledged "angezeigter Sparhinweis ist quittiert. Signal wird nach zwei Sendebotschaften wieder auf '0' gesetzt. [DE: KBI_Sparhinweis_quittiert]";
CM_ SG_ 1720 KBI_Tankfuellstand_Percent "Tankfüllstand in % [DE: KBI_Tankfuellstand_Prozent]";
CM_ SG_ 1720 KBI_TankContents_hochaufl "angezeigter Tankinhalt hochauflösend zur Restreichweitenberechnung [DE: KBI_Tankinhalt_hochaufl]";
CM_ SG_ 1720 KBI_Variant "Zeigt an ob es sich um ein konventionelles Zeiger-Kombiinstrument handelt oder um eine Volldisplay-Kombiinstrument [DE: KBI_Variante]";
CM_ SG_ 1720 KBI_Variant_USA "In diesem Signal wird die HW-Variante des Kombis ausgegeben, ACC plausibilisiert auf dieses Signal hin seine US-Codierung [DE: KBI_Variante_USA]";

VAL_ 159 EPS_HCA_Status 0 "disabled" 1 "initializing" 2 "fault" 3 "ready" 4 "rejected" 5 "active" 8 "preempted" ;
VAL_ 159 EPS_AWA_Status 0 "AWA_Deactivated" 1 "AWA_Req_Not_ausfuehrbar" 2 "Comm_AWA_Disturbed" 3 "EPS_bzgl_AWA_Operational" 4 "AWA_Req_abgewiesen" 5 "AWA_TorqueIntervention_1_Active" 7 "AWA_TorqueIntervention_2_Active" 8 "AWA_abgewiesen_Momentenpriorisierung" 9 "Req_abgewiesen_Bedienueblich" 14 "Init" ;
VAL_ 173 GE_DriveRange 5 "P" 6 "R" 7 "N" 8 "D" 9 "S" 10 "E" 13 "T" 14 "T" ;
VAL_ 279 AWV_AWA_Status_EPS 0 "AWA_deactivated" 1 "AWA_request_not_executable" 2 "EPS_communication_disturbed" 3 "AWA_ready" 5 "AWA_torque_intervention_1" 7 "AWA_torque_intervention_2" ;
VAL_ 288 TSK_Status 0 "init" 1 "disabled" 2 "enabled" 3 "regulating" 4 "accel_pedal_override" 5 "brake_only" 6 "temp_fault" 7 "perm_fault" ;
VAL_ 288 TSK_v_Limit_Active 0 "Inactive" 1 "Active" ;
VAL_ 288 TSK_Standby_Req_ESP 0 "No_Standby_Request" 1 "Standby_Request" ;
VAL_ 288 TSK_Enable_WU 0 "TSK_RatioRequest_Not_Enabled" 1 "TSK_RatioRequest_Enabled" ;
VAL_ 288 TSK_Enable_Decel_Req 0 "DecelerationRequest_Not_Enabled" 1 "DecelerationRequest_Enabled" ;
VAL_ 288 TSK_Limiter_Selected 0 "No_Limiter_Selected" 1 "Limiter_Selected" ;
VAL_ 288 TSK_Request_Ratio 0 "Init" ;
VAL_ 288 TSK_MainSwitch_GRA_ACC 0 "Init" 1 "Off" 2 "On" 3 "Error" ;
VAL_ 288 TSK_ax_Gearbox_02 511 "NeutralValue" ;
VAL_ 288 TSK_Zwangszusch_ESP 0 "No_ESP_ASR_Influence" 1 "ESP_ASR_Influence" ;
VAL_ 294 EA_ACC_TargetStatus 0 "Init" 1 "ACC_Activate" 2 "ACC_Deactivate" ;
VAL_ 294 EA_JerkProfile 0 "Init" 1 "Profile_1" 2 "Profile_2" 3 "Profile_3" 4 "Profile_4" 5 "Profile_5" 6 "Profile_6" 7 "Profile_7" ;
VAL_ 294 HCA_01_SendStatus 0 "HCA_Sends_With_1000ms" 1 "HCA_Sends_With_20ms" ;
VAL_ 294 HCA_01_LM_OffSign 0 "Positive_Sign" 1 "Negative_Sign" ;
VAL_ 294 HCA_01_Status_HCA 0 "Deactivated" 1 "Reserved" 2 "Reserved" 3 "Operational" 4 "Reserved" 5 "HCA_TorqueIntervention_1" 6 "MA_Active" 7 "HCA_TorqueIntervention_2" 8 "Reserved" 9 "Reserved" 10 "Reserved" 11 "Reserved" 12 "Reserved" 13 "Reserved" 14 "Reserved" 15 "Reserved" ;
VAL_ 294 EA_JerkEnable 0 "No_Enable" 1 "Enable" ;
VAL_ 294 EA_ACC_SetSpeed 1023 "Init" ;
VAL_ 346 MO_Request_HMS 0 "No_Request" 1 "Hold" 2 "Parking" 3 "Hold_Standby" 4 "PullAway" 5 "Release_Over_Ramp" ;
VAL_ 346 TSK_Status_EA 0 "Off" 1 "Init_Or_Not_Fitted" 3 "Active" 4 "Override" 5 "Shutdown_Running" 6 "Reversible_Off" 7 "Irreversible_Off" ;
VAL_ 346 TSK_vMax_DriverAssist 511 "Init_Invalid_No_Beschraenkung" ;
VAL_ 346 TSK_Unit_vMax_DriverAssist 0 "kmh" 1 "mph" ;
VAL_ 346 TSK_Status_PLA 0 "Off_Operational" 1 "Init_Or_Not_Fitted" 2 "Activatable" 3 "Active" 5 "Shutdown_Running" 6 "Reversible_Off" 7 "Error" ;
VAL_ 346 TSK_Active_System 0 "No_Function_Active" 1 "GRA_ACC" 2 "ARA" 3 "Speedlimiter" 4 "IPA" 5 "PLA" 6 "PEA_Ausrollassistent" 7 "EA" ;
VAL_ 346 TSK_Increased_Fahrwiderstand 0 "No_Increased_Fahrwiderstand" 1 "Increased_Fahrwiderstand" ;
VAL_ 346 TSK_Req_DriveTorque 0 "No_Request" 1 "Request_Active" ;
VAL_ 346 TSK_Status_ARA 0 "Off" 1 "Init_Or_Not_Fitted" 2 "Activatable" 3 "Active" 5 "Shutdown_Running" 6 "Reversible_Off" 7 "Error" ;
VAL_ 346 TSK_Status_IPA 0 "Off_Operational" 1 "Init_Or_Not_Fitted" 2 "Activatable" 3 "Active" 5 "Shutdown_laueft" 6 "Reversible_Off" 7 "Error" ;
VAL_ 798 TSK_SetSpeed 1022 "No_Display" 1023 "No_Value_In_Memory" ;
VAL_ 798 TSK_Texte 0 "No_Text" 1 "GRA_Mode_Selected" 2 "ACC_Mode_Selected" 3 "Lim_Mode_Selected" 4 "Lim_Not_Available_ESC_Passive" 5 "GRA_Not_Available_ESC_Passive" 6 "Lim_Not_Available_Charisma" 7 "GRA_Not_Available_Charisma" 8 "Lim_Not_Available_HDC" 9 "GRA_Not_Available_HDC" ;
VAL_ 798 TSK_Acoustic 0 "No_Acoustic" 1 "einzelner_WarningTone" 2 "dauerhafter_WarningTone" ;
VAL_ 798 TSK_Texte_PrimaryDisplay 0 "No_Display" 1 "GRA_Symbol_Passive_xxx_kmh_mph" 2 "GRA_Symbol_Active_xxx_kmh_mph" 3 "Brake_Overheated" 4 "Limiter_Mode_Activated" 5 "GRA_Mode_Activated" 6 "ACC_Mode_Activated" 7 "Opt_SpeedWarning" 8 "Opt_And_akustische_SpeedWarning" 9 "Opt_SpeedWarning_Permanent_With_einmal_Acoustic" 10 "Limiter_Passive_With_Acoustic" 11 "Limiter_Error_With_Acoustic" 12 "Limiter_Symbol_Passive_xxx_kmh_mph" 13 "Limiter_Symbol_Active_xxx_kmh_mph" 14 "Popup_Speed_Closed_High__Resume_unzulaessig" ;
VAL_ 798 TSK_Limiter_DriverInfo 0 "No_Info" 1 "Limit_Reached" 2 "Exceeded" 3 "From_Driver_Overruled" ;
VAL_ 798 TSK_Limiter_Display 0 "Display_Display_GRA_ACC" 1 "Display_Display_Limiter" ;
VAL_ 798 TSK_VehicleStatus_GRA 0 "GRA_Available" 1 "GRA_Not_Available" ;
VAL_ 798 TSK_VehicleStatus_Limiter 0 "Limiter_Available" 1 "Limiter_Not_Available" ;
VAL_ 798 MO_EngineRunningWarning 0 "No_Display" 1 "Request_EngineRunningWarning" ;
VAL_ 798 TSK_Status_Display 0 "MainSwitch_Off" 1 "Init" 2 "Passive" 3 "Active" 4 "Override" 5 "Limitiierung_Active" 6 "Reversible_Off" 7 "Irreversible_Off" ;
VAL_ 780 ACC_SetSpeed_02 1023 "No_Display" ;
VAL_ 780 ACC_Status_Prim_Disp 0 "Symbol Not Illuminated" 1 "Colour 1 (Typical 'Green')" 2 "Colour 2 (Typical 'Red')" 3 "Colour 3 (Typical 'Yellow')" ;
VAL_ 780 ACC_DistanceIndex 0 "SpecialDisplay_Grey_Road" 1022 "SpecialDisplay_Grey_Road" 1023 "SpecialDisplay_Road_With_gruenem_roten_Range" ;
VAL_ 780 ACC_Acoustic_02 0 "No_Acoustic" 1 "HighPriority_Acoustic" 2 "LowPriority_Acoustic" 3 "HighPriority_DurationAcoustic" ;
VAL_ 780 ACC_Warning_TrafficSign_1 0 "No_Warning_InitialValue" 1 "Warning" ;
VAL_ 780 ACC_Set_TimeGap 0 "No_Display" 1 "TimeGap_1" 2 "TimeGap_2" 3 "TimeGap_3" 4 "TimeGap_4" 5 "TimeGap_5" 6 "Not_Defined" 7 "Not_Defined" ;
VAL_ 780 ACC_Optical_DriverNotice 0 "Optical_DriverNotice_OFF" 1 "Optical_DriverNotice_ON" ;
VAL_ 780 ACC_Type_SpeedoScale 0 "SpeedoScale_Long" 1 "SpeedoScale_Short" ;
VAL_ 780 ACC_Display_TimeGap 0 "Display_TimeGap_Not_Requested" 1 "Display_TimeGap_Requested" ;
VAL_ 780 ACC_SpeedoScale 0 "SpeedoScale_Not_Illuminated" 1 "SpeedoScale_Illuminated" ;
VAL_ 780 ACC_Display_Prio 0 "Highest_Prio" 1 "Average_Prio" 2 "Low_Prio" 3 "No_Prio" ;
VAL_ 780 ACC_Relevant_Object 0 "Symbol_Not_Illuminated" 1 "Colour_1_Typical_Green" 2 "Colour_2_Typical_Red" 3 "Colour_3_Typical_Yellow" ;
VAL_ 780 ACC_Texte_PrimaryDisplay 0 "No Display" 1 "ACC Not Available !" 2 "Auto_Auto_ _ _" 3 "Auto_ _Auto_ _" 4 "Auto_ _ _Auto_" 5 "Auto_ _ _ _Auto" 6 "Auto_Auto_ _ _ Chime (Crossed)" 7 "Auto_ _Auto_ _ Chime (Crossed)" 8 "Auto_ _ _Auto_ Chime (Crossed)" 9 "Auto_ _ _ _Auto Chime (Crossed)" 10 "ACC Ready" 11 "No DistanceControl" 12 "ACC Sensor View !" 13 "ACC Not Available" 14 "o  o  o" 15 "Upshift" 16 "ESP Intervention" 17 "Downshift" 18 "ParkingBrake !" 19 "SpeedLimit" 20 "SelectorLeverPosition !" 21 "VDA ACC-Symbol YYY km/h / mph" 22 "SpeedLimit XXX km/h / mph" 23 "Kurve XXX km/h / mph" 24 "ACC Shutdown" 25 "Symbol 'EggTimer'" 26 "!" 27 "--- km/h / mph" 28 "XXX km/h / mph (Schriftart 2)" 29 "SteeringWheelAngle" 30 "PullAway bestaetigen" 31 "Vehicle Lost" 32 "In Level Not Possible" 33 "Invalid PullAwayCommand" 34 "Door Open !" 35 "Driver BeltBuckle Open !" 36 "ShiftLeverPosition !" 37 "Rpm !" 38 "CurveAssist Off" 39 "SpeedLimit Off" 40 "Abbiegeassistent" 41 "Ortsanfang XXX km/h / mph" 42 "LocationEnd XXX km/h / mph" 43 "SpeedLimit End XXX km/h / mph" 44 "HDC Active" 45 "braking guard BrakeJerk" 46 "braking guard Off" 47 "braking guard Off" 48 "TakeOver !" 49 "Gradient Closed Large" 50 "Stationary Object Ahead" 51 "SET / 'GRA Symbol'___xxx km/h / mph" 52 "SET / 'GRA Symbol' xxx km/h / mph" 53 "ACC Off" 54 "ACC Starting" 55 "ACC Clean" 56 "ACC Error" 57 "ACC Holds On !" 58 "Brake Press !" 59 "Clutch Pressed" 60 "LIM OFF" 61 "LIM Active" 62 "LIM Passive" 63 "LIM Error" 64 "Brake Overheated !" 65 "Brake Holds !" 66 "ESP Passive !" 67 "ACC_PullAwayReady" 68 "Gear_Engage" 69 "RightOvertake_Prevented" 70 "LeftOvertake_Prevented" 71 "Caution_SpeedExceedance" 72 "SpeedLimit_And_CurveAssist_Not_Available" ;
VAL_ 780 ACC_SetSpeed_Reached 0 "SetSpeed_Not_Reached" 1 "SetSpeed_Reached" ;
VAL_ 780 ACC_Type_SpeedoScale_Bottom 0 "LEDs_On" 1 "LEDs_Off" ;
VAL_ 780 ACC_Status_Display 0 "ACC_GRA_MainSwitch_Off" 1 "ACC_in_Init_Not_At_GRA" 2 "ACC_GRA_Passive" 3 "ACC_GRA_Active" 4 "ACC_GRA_In_Background_Override" 5 "ACC_GRA_ShutdownReaction" 6 "ACC_Reversible_Off_Not_At_GRA" 7 "ACC_GRA_Irreversible_Off" ;
VAL_ 804 ACC_Texte_SecondaryDisplay 0 "No_Display" 1 "TargetVehicle_Detected" 2 "RightBend_Ahead" 3 "LeftBend_Ahead" 4 "SpeedLimit_Ahead" 5 "SensorView" 6 "PullAwayReady" 7 "SpeedLimit_Detected" 8 "Junction_Ahead" 9 "Roundabout_Ahead" ;
VAL_ 804 ACC_Texte_AuxDisplay 0 "No_Display" 1 "ACC_OFF" 2 "ACC_Ready" 3 "Override" 4 "Distance" 5 "Distance_1" 6 "Distance_2" 7 "Distance_3" 8 "Distance_4" 9 "Distance_1__Dyn" 10 "Distance_2__Dyn" 11 "Distance_3__Dyn" 12 "Distance_4__Dyn" 13 "Distance_1__Level" 14 "Distance_2__Level" 15 "Distance_3__Level" 16 "Distance_4__Level" 17 "Distance_1__comf" 18 "Distance_2__comf" 19 "Distance_3__comf" 20 "Distance_4__comf" 21 "Distance_1__efficiency" 22 "Distance_2__efficiency" 23 "Distance_3__efficiency" 24 "Distance_4__efficiency" 25 "Distance_5" 26 "Distance_5__Dyn" 27 "Distance_5__Level" 28 "Distance_5__comf" 29 "Distance_5__efficiency" 30 "Caution" 31 "DistanceDisplay" 32 "DistanceDisp_Warning_Activated" ;
VAL_ 804 ACC_Status_AuxDisplay 0 "No Display" 1 "Image 1 (Veh. Silhouette, Type. farblos)" 2 "Image 2 (Veh. Colour 1, Type. Grey)" 3 "Image 3 (Veh. Colour 2, Type. Red)" 4 "Image 4 (Symbol 1 ACCplus, Type. DoubleVehicle. Yellow)" 5 "Image 5 (Symbol 2 ACCplus, Type. DoubleVehicle. Grey)" 6 "Image 6 (Veh. Colour 2, Type. Red) With Priority In Cluster (Pop-up)" ;
VAL_ 804 ACC_Texte 0 "No_Display" 1 "ACC_Not_Available" 2 "ACC_And_AWV_Not_Available" 3 "ACC_No_SensorView" 4 "ACC_And_AWV_No_SensorView" 5 "ACC_Gradient_Closed_Large" 6 "ACC_Only_in_DriveRange_Available" 7 "ACC_ParkingBrake_Pressed" 8 "ACC_ESP_Intervention" 9 "ACC_Please_TakeOver" 10 "ACC_HDC_Pressed" 11 "ACC_SpeedLimit" 12 "ACC_ShiftLeverPosition" 13 "ACC_Rpm" 14 "ACC_Clutch_Pressed" 15 "ACC_Aktivierverhinderung" 16 "ACC_Shutdown" 17 "ACC_ParkAssistant_Active" 18 "ACC_ESC_Off" 19 "ACC_Charisma_Mode_Incompatible" 20 "ACC_Stationary_Object_Ahead" 21 "ACA_DriverTakeover" 22 "ACA_LateralGuidance_Not_Available" ;
VAL_ 804 ACC_Texte_braking_guard 0 "No_Display" 1 "AWV_Off" 2 "AWV_Warning" 3 "AWV_DemoMode" 4 "AWV_SystemMalfunction" 5 "AWV_Intervention" 6 "AWV_PreWarning_Off" 7 "AWV_No_SensorView" ;
VAL_ 804 ACC_WarningNote 0 "No_WarningNote" 1 "WarningNote" ;
VAL_ 804 ACC_TimeGap_DistanceWarner 61 "FreeJourney" 62 "Not_Defined" 63 "No_Display" ;
VAL_ 804 ACC_Distance_DistanceWarner 509 "FreeJourney" 510 "Not_Defined" 511 "No_Display" ;
VAL_ 804 ACC_SpeedLimit 0 "No_Display" 1 "5_AllowedMaxSpeed" 2 "7_AllowedMaxSpeed" 3 "10_AllowedMaxSpeed" 4 "15_AllowedMaxSpeed" 5 "20_AllowedMaxSpeed" 6 "25_AllowedMaxSpeed" 7 "30_AllowedMaxSpeed" 8 "35_AllowedMaxSpeed" 9 "40_AllowedMaxSpeed" 10 "45_AllowedMaxSpeed" 11 "50_AllowedMaxSpeed" 12 "55_AllowedMaxSpeed" 13 "60_AllowedMaxSpeed" 14 "65_AllowedMaxSpeed" 15 "70_AllowedMaxSpeed" 16 "75_AllowedMaxSpeed" 17 "80_AllowedMaxSpeed" 18 "85_AllowedMaxSpeed" 19 "90_AllowedMaxSpeed" 20 "95_AllowedMaxSpeed" 21 "100_AllowedMaxSpeed" 22 "110_AllowedMaxSpeed" 23 "120_AllowedMaxSpeed" 24 "130_AllowedMaxSpeed" 25 "140_AllowedMaxSpeed" 26 "150_AllowedMaxSpeed" 27 "160_AllowedMaxSpeed" 28 "200_AllowedMaxSpeed" 30 "250_AllowedMaxSpeed" 31 "End_AllowedMaxSpeed" ;
VAL_ 804 ACC_Charisma_DrivePr 0 "No_Function" 1 "Programm_1" 2 "Programm_2" 3 "Programm_3" 4 "Programm_4" 5 "Programm_5" 6 "Programm_6" 7 "Programm_7" 8 "Programm_8" 9 "Programm_9" 10 "Programm_10" 11 "Programm_11" 12 "Programm_12" 13 "Programm_13" 14 "Programm_14" 15 "Programm_15" ;
VAL_ 804 ACC_Charisma_Status 0 "Init" 1 "Available" 2 "Not_Available" 3 "Asynchronous_By_DriverDemand" ;
VAL_ 804 ACC_Texte_DistanceWarner 0 "No_Display" 1 "SystemMalfunction" 2 "No_SensorView" 3 "ToTime_Restricted" ;
VAL_ 290 ACC_Limited_PullAwayDyn 0 "No_Limitation" 1 "Limitation_PullAwayDynamics_Requested" ;
VAL_ 290 ACC_Retrofit_Stop_Req 0 "Not_Requested" 1 "Requested" ;
VAL_ 290 ACC_StartStop_Info 0 "EngineRunning_LongTerm_Not_Necessary_StopEnable" 1 "EngineStartUp_Not_Mandatory_Necessary_StopInhibit_No_StartRequest" 2 "EngineStartUp_Mandatory_Necessary_StartRequest" 3 "SystemError" ;
VAL_ 290 ACC_TargetAcceleration_02 2046 "NeutralValue" 2047 "Error" ;
VAL_ 290 ACC_PullAway 0 "No_Request_PullAway" 1 "Request_PullAway" ;
VAL_ 290 ACC_Stop 0 "No_Stop_Requested" 1 "Stop_Requested" ;
VAL_ 290 ACC_Type 0 "Base_ACC" 1 "ACC_With_FollowToStop" 2 "ACC_With_StopAndGo" 3 "ACC_Not_Coded" ;
VAL_ 290 ACC_Status_ACC 0 "ACC_OFF_MainSwitch_Off" 1 "ACC_INIT" 2 "ACC_STANDBY" 3 "ACC_Active_Controls" 4 "ACC_OVERRIDE" 5 "ACC_ShutdownReaction" 6 "Reversible_Error_In_ACC_System" 7 "Irreversible_Error_In_ACC_System" ;
VAL_ 290 ACC_Minimum_Braking 0 "Request_Minimum_Braking_Not_Active" 1 "Request_Minimum_Braking_Active" ;
VAL_ 302 ACC_StoppingDistance 2046 "NeutralValue" 2047 "Error" ;
VAL_ 302 ACC_Stop 0 "No_Stop_Requested" 1 "Stop_Requested" ;
VAL_ 302 ACC_Freewheel_Req 0 "No Freewheel-Request" 1 "Freewheel-Request" ;
VAL_ 302 ACC_Freewheel_Info 0 "Freewheel_Enabled" 1 "No_OverGear_in_Freewheel_Permitted" 2 "Freewheel_Not_Enabled" 3 "Freewheel_Request" ;
VAL_ 302 ACC_Request_HMS 0 "No_Request" 1 "Hold" 2 "Parking" 3 "Hold_Standby" 4 "PullAway" 5 "Release_Over_Ramp" ;
VAL_ 302 ACC_PullAway 0 "No_Request_PullAway" 1 "Request_PullAway" ;
VAL_ 302 ACC_Folgebeschl 254 "NeutralValue" ;
VAL_ 302 ACC_TargetAcceleration_02 2046 "NeutralValue" 2047 "Error" ;
VAL_ 279 AWV1_Req_Prefill 0 "Prefill_Not_Activate" 1 "Prefill_Activate" ;
VAL_ 279 ANB_CM_Info 0 "Standard" 1 "Extended" ;
VAL_ 279 AWV2_Enable 0 "No_Enable" 1 "Enable" ;
VAL_ 279 AWV1_HBA_Param 0 "Defaultparametersatz" 1 "ParameterSet_With_leicht_Increased_Sensitivity" 2 "ParameterSet_With_Increased_Sensitivity" 3 "ParameterSet_With_hoechster_Sensitivity" ;
VAL_ 279 AWV2_PrioWarning 0 "Display_Leave_The_Lane_Is_Not_Suppressed" 1 "Display_Leave_The_Lane_Is_Suppressed" ;
VAL_ 279 ANB_CM_Request 0 "No_Request" 1 "Request_Active" ;
VAL_ 279 ANB_Info_PartialBraking 0 "Variant_Standard" 1 "Variant_Extended" ;
VAL_ 279 ANB_EmergencyFlash 0 "No_ANB_EmergencyFlash" 1 "EmergencyFlash_ANB_Requested" ;
VAL_ 279 ANB_PartialBraking_Enable 0 "PartialBraking_Not_Enabled" 1 "PartialBraking_Enabled" ;
VAL_ 279 ANB_TargetBraking_Enable 0 "TargetBraking_Not_Enabled" 1 "TargetBraking_Enabled" ;
VAL_ 279 AWV_BeforeStage 0 "No_EmergencyBraking_erwartet" 1 "EmergencyBraking_in_Kuerze" ;
VAL_ 279 AWV_Hold 0 "No_Request" 1 "Request_The_Veh_In_Standstill_Closed_Hold" ;
VAL_ 279 AWV_CityANB_Variant 0 "Auto_Braking_In_Total_vRange" 1 "Auto_Braking_In_def_vRange" ;
VAL_ 279 PCF_Enable 0 "No_Enable_PreCrashFront" 1 "Enable_PreCrashFront" ;
VAL_ 279 AWV1_ECD_StartUp 0 "ECD_StartUp_Not_Activate" 1 "ECD_StartUp_Activate" ;
VAL_ 279 PCF_Time_to_collision 255 "ObjectStatus=0x0__Or_Calculated_TTC_Value_Greater_As_MaximumValue" ;
VAL_ 679 ACC_ControlSpeed 1023 "No_Display" ;
VAL_ 679 ACC_Unit_maxSetSpeed 0 "kmh" 1 "mph" ;
VAL_ 679 ACC_maxSetSpeed 511 "Init_NeutralValue" ;
VAL_ 679 ACC_minControlSpeed 255 "No_Display" ;
VAL_ 679 ACC_maxControlSpeed 255 "No_Display" ;
VAL_ 679 ACC_SpeedLimitAssist 0 "No_Display" 1 "SpeedLimitAssist_Active" 2 "SpeedLimitAssist_Not_Available" 3 "SpeedLimitAssist_DriverTakeover" ;
VAL_ 679 ACC_CurveAssist 0 "No_Display" 1 "Junction" 2 "RightBend" 3 "LeftBend" 4 "Roundabout" ;
VAL_ 679 ACC_RUV 0 "No_Display" 1 "RUV_Active_RightHandTraffic" 2 "RUV_Active_LeftHandTraffic" ;
VAL_ 679 ACC_SpeedoScale 0 "SpeedoScale_Not_Illuminated" 1 "SpeedoScale_Illuminated" ;
VAL_ 679 ACC_Type_SpeedoScale_Bottom 0 "LEDs_On" 1 "LEDs_Off" ;
VAL_ 679 ACC_ENG_Texte 0 "No_Display" 1 "No_Laenderverfuegbarkeit" 2 "Not_Available" 3 "SpeedLimit" ;
VAL_ 679 ACC_ADAPTIVE 1 "adaptive" 2 "non-adaptive" ;
VAL_ 681 AWV_Warning 0 "No_Display" 1 "Latent_PreWarning" 2 "PreWarning" 3 "AcuteWarning" 4 "Intervention" 5 "DriverTakeoverRequest" 6 "TurnWarning" ;
VAL_ 681 AWV_Texte 0 "No_Display" 1 "SystemMalfunction" 2 "No_SensorView" 3 "DemoMode" 4 "System_Off" 5 "Not_Defined" 6 "ESC_Off" 7 "ToTime_Restricted" ;
VAL_ 681 AWV_Status_Display 0 "Init" 1 "Available" 2 "Not_Available" ;
VAL_ 681 AWV_OnPosition_System_FSG 0 "Deactivated" 1 "Activated" ;
VAL_ 681 AWV_OnPosition_Warning_FSG 0 "Off" 1 "Setting_2" 2 "Setting_3" 3 "Setting_4" 4 "Setting_5" 5 "On" ;
VAL_ 681 AWV_Warnlevel 0 "No_Hazard" 63 "max_Hazard" ;
VAL_ 391 MO_SelectorPos 2 "P" 3 "R" 4 "N" 5 "D" 6 "D" ;
VAL_ 391 EV_RecuperationStage 0 "default" 1 "B1" 2 "B2" 3 "B3" ;
VAL_ 870 Fast_Send_Rate_Active 0 "1 Hz" 1 "50 Hz" ;
VAL_ 988 EPB_Status 0 "Open" 1 "Closed_Parking" 2 "PartlyTensioned_Hold" 3 "In_Run_Open" 4 "In_Run_Close" 5 "tbd" 6 "Init" 7 "Unknown";
VAL_ 988 GE_DriveRange 0 "BetweenPosition" 1 "Init" 5 "P" 6 "R" 7 "N" 8 "D" 9 "D" 10 "E" 13 "T" 14 "T" 15 "Error";
VAL_ 1720 KBI_Variant_USA 0 "No USA-Variant" 1 "USA-Variant" ;
VAL_ 1720 KBI_Variant 0 "Pointer InstrumentCluster" 1 "Volldisplay InstrumentCluster" ;
VAL_ 1720 KBI_BCmE_Active 0 "Display_Not_Active" 1 "Display_Active" ;
VAL_ 1720 KBI_Sparhinweis_Acknowledged 0 "Not_Acknowledged" 1 "Acknowledged" ;
VAL_ 1720 KBI_Tankfuellstand_Percent 126 "Init" 127 "Error" ;
VAL_ 1720 KBI_Nachtanken_Detected 0 "SenderOperation" 1 "AfterTankMode" ;
VAL_ 1720 KBI_TankContents_hochaufl 16382 "Init" 16383 "Error" ;
VAL_ 1720 KBI_Max_TankContents 254 "Init" 255 "Error" ;
CM_ SG_ 290 ACC_Limited_PullAwayDyn "[DE: ACC_limitierte_Anfahrdyn]";
CM_ SG_ 290 ACC_Retrofit_Stop_Req "[DE: ACC_nachtr_Stopp_Anf]";
CM_ SG_ 290 ACC_DynIncrease "[DE: ACC_DynErhoehung]";
CM_ SG_ 290 ACC_FreewheelStrategy_TSK "[DE: ACC_Freilaufstrategie_TSK]";
CM_ SG_ 290 ACC_Allowed_ControlDeviation_Bottom "[DE: ACC_zul_Regelabw_unten]";
CM_ SG_ 290 ACC_StartStop_Info "[DE: ACC_StartStopp_Info]";
CM_ SG_ 290 ACC_TargetAcceleration_02 "[DE: ACC_Sollbeschleunigung_02]";
CM_ SG_ 290 ACC_Allowed_ControlDeviation_Top "[DE: ACC_zul_Regelabw_oben]";
CM_ SG_ 290 ACC_Neg_TargetAccel_Degree_02 "[DE: ACC_neg_Sollbeschl_Grad_02]";
CM_ SG_ 290 ACC_pos_TargetAccel_Degree_02 "[DE: ACC_pos_Sollbeschl_Grad_02]";
CM_ SG_ 290 ACC_PullAway "[DE: ACC_Anfahren]";
CM_ SG_ 290 ACC_Stop "[DE: ACC_Anhalten]";
CM_ SG_ 290 ACC_Type "[DE: ACC_Typ]";
CM_ SG_ 290 ACC_Minimum_Braking "[DE: ACC_Minimale_Bremsung]";
CM_ SG_ 279 AWV1_Req_Prefill "[DE: AWV1_Anf_Prefill]";
CM_ SG_ 279 AWV2_Enable "[DE: AWV2_Freigabe]";
CM_ SG_ 279 AWV2_JerkProfile "[DE: AWV2_Ruckprofil]";
CM_ SG_ 279 AWV2_PrioWarning "[DE: AWV2_Priowarnung]";
CM_ SG_ 279 ANB_CM_Request "[DE: ANB_CM_Anforderung]";
CM_ SG_ 279 ANB_Info_PartialBraking "[DE: ANB_Info_Teilbremsung]";
CM_ SG_ 279 ANB_EmergencyFlash "[DE: ANB_Notfallblinken]";
CM_ SG_ 279 ANB_PartialBraking_Enable "[DE: ANB_Teilbremsung_Freigabe]";
CM_ SG_ 279 ANB_TargetBrake_Teilbrems_Decel_Req "[DE: ANB_Zielbrems_Teilbrems_Verz_Anf]";
CM_ SG_ 279 ANB_TargetBraking_Enable "[DE: ANB_Zielbremsung_Freigabe]";
CM_ SG_ 279 AWV_BeforeStage "[DE: AWV_Vorstufe]";
CM_ SG_ 279 AWV_Hold "[DE: AWV_Halten]";
CM_ SG_ 279 AWV_CityANB_Variant "[DE: AWV_CityANB_Auspraegung]";
CM_ SG_ 279 PCF_Enable "[DE: PCF_Freigabe]";
CM_ SG_ 279 AWV1_ECD_StartUp "[DE: AWV1_ECD_Anlauf]";
CM_ SG_ 279 AWV_AWA_VZ_Req_Lenkmomoffset "[DE: AWV_AWA_VZ_Anf_Lenkmomoffset]";
CM_ SG_ 279 AWV_AWA_Req_Lenkmomoffset "[DE: AWV_AWA_Anf_Lenkmomoffset]";
CM_ SG_ 304 PLA_LW_Target "[DE: PLA_LW_Soll]";
CM_ SG_ 304 PLA_VZ_LW_Target "[DE: PLA_VZ_LW_Soll]";
CM_ SG_ 304 PLA_BrakeTorque "[DE: PLA_Bremsmoment]";
CM_ SG_ 304 PLA_BrakeDeceleration "[DE: PLA_Bremsverzoegerung]";
CM_ SG_ 304 PLA_Req_BrakeDeceleration "[DE: PLA_Anf_Bremsverzoegerung]";
CM_ SG_ 304 PLA_Stop "[DE: PLA_Anhalten]";
CM_ SG_ 304 PLA_StoppingDistance "[DE: PLA_Anhalteweg]";
CM_ SG_ 679 ACC_ControlSpeed "[DE: ACC_Regelgeschw]";
CM_ SG_ 679 ACC_Unit_maxSetSpeed "[DE: ACC_Einheit_maxSetzgeschw]";
CM_ SG_ 679 ACC_maxSetSpeed "[DE: ACC_maxSetzgeschw]";
CM_ SG_ 679 ACC_minControlSpeed "[DE: ACC_minRegelgeschw]";
CM_ SG_ 679 ACC_maxControlSpeed "[DE: ACC_maxRegelgeschw]";
CM_ SG_ 679 ACC_SpeedLimitAssist "[DE: ACC_Tempolimitassistent]";
CM_ SG_ 679 ACC_CurveAssist "[DE: ACC_Kurvenassistent]";
CM_ SG_ 679 ACC_SpeedoScale "[DE: ACC_Tachokranz]";
CM_ SG_ 679 ACC_Type_SpeedoScale_Bottom "[DE: ACC_Typ_Tachokranz_unten]";
CM_ SG_ 681 AWV_Warning "[DE: AWV_Warnung]";
CM_ SG_ 681 AWV_Status_Display "[DE: AWV_Status_Anzeige]";
CM_ SG_ 681 AWV_OnPosition_System_FSG "[DE: AWV_Einstellung_System_FSG]";
CM_ SG_ 681 AWV_OnPosition_Warning_FSG "[DE: AWV_Einstellung_Warnung_FSG]";
CM_ SG_ 64 FROM_RGS_Anst "[DE: AB_RGS_Anst]";
CM_ SG_ 64 FROM_Front_Crash "[DE: AB_Front_Crash]";
CM_ SG_ 64 FROM_Rear_Crash "[DE: AB_Heck_Crash]";
CM_ SG_ 64 FROM_SF_Crash "[DE: AB_SF_Crash]";
CM_ SG_ 64 FROM_SB_Crash "[DE: AB_SB_Crash]";
CM_ SG_ 64 FROM_Rollover_Crash "[DE: AB_Rollover_Crash]";
CM_ SG_ 64 FROM_Crash_Int "[DE: AB_Crash_Int]";
CM_ SG_ 64 FROM_Lamp "[DE: AB_Lampe]";
CM_ SG_ 64 FROM_Deactivated "[DE: AB_Deaktiviert]";
CM_ SG_ 64 FROM_VB_Deactivated "[DE: AB_VB_deaktiviert]";
CM_ SG_ 64 FROM_SystemError "[DE: AB_Systemfehler]";
CM_ SG_ 64 FROM_Diagnostics "[DE: AB_Diagnose]";
CM_ SG_ 64 FROM_ActuatorTest "[DE: AB_Stellgliedtest]";
CM_ SG_ 64 FROM_Erh_Open_VB "[DE: AB_Erh_Auf_VB]";
CM_ SG_ 64 FROM_BeltWarn_VF "[DE: AB_Gurtwarn_VF]";
CM_ SG_ 64 FROM_BeltWarn_VB "[DE: AB_Gurtwarn_VB]";
CM_ SG_ 64 FROM_Display_Pedestrian "[DE: AB_Anzeige_Fussg]";
CM_ SG_ 64 FROM_Texte_AKS "[DE: AB_Texte_AKS]";
CM_ SG_ 64 FROM_PAO_Lamp_Req "[DE: AB_PAO_Leuchte_Anf]";
CM_ SG_ 64 FROM_MKB_Valid "[DE: AB_MKB_gueltig]";
CM_ SG_ 64 FROM_MKB_Request "[DE: AB_MKB_Anforderung]";
CM_ SG_ 64 FROM_SupplyVoltage "[DE: AB_Versorgungsspannung]";
CM_ SG_ 64 FROM_Deactivation_HV "[DE: AB_Deaktivierung_HV]";
CM_ SG_ 64 FROM_EDR_Trigger "[DE: AB_EDR_Trigger]";
CM_ SG_ 64 FROM_BeltWarn_HFS "[DE: AB_Gurtwarn_HFS]";
CM_ SG_ 64 FROM_BeltWarn_HBFS "[DE: AB_Gurtwarn_HBFS]";
CM_ SG_ 64 SC_MasterTime_Offset "[DE: SC_Masterzeit_Offset]";
CM_ SG_ 64 SC_MasterTime "[DE: SC_Masterzeit]";
CM_ SG_ 1312 FROM_Occupancy_VB "[DE: AB_Belegung_VB]";
CM_ SG_ 1312 FROM_BeltBuckle_FA "[DE: AB_Gurtschloss_FA]";
CM_ SG_ 1312 FROM_BeltBuckle_BF "[DE: AB_Gurtschloss_BF]";
CM_ SG_ 1312 FROM_BeltBuckle_Row2_FA "[DE: AB_Gurtschloss_Reihe2_FA]";
CM_ SG_ 1312 FROM_BeltBuckle_Row2_MI "[DE: AB_Gurtschloss_Reihe2_MI]";
CM_ SG_ 1312 FROM_BeltBuckle_Row2_BF "[DE: AB_Gurtschloss_Reihe2_BF]";
CM_ SG_ 1312 FROM_BeltBuckle_Row3_FA "[DE: AB_Gurtschloss_Reihe3_FA]";
CM_ SG_ 1312 FROM_BeltBuckle_Row3_MI "[DE: AB_Gurtschloss_Reihe3_MI]";
CM_ SG_ 1312 FROM_BeltBuckle_Row3_BF "[DE: AB_Gurtschloss_Reihe3_BF]";
CM_ SG_ 1312 FROM_SeatPos_Sens_FA "[DE: AB_Sitzpos_Sens_FA]";
CM_ SG_ 1312 FROM_SeatPos_Sens_BF "[DE: AB_Sitzpos_Sens_BF]";
CM_ SG_ 65 FROM_MKB_Safing "[DE: AB_MKB_Safing]";
CM_ SG_ 1633 AAG_BrakeLight_By_ECD "[DE: AAG_Bremsl_durch_ECD]";
CM_ SG_ 1633 AAG_Trailer_Unplugged "[DE: AAG_Anhaenger_abgesteckt]";
CM_ SG_ 1633 AAG_NSL_Active "[DE: AAG_NSL_aktiv]";
CM_ SG_ 1633 AAG_Trailer_Detected "[DE: AAG_Anhaenger_erkannt]";
CM_ SG_ 1633 AAG_Indicator_H_Active "[DE: AAG_Blinker_H_aktiv]";
CM_ SG_ 1633 AAG_Indicator_HL_def "[DE: AAG_Blinker_HL_def]";
CM_ SG_ 1633 AAG_Indicator_HR_def "[DE: AAG_Blinker_HR_def]";
CM_ SG_ 1633 AAG_BrakeLight_H_def "[DE: AAG_Bremslicht_H_def]";
CM_ SG_ 1633 AAG_TailLight_HL_def "[DE: AAG_Schlusslicht_HL_def]";
CM_ SG_ 1633 AAG_TailLight_HR_def "[DE: AAG_Schlusslicht_HR_def]";
CM_ SG_ 1633 AAG_AVS_Error_02 "[DE: AAG_AVS_Fehler_02]";
CM_ SG_ 1633 AAG_AVS_Statuses "[DE: AAG_AVS_Stati]";
CM_ SG_ 1626 BCM_BrakePad_Sensor "[DE: BCM_Bremsbelag_Sensor]";
CM_ SG_ 1626 BCM_BrakeFluid_Sensor "[DE: BCM_Bremsfluessigkeit_Sensor]";
CM_ SG_ 1626 BCM1_Light_Warn "[DE: BCM1_Licht_Warn]";
CM_ SG_ 1626 BCM_WasherFluid_Sensor "[DE: BCM_Waschwasser_Sensor]";
CM_ SG_ 1626 BCM_Coolant_Sensor "[DE: BCM_Kuehlmittel_Sensor]";
CM_ SG_ 1626 BCM1_Term_15_HW_Detected "[DE: BCM1_Kl_15_HW_erkannt]";
CM_ SG_ 1626 BCM_Eis_Offroad_Key "[DE: BCM_Eis_Offroad_Taste]";
CM_ SG_ 1626 ZZH_EndPosition_Top "[DE: ZZH_Endlage_oben]";
CM_ SG_ 1626 ZZH_EndPosition_Bottom "[DE: ZZH_Endlage_unten]";
CM_ SG_ 1626 ZZH_EndPosition_Implausible "[DE: ZZH_Endlage_unplausibel]";
CM_ SG_ 1626 BCM2_EZS_Pressed "[DE: BCM2_EZS_gedrueckt]";
CM_ SG_ 1626 BCM2_SST_Pressed "[DE: BCM2_SST_gedrueckt]";
CM_ SG_ 1626 BCM_Hybrid_StartStop_Key "[DE: BCM_Hybrid_StartStopp_Taste]";
CM_ SG_ 1626 BCM1_HazardFlash_PushButton "[DE: BCM1_Warnblink_Taster]";
CM_ SG_ 1626 BCM1_Valet_Parking_PushButton "[DE: BCM1_Valet_Parking_Taster]";
CM_ SG_ 1626 BCM_Remotestart_Operation "[DE: BCM_Remotestart_Betrieb]";
CM_ SG_ 1626 BCM1_HSK_PushButton "[DE: BCM1_HSK_Taster]";
CM_ SG_ 1626 BCM1_RearBlind_PushButton "[DE: BCM1_Heckrollo_Taster]";
CM_ SG_ 1626 BCM1_ReversingLight_Switch "[DE: BCM1_Rueckfahrlicht_Schalter]";
CM_ SG_ 1626 BCM1_MH_Switch "[DE: BCM1_MH_Schalter]";
CM_ SG_ 1626 BCM1_MH_WIV_Switch "[DE: BCM1_MH_WIV_Schalter]";
CM_ SG_ 1626 BCM_Eco_Charisma_Key "[DE: BCM_Eco_Charisma_Taste]";
CM_ SG_ 1626 BCM_ThermalManagement "[DE: BCM_Thermomanagement]";
CM_ SG_ 1626 BCM_ThermalManagement_Error "[DE: BCM_Thermomanagement_Fehler]";
CM_ SG_ 1626 BCM_ThermalManagement_Valid "[DE: BCM_Thermomanagement_gueltig]";
CM_ SG_ 1626 BCM1_LightWarn_Texte "[DE: BCM1_Lichtwarn_Texte]";
CM_ SG_ 869 BEM_P_Alternator "[DE: BEM_P_Generator]";
CM_ SG_ 869 BEM_01_ShutoffStages "[DE: BEM_01_Abschaltstufen]";
CM_ SG_ 869 BEM_Req_TERM "[DE: BEM_Anf_KL]";
CM_ SG_ 869 BEM_StartStop_Info "[DE: BEM_StartStopp_Info]";
CM_ SG_ 869 BEM_EMLIN_Invalid "[DE: BEM_EMLIN_ungueltig]";
CM_ SG_ 869 BEM_Batt_From "[DE: BEM_Batt_Ab]";
CM_ SG_ 869 BEM_Coast_Info "[DE: BEM_Segel_Info]";
CM_ SG_ 869 BEM_HYB_DC_uTargetLV "[DE: BEM_HYB_DC_uSollLV]";
CM_ SG_ 1628 BMS_HYB_ASV_Rear_Status "[DE: BMS_HYB_ASV_hinten_Status]";
CM_ SG_ 1628 BMS_HYB_ASV_Front_Status "[DE: BMS_HYB_ASV_vorne_Status]";
CM_ SG_ 1628 BMS_HYB_KD_Error "[DE: BMS_HYB_KD_Fehler]";
CM_ SG_ 1628 BMS_HYB_Flushing_Status "[DE: BMS_HYB_Spuelbetrieb_Status]";
CM_ SG_ 1628 BMS_HYB_Cooling_Req "[DE: BMS_HYB_Kuehlung_Anf]";
CM_ SG_ 1628 BMS_HYB_Temp_Before_Verd "[DE: BMS_HYB_Temp_vor_Verd]";
CM_ SG_ 1628 BMS_HYB_Temp_After_Verd "[DE: BMS_HYB_Temp_nach_Verd]";
CM_ SG_ 1628 BMS_Temperature "[DE: BMS_Temperatur]";
CM_ SG_ 1628 BMS_Temperature_IntakeAir "[DE: BMS_Temperatur_Ansaugluft]";
CM_ SG_ 1628 BMS_ActualVoltage_HV "[DE: BMS_IstSpannung_HV]";
CM_ SG_ 901 CHA_Target_DrivePr_ALR "[DE: CHA_Ziel_FahrPr_ALR]";
CM_ SG_ 901 CHA_Target_DrivePr_ESP "[DE: CHA_Ziel_FahrPr_ESP]";
CM_ SG_ 901 CHA_Target_DrivePr_FL "[DE: CHA_Ziel_FahrPr_FL]";
CM_ SG_ 901 CHA_Driver_Changeover "[DE: CHA_Fahrer_Umschaltung]";
CM_ SG_ 901 CHA_Target_DrivePr_MO "[DE: CHA_Ziel_FahrPr_MO]";
CM_ SG_ 901 CHA_Target_DrivePr_GE "[DE: CHA_Ziel_FahrPr_GE]";
CM_ SG_ 901 CHA_Target_DrivePr_ST "[DE: CHA_Ziel_FahrPr_ST]";
CM_ SG_ 901 CHA_Target_DrivePr_SCU "[DE: CHA_Ziel_FahrPr_SCU]";
CM_ SG_ 901 CHA_Target_DrivePr_DR "[DE: CHA_Ziel_FahrPr_DR]";
CM_ SG_ 901 CHA_Target_DrivePr_QS "[DE: CHA_Ziel_FahrPr_QS]";
CM_ SG_ 901 CHA_Target_DrivePr_AFS "[DE: CHA_Ziel_FahrPr_AFS]";
CM_ SG_ 901 CHA_Target_DrivePr_RGS "[DE: CHA_Ziel_FahrPr_RGS]";
CM_ SG_ 901 CHA_Target_DrivePr_EPS "[DE: CHA_Ziel_FahrPr_EPS]";
CM_ SG_ 901 CHA_Target_DrivePr_ACC "[DE: CHA_Ziel_FahrPr_ACC]";
CM_ SG_ 901 CHA_Target_DrivePr_SAK "[DE: CHA_Ziel_FahrPr_SAK]";
CM_ SG_ 901 CHA_Target_DrivePr_MStSt "[DE: CHA_Ziel_FahrPr_MStSt]";
CM_ SG_ 945 DC_HYB_iActLV "[DE: DC_HYB_iAktLV]";
CM_ SG_ 945 DC_HYB_iActReserveLV "[DE: DC_HYB_iAktReserveLV]";
CM_ SG_ 945 DC_HYB_uActLV "[DE: DC_HYB_uAktLV]";
CM_ SG_ 945 DC_HYB_LangsControl "[DE: DC_HYB_LangsRegelung]";
CM_ SG_ 945 DC_HYB_Limiting_Temperature "[DE: DC_HYB_Abregelung_Temperatur]";
CM_ SG_ 945 DC_HYB_Error_RedPower "[DE: DC_HYB_Fehler_RedLeistung]";
CM_ SG_ 945 DC_HYB_Error_Internal "[DE: DC_HYB_Fehler_intern]";
CM_ SG_ 945 DC_HYB_Error_Voltage "[DE: DC_HYB_Fehler_Spannung]";
CM_ SG_ 1714 DGN_UnlearnCounter "[DE: DGN_Verlernzaehler]";
CM_ SG_ 1714 KBI_Odometer "[DE: KBI_Kilometerstand]";
CM_ SG_ 1714 UH_Year "[DE: UH_Jahr]";
CM_ SG_ 1714 UH_Month "[DE: UH_Monat]";
CM_ SG_ 1714 UH_Hour "[DE: UH_Stunde]";
CM_ SG_ 1714 UH_Second "[DE: UH_Sekunde]";
CM_ SG_ 1714 Cluster_02_Old "[DE: Kombi_02_alt]";
CM_ SG_ 1714 ClockTime_01_Old "[DE: Uhrzeit_01_alt]";
CM_ SG_ 1520 DI_TERM_58xd "[DE: DI_KL_58xd]";
CM_ SG_ 1520 DI_TERM_58xs "[DE: DI_KL_58xs]";
CM_ SG_ 1520 DI_Display_NightDesign "[DE: DI_Display_Nachtdesign]";
CM_ SG_ 1520 DI_TERM_58xt "[DE: DI_KL_58xt]";
CM_ SG_ 1520 DI_PhotoSensor "[DE: DI_Fotosensor]";
CM_ SG_ 1603 KBI_Unit_Date "[DE: KBI_Einheit_Datum]";
CM_ SG_ 1603 KBI_Unit_Pressure "[DE: KBI_Einheit_Druck]";
CM_ SG_ 1603 KBI_Unit_Streckenanz "[DE: KBI_Einheit_Streckenanz]";
CM_ SG_ 1603 KBI_MFA_v_Unit_02 "[DE: KBI_MFA_v_Einheit_02]";
CM_ SG_ 1603 KBI_Unit_Temp "[DE: KBI_Einheit_Temp]";
CM_ SG_ 1603 KBI_Unit_ClockTime "[DE: KBI_Einheit_Uhrzeit]";
CM_ SG_ 1603 KBI_Unit_Consumption "[DE: KBI_Einheit_Verbrauch]";
CM_ SG_ 1603 KBI_Unit_Volume "[DE: KBI_Einheit_Volumen]";
CM_ SG_ 1603 KBI_Unit_Language "[DE: KBI_Einheit_Sprache]";
CM_ SG_ 260 EPB_QBit_LongAccel "[DE: EPB_QBit_Laengsbeschleunigung]";
CM_ SG_ 260 EPB_QBit_PedalTravel_Clutch "[DE: EPB_QBit_Pedalweg_Kuppl]";
CM_ SG_ 260 EPB_BCM2_Engine_Wakeup "[DE: EPB_BCM2_Motor_Wakeup]";
CM_ SG_ 260 EPB_Enable_Decel_Req "[DE: EPB_Freig_Verzoeg_Anf]";
CM_ SG_ 260 EPB_Decel_Req "[DE: EPB_Verzoeg_Anf]";
CM_ SG_ 260 EPB_LongAccel "[DE: EPB_Laengsbeschleunigung]";
CM_ SG_ 260 EPB_PedalTravel_Clutch "[DE: EPB_Pedalweg_Kuppl]";
CM_ SG_ 260 EPB_PullAwayRequest_Detected "[DE: EPB_Anfahrwunsch_erkannt]";
CM_ SG_ 260 EPB_DAA_BoundaryCond_erf "[DE: EPB_DAA_Randbed_erf]";
CM_ SG_ 260 EPB_ErrorStatus "[DE: EPB_Fehlerstatus]";
CM_ SG_ 260 EPB_Consistency_ACC "[DE: EPB_Konsistenz_ACC]";
CM_ SG_ 260 EPB_ClampForce "[DE: EPB_Spannkraft]";
CM_ SG_ 257 ESP_QBit_YawRate "[DE: ESP_QBit_Gierrate]";
CM_ SG_ 257 ESP_QBit_LongAccel "[DE: ESP_QBit_Laengsbeschl]";
CM_ SG_ 257 ESP_QBit_LatAccel "[DE: ESP_QBit_Querb]";
CM_ SG_ 257 ESP_LateralAccel "[DE: ESP_Querbeschleunigung]";
CM_ SG_ 257 ESP_LongAccel "[DE: ESP_Laengsbeschl]";
CM_ SG_ 257 ESP_Verteil_RollTorque "[DE: ESP_Verteil_Wankmom]";
CM_ SG_ 257 ESP_QBit_Req_Vert_Roll "[DE: ESP_QBit_Anf_Vert_Wank]";
CM_ SG_ 257 ESP_YawRate "[DE: ESP_Gierrate]";
CM_ SG_ 257 ESP_VZ_YawRate "[DE: ESP_VZ_Gierrate]";
CM_ SG_ 257 ESP_VoltageReq "[DE: ESP_SpannungsAnf]";
CM_ SG_ 257 ESP_PLA_Abort "[DE: ESP_PLA_Abbruch]";
CM_ SG_ 262 ESP_QBit_BrakePressure "[DE: ESP_QBit_Bremsdruck]";
CM_ SG_ 262 ESP_QBit_Driver_Brakes "[DE: ESP_QBit_Fahrer_bremst]";
CM_ SG_ 262 ESP_Threshold_Vacuum "[DE: ESP_Schwelle_Unterdruck]";
CM_ SG_ 262 ESP_BrakePressure "[DE: ESP_Bremsdruck]";
CM_ SG_ 262 ESP_Driver_Brakes "[DE: ESP_Fahrer_bremst]";
CM_ SG_ 262 ESP_Decel_TSK_Active "[DE: ESP_Verz_TSK_aktiv]";
CM_ SG_ 262 ESP_SteeringIntervention_ADS "[DE: ESP_Lenkeingriff_ADS]";
CM_ SG_ 262 ESP_Consistency_TSK "[DE: ESP_Konsistenz_TSK]";
CM_ SG_ 262 ESP_BrakeJerk_AWV2 "[DE: ESP_Bremsruck_AWV2]";
CM_ SG_ 262 ESP_Consistency_AWV2 "[DE: ESP_Konsistenz_AWV2]";
CM_ SG_ 262 ECD_Error "[DE: ECD_Fehler]";
CM_ SG_ 262 ECD_Not_Available "[DE: ECD_nicht_verfuegbar]";
CM_ SG_ 262 ESP_Status_BrakesTemp "[DE: ESP_Status_Bremsentemp]";
CM_ SG_ 262 ESP_AutoHold_Standby "[DE: ESP_Autohold_Standby]";
CM_ SG_ 262 ESP_HBA_Active "[DE: ESP_HBA_aktiv]";
CM_ SG_ 262 ESP_Prefill_Triggered "[DE: ESP_Prefill_ausgeloest]";
CM_ SG_ 262 ESP_Reversing_Detected "[DE: ESP_Rueckwaertsfahrt_erkannt]";
CM_ SG_ 262 ESP_Status_HillStartAssist "[DE: ESP_Status_Anfahrhilfe]";
CM_ SG_ 262 ESP_HDC_Active "[DE: ESP_HDC_aktiv]";
CM_ SG_ 262 ESP_StartStop_Info "[DE: ESP_StartStopp_Info]";
CM_ SG_ 262 ESP_Interv_HL "[DE: ESP_Eingr_HL]";
CM_ SG_ 262 ESP_Interv_HR "[DE: ESP_Eingr_HR]";
CM_ SG_ 262 ESP_Interv_VL "[DE: ESP_Eingr_VL]";
CM_ SG_ 262 ESP_Interv_VR "[DE: ESP_Eingr_VR]";
CM_ SG_ 262 ESP_BKV_Vacuum "[DE: ESP_BKV_Unterdruck]";
CM_ SG_ 262 ESP_AutoHold_Active "[DE: ESP_Autohold_aktiv]";
CM_ SG_ 262 ESP_FStatus_HillStartAssist "[DE: ESP_FStatus_Anfahrhilfe]";
CM_ SG_ 262 ESP_Decel_EPB_Active "[DE: ESP_Verz_EPB_aktiv]";
CM_ SG_ 262 ECD_BrakeLight "[DE: ECD_Bremslicht]";
CM_ SG_ 262 ESP_Decel_EPB_Avail "[DE: ESP_Verzoeg_EPB_verf]";
CM_ SG_ 262 ESP_Status_BrakePressure "[DE: ESP_Status_Bremsdruck]";
CM_ SG_ 262 ESP_Request_EPB "[DE: ESP_Anforderung_EPB]";
CM_ SG_ 914 ESP_Quattro_Drive "[DE: ESP_Quattro_Antrieb]";
CM_ SG_ 914 ESP_Coding_ADS "[DE: ESP_Codierung_ADS]";
CM_ SG_ 914 OBD_Error_WheelSensor_HL "[DE: OBD_Fehler_Radsensor_HL]";
CM_ SG_ 914 OBD_Error_WheelSensor_HR "[DE: OBD_Fehler_Radsensor_HR]";
CM_ SG_ 914 OBD_Error_WheelSensor_VL "[DE: OBD_Fehler_Radsensor_VL]";
CM_ SG_ 914 OBD_Error_WheelSensor_VR "[DE: OBD_Fehler_Radsensor_VR]";
CM_ SG_ 914 ESP_Qualification_DriveType "[DE: ESP_Qualifizierung_Antriebsart]";
CM_ SG_ 914 ESP_Offroad_Mode "[DE: ESP_Offroad_Modus]";
CM_ SG_ 914 ESP_CM_Variant "[DE: ESP_CM_Variante]";
CM_ SG_ 278 ESP_QBit_DistancePulse_VL "[DE: ESP_QBit_Wegimpuls_VL]";
CM_ SG_ 278 ESP_QBit_DistancePulse_VR "[DE: ESP_QBit_Wegimpuls_VR]";
CM_ SG_ 278 ESP_QBit_DistancePulse_HL "[DE: ESP_QBit_Wegimpuls_HL]";
CM_ SG_ 278 ESP_QBit_DistancePulse_HR "[DE: ESP_QBit_Wegimpuls_HR]";
CM_ SG_ 278 ESP_DistancePulse_VL "[DE: ESP_Wegimpuls_VL]";
CM_ SG_ 278 ESP_DistancePulse_VR "[DE: ESP_Wegimpuls_VR]";
CM_ SG_ 278 ESP_DistancePulse_HL "[DE: ESP_Wegimpuls_HL]";
CM_ SG_ 278 ESP_DistancePulse_HR "[DE: ESP_Wegimpuls_HR]";
CM_ SG_ 278 ESP_VL_Direction "[DE: ESP_VL_Fahrtrichtung]";
CM_ SG_ 278 ESP_VR_Direction "[DE: ESP_VR_Fahrtrichtung]";
CM_ SG_ 278 ESP_HL_Direction "[DE: ESP_HL_Fahrtrichtung]";
CM_ SG_ 278 ESP_HR_Direction "[DE: ESP_HR_Fahrtrichtung]";
CM_ SG_ 178 ESP_HL_WheelSpeed_02 "[DE: ESP_HL_Radgeschw_02]";
CM_ SG_ 178 ESP_HR_WheelSpeed_02 "[DE: ESP_HR_Radgeschw_02]";
CM_ SG_ 178 ESP_VL_WheelSpeed_02 "[DE: ESP_VL_Radgeschw_02]";
CM_ SG_ 178 ESP_VR_WheelSpeed_02 "[DE: ESP_VR_Radgeschw_02]";
CM_ SG_ 1629 BR_SystemType "[DE: BR_Systemart]";
CM_ SG_ 1629 ESP_VoltageReq_02 "[DE: ESP_SpannungsAnf_02]";
CM_ SG_ 1629 ESP_ToothCount "[DE: ESP_Zaehnezahl]";
CM_ SG_ 1629 ESP_Charisma_DrivePr "[DE: ESP_Charisma_FahrPr]";
CM_ SG_ 1629 ESP_Restart_Disp_01 "[DE: ESP_Wiederstart_Anz_01]";
CM_ SG_ 1629 ESP_Restart_Disp_02 "[DE: ESP_Wiederstart_Anz_02]";
CM_ SG_ 1629 ESP_Restart_Disp_03 "[DE: ESP_Wiederstart_Anz_03]";
CM_ SG_ 1629 ESP_Restart_Disp_04 "[DE: ESP_Wiederstart_Anz_04]";
CM_ SG_ 1629 ESP_StopInhibit_Disp_01 "[DE: ESP_Stoppverbot_Anz_01]";
CM_ SG_ 1629 ESP_StopInhibit_Disp_02 "[DE: ESP_Stoppverbot_Anz_02]";
CM_ SG_ 1629 ESP_StopInhibit_Disp_03 "[DE: ESP_Stoppverbot_Anz_03]";
CM_ SG_ 1629 ESP_StopInhibit_Disp_04 "[DE: ESP_Stoppverbot_Anz_04]";
CM_ SG_ 1629 ESP_StopInhibit_Disp_05 "[DE: ESP_Stoppverbot_Anz_05]";
CM_ SG_ 1629 ESP_StopInhibit_Disp_06 "[DE: ESP_Stoppverbot_Anz_06]";
CM_ SG_ 1629 ESP_StopInhibit_Disp_07 "[DE: ESP_Stoppverbot_Anz_07]";
CM_ SG_ 1629 ESP_StopInhibit_Disp_Std "[DE: ESP_Stoppverbot_Anz_Std]";
CM_ SG_ 1629 ESP_StopInhibit_Disp_08 "[DE: ESP_Stoppverbot_Anz_08]";
CM_ SG_ 1629 HDC_Charisma_DrivePr "[DE: HDC_Charisma_FahrPr]";
CM_ SG_ 1629 BR_QBit_TyreCircumference "[DE: BR_QBit_Reifenumfang]";
CM_ SG_ 1629 BR_TyreCircumference "[DE: BR_Reifenumfang]";
CM_ SG_ 253 BR_InterventionTorque "[DE: BR_Eingriffsmoment]";
CM_ SG_ 253 ESP_PLA_BrakeIntervention "[DE: ESP_PLA_Bremseingriff]";
CM_ SG_ 253 ESP_Diagnostics "[DE: ESP_Diagnose]";
CM_ SG_ 253 ESC_Recup_Enable "[DE: ESC_Reku_Freigabe]";
CM_ SG_ 253 ESP_BeforeControl "[DE: ESP_Vorsteuerung]";
CM_ SG_ 253 ESP_AWV3_Brake_Active "[DE: ESP_AWV3_Brems_aktiv]";
CM_ SG_ 253 OBD_RoughRoad "[DE: OBD_Schlechtweg]";
CM_ SG_ 253 OBD_QBit_RoughRoad "[DE: OBD_QBit_Schlechtweg]";
CM_ SG_ 253 ASR_Keying_Passive "[DE: ASR_Tastung_passiv]";
CM_ SG_ 253 ESP_Keying_Passive "[DE: ESP_Tastung_passiv]";
CM_ SG_ 253 ESP_SystemStatus "[DE: ESP_Systemstatus]";
CM_ SG_ 253 ASR_ShiftIntervention "[DE: ASR_Schalteingriff]";
CM_ SG_ 253 ESP_MKB_Abort_Speed "[DE: ESP_MKB_Abbruch_Geschw]";
CM_ SG_ 253 ABS_Braking "[DE: ABS_Bremsung]";
CM_ SG_ 253 ASR_Req "[DE: ASR_Anf]";
CM_ SG_ 253 MSR_Req "[DE: MSR_Anf]";
CM_ SG_ 253 EBV_Intervention "[DE: EBV_Eingriff]";
CM_ SG_ 253 EDS_Intervention "[DE: EDS_Eingriff]";
CM_ SG_ 253 ESP_Intervention "[DE: ESP_Eingriff]";
CM_ SG_ 253 ESP_TrailerOldBeforeGear_ACC_Active "[DE: ESP_Anhaltevorgang_ACC_aktiv]";
CM_ SG_ 987 BCM_01_Old "[DE: BCM_01_alt]";
CM_ SG_ 987 SMLS_01_Old "[DE: SMLS_01_alt]";
CM_ SG_ 987 ZV_02_Old "[DE: ZV_02_alt]";
CM_ SG_ 987 Wiper_01_Old "[DE: Wischer_01_alt]";
CM_ SG_ 987 Trailer_01_Old "[DE: Anhaenger_01_alt]";
CM_ SG_ 987 Climate_Sensor_02_Old "[DE: Klima_Sensor_02_alt]";
CM_ SG_ 987 VSG_01_Old "[DE: VSG_01_alt]";
CM_ SG_ 987 Climate_01_Old "[DE: Klima_01_alt]";
CM_ SG_ 987 WFS_01_Old "[DE: WFS_01_alt]";
CM_ SG_ 987 Light_Req_01_Old "[DE: Licht_Anf_01_alt]";
CM_ SG_ 987 ZV_HFS_Open "[DE: ZV_HFS_offen]";
CM_ SG_ 987 ZV_HBFS_Open "[DE: ZV_HBFS_offen]";
CM_ SG_ 987 VS_VD_Open_ver "[DE: VS_VD_offen_ver]";
CM_ SG_ 987 VS_VD_Closed_ver "[DE: VS_VD_zu_ver]";
CM_ SG_ 987 ZV_BT_Open "[DE: ZV_BT_offen]";
CM_ SG_ 987 BCM1_ReversingLight_Switch "[DE: BCM1_Rueckfahrlicht_Schalter]";
CM_ SG_ 987 ZV_FT_Open "[DE: ZV_FT_offen]";
CM_ SG_ 987 Wiper_Front_Active "[DE: Wischer_vorne_aktiv]";
CM_ SG_ 987 AAG_Trailer_Detected "[DE: AAG_Anhaenger_erkannt]";
CM_ SG_ 987 BCM1_MH_Switch "[DE: BCM1_MH_Schalter]";
CM_ SG_ 987 ZV_HD_Open "[DE: ZV_HD_offen]";
CM_ SG_ 987 Wash_Front_Active "[DE: Waschen_vorne_aktiv]";
CM_ SG_ 987 TERM_ThermalManagement "[DE: KL_Thermomanagement]";
CM_ SG_ 987 WFS_Key_DriveAuthorisation "[DE: WFS_Schluessel_Fahrberecht]";
CM_ SG_ 987 BCM1_RHeadlights_Veh_Req "[DE: BCM1_RFahrlicht_Fzg_Anf]";
CM_ SG_ 987 BCM1_RHeadlights_Ahg_Req "[DE: BCM1_RFahrlicht_Ahg_Anf]";
CM_ SG_ 987 BH_HighBeam "[DE: BH_Fernlicht]";
CM_ SG_ 987 BH_Indicator_Left "[DE: BH_Blinker_li]";
CM_ SG_ 987 BH_Indicator_Right "[DE: BH_Blinker_re]";
CM_ SG_ 987 BCM1_Outside_Temp_Unfilt "[DE: BCM1_Aussen_Temp_ungef]";
CM_ SG_ 989 LH_EPS_01_Old "[DE: LH_EPS_01_alt]";
CM_ SG_ 989 Kessy_04_Old "[DE: Kessy_04_alt]";
CM_ SG_ 989 LIN_2_Old "[DE: LIN_2_alt]";
CM_ SG_ 989 MFG_01_Old "[DE: MFG_01_alt]";
CM_ SG_ 989 Climate_02_Old "[DE: Klima_02_alt]";
CM_ SG_ 989 ParkAssist_01_Old "[DE: Parkhilfe_01_alt]";
CM_ SG_ 989 ELV_01_Old "[DE: ELV_01_alt]";
CM_ SG_ 989 KY_StartStop_Info "[DE: KY_StartStopp_Info]";
CM_ SG_ 989 PH_StartStop_Info "[DE: PH_StartStopp_Info]";
CM_ SG_ 989 EPS_HandlebarPosition "[DE: EPS_Lenkerposition]";
CM_ SG_ 989 ELV_Req_Terminal_50 "[DE: ELV_Anf_Klemme_50]";
CM_ SG_ 989 MF_StartStop_Info "[DE: MF_StartStopp_Info]";
CM_ SG_ 989 TERM_BlowerVoltage_Target "[DE: KL_Geblaesespannung_Soll]";
CM_ SG_ 989 TERM_RecirculationFlap_Status "[DE: KL_Umluftklappe_Status]";
CM_ SG_ 989 LS_Tiptronic_Error "[DE: LS_Tiptronic_Fehler]";
CM_ SG_ 296 GE_WH_Lock "[DE: GE_WH_Sperre]";
CM_ SG_ 296 GE_Test_Enable "[DE: GE_Test_Freigabe]";
CM_ SG_ 296 GE_Actual_DriveRange "[DE: GE_Ist_Fahrstufe]";
CM_ SG_ 296 GE_TestParameter_1 "[DE: GE_Testparameter_1]";
CM_ SG_ 296 GE_TestParameter_2 "[DE: GE_Testparameter_2]";
CM_ SG_ 173 GE_MTorque_Target_02 "[DE: GE_MMom_Soll_02]";
CM_ SG_ 173 GE_MTorque_Lead_02 "[DE: GE_MMom_Vorhalt_02]";
CM_ SG_ 173 GE_DriveRange "[DE: GE_Fahrstufe]";
CM_ SG_ 173 GE_Reserved_DriveRange "[DE: GE_reserv_Fahrstufe]";
CM_ SG_ 173 GE_ShiftSequence "[DE: GE_Schaltablauf]";
CM_ SG_ 173 GE_Uefkt_Implausible "[DE: GE_Uefkt_unplausibel]";
CM_ SG_ 173 GE_MTorque_Status_02 "[DE: GE_MMom_Status_02]";
CM_ SG_ 173 GE_Status_Traction "[DE: GE_Status_Kraftschluss]";
CM_ SG_ 173 GE_MTorque_Status "[DE: GE_MMom_Status]";
CM_ SG_ 173 GE_Enable_MTorque_Lead "[DE: GE_Freig_MMom_Vorhalt]";
CM_ SG_ 173 GE_Inhibit_Suppression "[DE: GE_Verbot_Ausblendung]";
CM_ SG_ 173 GE_TargetGear "[DE: GE_Zielgang]";
CM_ SG_ 174 Gearbox_12_CRC "[DE: Getriebe_12_CRC]";
CM_ SG_ 174 Gearbox_12_BZ "[DE: Getriebe_12_BZ]";
CM_ SG_ 174 GE_Tachometer_Damping "[DE: GE_Drehzahlmesser_Daempfung]";
CM_ SG_ 174 GE_OverrunCut_Unt "[DE: GE_Schubabschalt_Unt]";
CM_ SG_ 174 GE_Enable_Synchro "[DE: GE_Freigabe_Synchro]";
CM_ SG_ 174 GE_Synchro_RequestedRpm "[DE: GE_Synchro_Wunschdrehz]";
CM_ SG_ 174 GE_Synchro_Time "[DE: GE_Synchro_Zeit]";
CM_ SG_ 174 GE_Torque_Limit_Gradient "[DE: GE_Mom_Begr_Gradient]";
CM_ SG_ 174 GE_Anheb_TargetRpm_Idle "[DE: GE_Anheb_Solldrehz_Leerlauf]";
CM_ SG_ 174 GE_Req_CylDeact "[DE: GE_Anf_Zylabsch]";
CM_ SG_ 174 GE_HYB_RPM_Intervention "[DE: GE_HYB_DZ_Eingriff]";
CM_ SG_ 301 Gearbox_13_CRC "[DE: Getriebe_13_CRC]";
CM_ SG_ 301 Gearbox_13_BZ "[DE: Getriebe_13_BZ]";
CM_ SG_ 301 GE_StartStop_Info "[DE: GE_StartStopp_Info]";
CM_ SG_ 301 GE_Langfr_ProtectionTorque_02 "[DE: GE_Langfr_Schutzmom_02]";
CM_ SG_ 301 GE_InputSpeed "[DE: GE_Eingangsdrehz]";
CM_ SG_ 301 GE_LimpHome "[DE: GE_Notlauf]";
CM_ SG_ 301 GE_Enable_Langfr_ProtectionTorque "[DE: GE_Freig_Langfr_Schutzmom]";
CM_ SG_ 968 GE_OBD_AbsperrValve "[DE: GE_OBD_AbsperrVent]";
CM_ SG_ 968 GE_amax_Possible "[DE: GE_amax_moeglich]";
CM_ SG_ 968 GE_Charisma_DrivePr "[DE: GE_Charisma_FahrPr]";
CM_ SG_ 968 GE_LossTorque "[DE: GE_Verlustmoment]";
CM_ SG_ 968 GE_Enable_ExpiryInfo_WFS "[DE: GE_Freigabe_Verfallsinfo_WFS]";
CM_ SG_ 968 GE_Coding_MSG "[DE: GE_Codierung_MSG]";
CM_ SG_ 968 GE_HeatRequest "[DE: GE_Heizwunsch]";
CM_ SG_ 968 GE_LFR_Adaptation "[DE: GE_LFR_Adaption]";
CM_ SG_ 968 GE_SumpTemperature "[DE: GE_Sumpftemperatur]";
CM_ SG_ 158 Gearbox_Hybrid_01_CRC "[DE: Getriebe_Hybrid_01_CRC]";
CM_ SG_ 158 Gearbox_Hybrid_01_BZ "[DE: Getriebe_Hybrid_01_BZ]";
CM_ SG_ 158 GE_HYB_ErrorStatus "[DE: GE_HYB_Fehlerstatus]";
CM_ SG_ 158 GE_HYB_Enable_K0 "[DE: GE_HYB_Freigabe_K0]";
CM_ SG_ 158 GE_HYB_Enable_LL_Reg "[DE: GE_HYB_Freigabe_LL_Reg]";
CM_ SG_ 158 GE_HYB_Enable_sSchl_K0 "[DE: GE_HYB_Freig_sSchl_K0]";
CM_ SG_ 158 GE_HYB_Enable_VM_EM_Stop "[DE: GE_HYB_Freig_VM_EM_Stop]";
CM_ SG_ 158 GE_HYB_Restart "[DE: GE_HYB_Wiederstart]";
CM_ SG_ 158 GE_HYB_Filt_TorqueAufbau "[DE: GE_HYB_Filt_MomAufbau]";
CM_ SG_ 158 GE_HYB_TorqueIntervention_EM "[DE: GE_HYB_MomEingriff_EM]";
CM_ SG_ 158 GE_HYB_VZ_TorqueIntervention_EM "[DE: GE_HYB_VZ_MomEingriff_EM]";
CM_ SG_ 158 GE_HYB_VM_Act_Hold "[DE: GE_HYB_VM_akt_halten]";
CM_ SG_ 158 GE_HYB_StartReq "[DE: GE_HYB_StartAnf]";
CM_ SG_ 299 GRA_MainSwitch "[DE: GRA_Hauptschalter]";
CM_ SG_ 299 GRA_Cancel "[DE: GRA_Abbrechen]";
CM_ SG_ 299 GRA_Type_MainSwitch "[DE: GRA_Typ_Hauptschalter]";
CM_ SG_ 299 GRA_Tip_Set "[DE: GRA_Tip_Setzen]";
CM_ SG_ 299 GRA_Tip_High "[DE: GRA_Tip_Hoch]";
CM_ SG_ 299 GRA_Tip_Down "[DE: GRA_Tip_Runter]";
CM_ SG_ 299 GRA_Tip_Resume "[DE: GRA_Tip_Wiederaufnahme]";
CM_ SG_ 299 GRA_Adjustment_TimeGap "[DE: GRA_Verstellung_Zeitluecke]";
CM_ SG_ 299 GRA_Coding "[DE: GRA_Codierung]";
CM_ SG_ 299 GRA_Error "[DE: GRA_Fehler]";
CM_ SG_ 299 GRA_Type468 "[DE: GRA_Typ468]";
CM_ SG_ 299 GRA_Tip_Stage_2 "[DE: GRA_Tip_Stufe_2]";
CM_ SG_ 960 ZAS_Term_S "[DE: ZAS_Kl_S]";
CM_ SG_ 960 ZAS_Term_X "[DE: ZAS_Kl_X]";
CM_ SG_ 960 ZAS_Term_50 "[DE: ZAS_Kl_50]";
CM_ SG_ 949 TERM_Rpm_Trailer "[DE: KL_Drehz_Anh]";
CM_ SG_ 949 TERM_PreWarn_Compressor_On "[DE: KL_Vorwarn_Komp_ein]";
CM_ SG_ 949 TERM_AC_Switch "[DE: KL_AC_Schalter]";
CM_ SG_ 949 TERM_Compressor_Torque_Old "[DE: KL_Komp_Moment_alt]";
CM_ SG_ 949 TERM_Zones "[DE: KL_Zonen]";
CM_ SG_ 949 TERM_PreWarn_AuxHeater_On "[DE: KL_Vorwarn_Zuheizer_ein]";
CM_ SG_ 949 TERM_State "[DE: KL_Zustand]";
CM_ SG_ 949 TERM_Comp_rev_rq "[DE: KL_Comp_rev_rq]";
CM_ SG_ 949 TERM_Charisma_DrivePr "[DE: KL_Charisma_FahrPr]";
CM_ SG_ 949 TERM_Charisma_Status "[DE: KL_Charisma_Status]";
CM_ SG_ 949 TERM_Comp_enable "[DE: KL_Comp_enable]";
CM_ SG_ 949 TERM_Load_Compressor "[DE: KL_Last_Kompr]";
CM_ SG_ 949 TERM_Voltage_Req "[DE: KL_Spannungs_Anf]";
CM_ SG_ 949 TERM_ThermalManagement "[DE: KL_Thermomanagement]";
CM_ SG_ 949 TERM_StartStop_Info "[DE: KL_StartStopp_Info]";
CM_ SG_ 949 TERM_Req_TERM "[DE: KL_Anf_KL]";
CM_ SG_ 949 TERM_el_AuxHeater_Stage "[DE: KL_el_Zuheizer_Stufe]";
CM_ SG_ 1625 EKL_KD_Error "[DE: EKL_KD_Fehler]";
CM_ SG_ 1625 EKL_Comp_SCI_com_Status "[DE: EKL_Comp_SCI_com_stat]";
CM_ SG_ 1625 EKL_Comp_output_Status "[DE: EKL_Comp_output_stat]";
CM_ SG_ 1625 EKL_Comp_main_Status "[DE: EKL_Comp_main_stat]";
CM_ SG_ 1625 EKL_Comp_ovld_Status "[DE: EKL_Comp_ovld_stat]";
CM_ SG_ 1625 EKL_Comp_Inv_Status "[DE: EKL_Comp_Inv_stat]";
CM_ SG_ 1625 EKL_Comp_photo_temp_Status "[DE: EKL_Comp_photo_temp_stat]";
CM_ SG_ 1625 EKL_Comp_rev_Status "[DE: EKL_Comp_rev_stat]";
CM_ SG_ 2549088277 Airbag_01_CompressorProtection "[DE: Airbag_01_KompSchutz]";
CM_ SG_ 2549088277 Airbag_01_RunOnType "[DE: Airbag_01_Nachlauftyp]";
CM_ SG_ 2549088277 FROM_KD_Error "[DE: AB_KD_Fehler]";
CM_ SG_ 2549088380 EEngine_CompressorProtection "[DE: EMotor_KompSchutz]";
CM_ SG_ 2549088380 EEngine_RunOnType "[DE: EMotor_Nachlauftyp]";
CM_ SG_ 2549088380 EM_HYB_KD_Error "[DE: EM_HYB_KD_Fehler]";
CM_ SG_ 2549088375 Gearbox_CompressorProtection "[DE: Getriebe_KompSchutz]";
CM_ SG_ 2549088375 Gearbox_RunOnType "[DE: Getriebe_Nachlauftyp]";
CM_ SG_ 2549088375 GE_KD_Error "[DE: GE_KD_Fehler]";
CM_ SG_ 2549088379 Hybrid_CompressorProtection "[DE: Hybrid_KompSchutz]";
CM_ SG_ 2549088379 Hybrid_RunOnType "[DE: Hybrid_Nachlauftyp]";
CM_ SG_ 2549088379 BMS_HYB_KD_Error "[DE: BMS_HYB_KD_Fehler]";
CM_ SG_ 2549088374 Engine_CompressorProtection "[DE: Motor_KompSchutz]";
CM_ SG_ 2549088374 Engine_RunOnType "[DE: Motor_Nachlauftyp]";
CM_ SG_ 2549088374 MO_KD_Error "[DE: MO_KD_Fehler]";
CM_ SG_ 2549088284 SAK_CompressorProtection "[DE: SAK_KompSchutz]";
CM_ SG_ 2549088284 SAK_RunOnType "[DE: SAK_Nachlauftyp]";
CM_ SG_ 2549088284 SAK_KD_Error "[DE: SAK_KD_Fehler]";
CM_ SG_ 779 KBI_ABS_Lamp "[DE: KBI_ABS_Lampe]";
CM_ SG_ 779 KBI_ESP_Lamp "[DE: KBI_ESP_Lampe]";
CM_ SG_ 779 KBI_BKL_Lamp "[DE: KBI_BKL_Lampe]";
CM_ SG_ 779 KBI_Airbag_Lamp "[DE: KBI_Airbag_Lampe]";
CM_ SG_ 779 KBI_SILA_Valid "[DE: KBI_SILA_gueltig]";
CM_ SG_ 779 KBI_Steering_Lamp "[DE: KBI_Lenkung_Lampe]";
CM_ SG_ 779 KBI_Preheat_System_Lamp "[DE: KBI_Vorglueh_System_Lampe]";
CM_ SG_ 779 KBI_NV_in_Display "[DE: KBI_NV_in_Anzeige]";
CM_ SG_ 779 Cluster_01_BZ "[DE: Kombi_01_BZ]";
CM_ SG_ 779 KBI_DisplayStatus_ACC "[DE: KBI_Anzeigestatus_ACC]";
CM_ SG_ 779 KBI_DisplayStatus_GRA "[DE: KBI_Anzeigestatus_GRA]";
CM_ SG_ 779 KBI_OilPressure_Switch "[DE: KBI_Oeldruck_Schalter]";
CM_ SG_ 779 KBI_LowFuelWarning "[DE: KBI_Tankwarnung]";
CM_ SG_ 779 KBI_MFA_v_Unit_01 "[DE: KBI_MFA_v_Einheit_01]";
CM_ SG_ 779 KBI_In_ActuatorTest "[DE: KBI_im_Stellgliedtest]";
CM_ SG_ 779 KBI_DisplayFault_LDW "[DE: KBI_Anzeigefehler_LDW]";
CM_ SG_ 779 KBI_Variant_USA "[DE: KBI_Variante_USA]";
CM_ SG_ 779 KBI_OilPressureWarning "[DE: KBI_Oeldruckwarnung]";
CM_ SG_ 779 KBI_Handbrake "[DE: KBI_Handbremse]";
CM_ SG_ 779 KBI_PLA_in_Display "[DE: KBI_PLA_in_Anzeige]";
CM_ SG_ 779 KBI_DisplayFault_NV "[DE: KBI_Anzeigefehler_NV]";
CM_ SG_ 779 KBI_DisplayStatus_LIM "[DE: KBI_Anzeigestatus_LIM]";
CM_ SG_ 779 KBI_Displayed_Speed "[DE: KBI_angez_Geschw]";
CM_ SG_ 779 KBI_Unit_Speedo "[DE: KBI_Einheit_Tacho]";
CM_ SG_ 779 KBI_Consistency_ACC "[DE: KBI_Konsistenz_ACC]";
CM_ SG_ 779 KBI_Error_Display_ACC "[DE: KBI_Fehler_Anzeige_ACC]";
CM_ SG_ 779 KBI_DisplayFault_SWA "[DE: KBI_Anzeigefehler_SWA]";
CM_ SG_ 1719 KBI_Odometer "[DE: KBI_Kilometerstand]";
CM_ SG_ 1719 KBI_ParkedTime_02 "[DE: KBI_Standzeit_02]";
CM_ SG_ 1719 KBI_Contents_Tank "[DE: KBI_Inhalt_Tank]";
CM_ SG_ 1719 KBI_QBit_Outside_Temp_Filt "[DE: KBI_QBit_Aussen_Temp_gef]";
CM_ SG_ 1719 KBI_Outside_Temp_Filt "[DE: KBI_Aussen_Temp_gef]";
CM_ SG_ 982 Light_Rear_01_BZ "[DE: Licht_hinten_01_BZ]";
CM_ SG_ 982 BCM2_BrakeLight_By_ECD "[DE: BCM2_Bremsl_durch_ECD]";
CM_ SG_ 982 LH_OutsideLight_def "[DE: LH_Aussenlicht_def]";
CM_ SG_ 982 LH_SideLight_H_Active "[DE: LH_Standlicht_H_aktiv]";
CM_ SG_ 982 LH_ParkingLight_HL_Active "[DE: LH_Parklicht_HL_aktiv]";
CM_ SG_ 982 LH_ParkingLight_HR_Active "[DE: LH_Parklicht_HR_aktiv]";
CM_ SG_ 982 LH_BrakeLight_H_Active "[DE: LH_Bremslicht_H_aktiv]";
CM_ SG_ 982 LH_RearFog_Active "[DE: LH_Nebelschluss_aktiv]";
CM_ SG_ 982 LH_ReversingLight_Active "[DE: LH_Rueckfahrlicht_aktiv]";
CM_ SG_ 982 LH_Indicator_HL_Act "[DE: LH_Blinker_HL_akt]";
CM_ SG_ 982 LH_Indicator_HR_Act "[DE: LH_Blinker_HR_akt]";
CM_ SG_ 982 LH_Indicator_Left_def "[DE: LH_Blinker_li_def]";
CM_ SG_ 982 LH_BrakeLight_Left_def "[DE: LH_Bremsl_li_def]";
CM_ SG_ 982 LH_TailLight_Left_def "[DE: LH_Schlusslicht_li_def]";
CM_ SG_ 982 LH_Reverse_Left_def "[DE: LH_Rueckf_li_def]";
CM_ SG_ 982 LH_Fog_Left_def "[DE: LH_Nebel_li_def]";
CM_ SG_ 982 LH_End_Brake_Fog_Left_def "[DE: LH_Schluss_Brems_Nebel_li_def]";
CM_ SG_ 982 LH_End_Brake_Fog_Right_def "[DE: LH_Schluss_Brems_Nebel_re_def]";
CM_ SG_ 982 LH_End_Brake_Left_def "[DE: LH_Schluss_Brems_li_def]";
CM_ SG_ 982 LH_End_Fog_Left_def "[DE: LH_Schluss_Nebel_li_def]";
CM_ SG_ 982 LH_SL_BRL_BLK_Left_def "[DE: LH_SL_BRL_BLK_li_def]";
CM_ SG_ 982 LH_Brake_Blk_Left_def "[DE: LH_Brems_Blk_li_def]";
CM_ SG_ 982 LH_Indicator_Right_def "[DE: LH_Blinker_re_def]";
CM_ SG_ 982 LH_BrakeLight_Right_def "[DE: LH_Bremsl_re_def]";
CM_ SG_ 982 LH_TailLight_Right_def "[DE: LH_Schlusslicht_re_def]";
CM_ SG_ 982 LH_Reverse_Right_def "[DE: LH_Rueckf_re_def]";
CM_ SG_ 982 LH_Fog_Right_def "[DE: LH_Nebel_re_def]";
CM_ SG_ 982 LH_End_Brake_Right_def "[DE: LH_Schluss_Brems_re_def]";
CM_ SG_ 982 LH_End_Fog_Right_def "[DE: LH_Schluss_Nebel_re_def]";
CM_ SG_ 982 LH_SL_BRL_BLK_Right_def "[DE: LH_SL_BRL_BLK_re_def]";
CM_ SG_ 982 LH_Brake_Blk_Right_def "[DE: LH_Brems_Blk_re_def]";
CM_ SG_ 982 LH_3_BrakeLight_def "[DE: LH_3_Bremsl_def]";
CM_ SG_ 982 LH_Fog_mi_def "[DE: LH_Nebel_mi_def]";
CM_ SG_ 982 LH_Reverse_mi_def "[DE: LH_Rueckf_mi_def]";
CM_ SG_ 982 LH_BrakeLight_Left_Total_def "[DE: LH_Bremsl_li_ges_def]";
CM_ SG_ 982 LH_BrakeLight_Right_Total_def "[DE: LH_Bremsl_re_ges_def]";
CM_ SG_ 134 LWI_QBit_Sub_Data "[DE: LWI_QBit_Sub_Daten]";
CM_ SG_ 134 LWI_QBit_SteeringWheelAngle "[DE: LWI_QBit_Lenkradwinkel]";
CM_ SG_ 134 LWI_VZ_SteeringWheelAngle "[DE: LWI_VZ_Lenkradwinkel]";
CM_ SG_ 134 LWI_VZ_SteeringWheelAngle_Speed "[DE: LWI_VZ_Lenkradw_Geschw]";
CM_ SG_ 134 LWI_SteeringWheelAngle_Speed "[DE: LWI_Lenkradw_Geschw]";
CM_ SG_ 134 LWI_Sub_Data "[DE: LWI_Sub_Daten]";
CM_ SG_ 263 MO_ActualGear "[DE: MO_Istgang]";
CM_ SG_ 263 MO_TargetGear "[DE: MO_Sollgang]";
CM_ SG_ 263 MO_OilPressure "[DE: MO_Oeldruck]";
CM_ SG_ 263 MO_DisplayRpm "[DE: MO_Anzeigedrehz]";
CM_ SG_ 263 MO_ShiftRecommend_Available "[DE: MO_Schaltempf_verfbar]";
CM_ SG_ 263 MO_BoostPressure "[DE: MO_Ladedruck]";
CM_ SG_ 263 MO_KVS_Overflow "[DE: MO_KVS_Ueberlauf]";
CM_ SG_ 1600 MO_QBit_IntakeAir_Temp "[DE: MO_QBit_Ansaugluft_Temp]";
CM_ SG_ 1600 MO_QBit_Oil_Temp "[DE: MO_QBit_Oel_Temp]";
CM_ SG_ 1600 MO_QBit_Coolant_Temp "[DE: MO_QBit_Kuehlmittel_Temp]";
CM_ SG_ 1600 MO_ActuatorTest_SoundActuator "[DE: MO_Stellgliedtest_Soundaktuator]";
CM_ SG_ 1600 MO_HYB_Error_HV_Network "[DE: MO_HYB_Fehler_HV_Netz]";
CM_ SG_ 1600 MO_Active_GearboxHeat "[DE: MO_aktives_Getriebeheizen]";
CM_ SG_ 1600 MO_ShutOffValve_Open "[DE: MO_Absperrventil_oeffnen]";
CM_ SG_ 1600 MO_IntakeAir_Temp "[DE: MO_Ansaugluft_Temp]";
CM_ SG_ 1600 MO_Oil_Temp "[DE: MO_Oel_Temp]";
CM_ SG_ 1600 MO_Coolant_Temp "[DE: MO_Kuehlmittel_Temp]";
CM_ SG_ 1600 MO_AltitudeInfo "[DE: MO_Hoeheninfo]";
CM_ SG_ 1600 MO_VersionInfo "[DE: MO_Versionsinfo]";
CM_ SG_ 1600 MO_Gearbox_Cool "[DE: MO_Getriebe_kuehlen]";
CM_ SG_ 1600 MO_Torque_Inertia_02 "[DE: MO_Mom_Traegheit_02]";
CM_ SG_ 1600 MO_HeatingPumpActuation "[DE: MO_Heizungspumpenansteuerung]";
CM_ SG_ 1600 MO_VoltageReq "[DE: MO_SpannungsAnf]";
CM_ SG_ 1600 MO_RunOnTime_HeatingPump "[DE: MO_Nachlaufzeit_Heizungspumpe]";
CM_ SG_ 1607 MO_ITM_Coolant_Temp "[DE: MO_ITM_Kuehlmittel_Temp]";
CM_ SG_ 1607 SCR_Disp_Motorstarts "[DE: SCR_Anz_Motorstarts]";
CM_ SG_ 1607 SCR_Range "[DE: SCR_Reichweite]";
CM_ SG_ 1607 SCR_WarningLevel_1 "[DE: SCR_Warnstufe_1]";
CM_ SG_ 1607 SCR_WarningLevel_2 "[DE: SCR_Warnstufe_2]";
CM_ SG_ 1607 SCR_Acoustic "[DE: SCR_Akustik]";
CM_ SG_ 1607 MO_Kraftstofffilter_Water "[DE: MO_Kraftstofffilter_Wasser]";
CM_ SG_ 1607 SCR_SystemError "[DE: SCR_Systemfehler]";
CM_ SG_ 1607 SCR_Inducement_Strategy "[DE: SCR_Inducement_Strategie]";
CM_ SG_ 1607 MO_CO2_Factor "[DE: MO_CO2_Faktor]";
CM_ SG_ 167 Engine_11_CRC "[DE: Motor_11_CRC]";
CM_ SG_ 167 Engine_11_BZ "[DE: Motor_11_BZ]";
CM_ SG_ 167 MO_Torque_Target_Raw "[DE: MO_Mom_Soll_Roh]";
CM_ SG_ 167 MO_Torque_Actual_Sum "[DE: MO_Mom_Ist_Summe]";
CM_ SG_ 167 MO_Torque_Inertia_Sum "[DE: MO_Mom_Traegheit_Summe]";
CM_ SG_ 167 MO_Torque_Target_Filtered "[DE: MO_Mom_Soll_gefiltert]";
CM_ SG_ 167 MO_Torque_Overrun "[DE: MO_Mom_Schub]";
CM_ SG_ 167 MO_Status_NormalOperation_01 "[DE: MO_Status_Normalbetrieb_01]";
CM_ SG_ 167 MO_First_InaccurateThreshold "[DE: MO_erste_Ungenauschwelle]";
CM_ SG_ 167 MO_QBit_EngineTorques "[DE: MO_QBit_Motormomente]";
CM_ SG_ 168 Engine_12_CRC "[DE: Motor_12_CRC]";
CM_ SG_ 168 Engine_12_BZ "[DE: Motor_12_BZ]";
CM_ SG_ 168 MO_Torque_Neg_Available "[DE: MO_Mom_neg_verfuegbar]";
CM_ SG_ 168 MO_Torque_Limit_Status "[DE: MO_Mom_Begr_stat]";
CM_ SG_ 168 MO_Torque_Limit_Dyn "[DE: MO_Mom_Begr_dyn]";
CM_ SG_ 168 MO_TorqueIntegral_02 "[DE: MO_Momentenintegral_02]";
CM_ SG_ 168 MO_QBit_Rpm_01 "[DE: MO_QBit_Drehzahl_01]";
CM_ SG_ 168 MO_Rpm_01 "[DE: MO_Drehzahl_01]";
CM_ SG_ 958 MO_StartStop_Status "[DE: MO_StartStopp_Status]";
CM_ SG_ 958 MO_StartStop_Restart "[DE: MO_StartStopp_Wiederstart]";
CM_ SG_ 958 MO_StartStop_EngineStop "[DE: MO_StartStopp_Motorstopp]";
CM_ SG_ 958 MO_Enable_Recup "[DE: MO_Freig_Reku]";
CM_ SG_ 958 MO_Term_75 "[DE: MO_Kl_75]";
CM_ SG_ 958 MO_Term_50 "[DE: MO_Kl_50]";
CM_ SG_ 958 MO_GearPosition "[DE: MO_Gangposition]";
CM_ SG_ 958 MO_StartStop_DriverDemand "[DE: MO_StartStopp_Fahrerwunsch]";
CM_ SG_ 958 MO_HYB_ReadyToDrive "[DE: MO_HYB_Fahrbereitschaft]";
CM_ SG_ 958 MO_Ext_E_Journey_Active "[DE: MO_Ext_E_Fahrt_aktiv]";
CM_ SG_ 958 MO_Driver_Brakes "[DE: MO_Fahrer_bremst]";
CM_ SG_ 958 MO_QBit_Driver_Brakes "[DE: MO_QBit_Fahrer_bremst]";
CM_ SG_ 958 MO_Consistency_BrakePedal "[DE: MO_Konsistenz_Bremsped]";
CM_ SG_ 958 MO_Climate_Interv "[DE: MO_Klima_Eingr]";
CM_ SG_ 958 MO_Aussp_Crank "[DE: MO_Aussp_Anlass]";
CM_ SG_ 958 MO_Enable_Crank "[DE: MO_Freig_Anlass]";
CM_ SG_ 958 MO_Clutch_Switch "[DE: MO_Kuppl_schalter]";
CM_ SG_ 958 MO_Engine_Running "[DE: MO_Motor_laeuft]";
CM_ SG_ 958 MO_Status_CylDeact_01 "[DE: MO_Status_Zylabschalt_01]";
CM_ SG_ 958 MO_ETermCommLeiRed "[DE: MO_EKlKomLeiRed]";
CM_ SG_ 958 MO_BKV_VacuumWarning "[DE: MO_BKV_Unterdruckwarnung]";
CM_ SG_ 958 MO_Enable_Coasting "[DE: MO_Freigabe_Segeln]";
CM_ SG_ 958 MO_QBit_GearPosition "[DE: MO_QBit_Gangposition]";
CM_ SG_ 958 MO_SignalSource_GearPosition "[DE: MO_Signalquelle_Gangposition]";
CM_ SG_ 958 MO_Remotestart_Operation "[DE: MO_Remotestart_Betrieb]";
CM_ SG_ 1631 TSK_QBit_Gradient "[DE: TSK_QBit_Steigung]";
CM_ SG_ 1631 TSK_QBit_VehicleMass "[DE: TSK_QBit_Fahrzeugmasse]";
CM_ SG_ 1631 MO_VoltageReq_02 "[DE: MO_SpannungsAnf_02]";
CM_ SG_ 1631 MO_HeaterCurrent_EKAT "[DE: MO_Heizstrom_EKAT]";
CM_ SG_ 1631 MO_HeaterCurrent_SCR "[DE: MO_Heizstrom_SCR]";
CM_ SG_ 1631 TSK_VehicleMass_02 "[DE: TSK_Fahrzeugmasse_02]";
CM_ SG_ 1631 TSK_Gradient "[DE: TSK_Steigung]";
CM_ SG_ 812 MO_Prio_MAX_RequestedRpm "[DE: MO_Prio_MAX_Wunschdrehzahl]";
CM_ SG_ 812 MO_Prio_MIN_RequestedRpm "[DE: MO_Prio_MIN_Wunschdrehzahl]";
CM_ SG_ 812 MO_AirPath_Active "[DE: MO_Luftpfad_aktiv]";
CM_ SG_ 812 MO_v_Limit_Activatable "[DE: MO_v_Begrenz_Aktivierbar]";
CM_ SG_ 812 MO_RpmInfluence "[DE: MO_Drehzahlbeeinflussung]";
CM_ SG_ 812 MO_MIN_RequestedRpm "[DE: MO_MIN_Wunschdrehzahl]";
CM_ SG_ 812 MO_MAX_RequestedRpm "[DE: MO_MAX_Wunschdrehzahl]";
CM_ SG_ 812 MO_Charisma_DrivePr "[DE: MO_Charisma_FahrPr]";
CM_ SG_ 1648 MO_Hybrid_StartStop_LED "[DE: MO_Hybrid_StartStopp_LED]";
CM_ SG_ 1648 MO_Count_Abgesch_Cyl "[DE: MO_Anzahl_Abgesch_Zyl]";
CM_ SG_ 1648 MO_CylDeact_Texte "[DE: MO_Zylabsch_Texte]";
CM_ SG_ 1648 MO_Rpm_Warning "[DE: MO_Drehzahl_Warnung]";
CM_ SG_ 1648 MO_Upper_RpmLimit "[DE: MO_obere_Drehzahlgrenze]";
CM_ SG_ 289 MO_AccelPedalRaw_01 "[DE: MO_Fahrpedalrohwert_01]";
CM_ SG_ 289 MO_QBit_AccelPedalValues_01 "[DE: MO_QBit_Fahrpedalwerte_01]";
CM_ SG_ 289 MO_AccelPedalGradient "[DE: MO_Fahrpedalgradient]";
CM_ SG_ 289 MO_Sig_AccelPedalGradient "[DE: MO_Sig_Fahrpedalgradient]";
CM_ SG_ 289 MO_rel_ManifoldPressure "[DE: MO_rel_Saugrohrdruck]";
CM_ SG_ 289 MO_rel_ManifoldPressure_gem_err "[DE: MO_rel_Saugrohrdruck_gem_err]";
CM_ SG_ 289 MO_Torque_In_Idle "[DE: MO_Moment_im_Leerlauf]";
CM_ SG_ 289 MO_OverrunFuelCut "[DE: MO_Schubabschaltung]";
CM_ SG_ 289 MO_StartStop_StopPreparation "[DE: MO_StartStopp_StoppVorbereitung]";
CM_ SG_ 289 MO_TargetRpm_Idle "[DE: MO_Solldrehz_Leerlauf]";
CM_ SG_ 289 MO_Decoupling_Sollschlupf "[DE: MO_Entkopplung_Sollschlupf]";
CM_ SG_ 289 TSK_a_Target_gradientenbegrenzt "[DE: TSK_a_Soll_gradientenbegrenzt]";
CM_ SG_ 967 MO_HYB_Status_HV_Charge "[DE: MO_HYB_Status_HV_Ladung]";
CM_ SG_ 967 WIV_Display_Active "[DE: WIV_Anzeige_aktiv]";
CM_ SG_ 967 WIV_SensorError "[DE: WIV_Sensorfehler]";
CM_ SG_ 967 WIV_Tilt "[DE: WIV_Schieflage]";
CM_ SG_ 967 WIV_OilLevel "[DE: WIV_Oelstand]";
CM_ SG_ 967 MO_State_HWP "[DE: MO_Zustand_HWP]";
CM_ SG_ 967 WIV_OilSystem_Active "[DE: WIV_Oelsystem_aktiv]";
CM_ SG_ 967 WIV_Not_AtOperatingTemp "[DE: WIV_nicht_betriebswarm]";
CM_ SG_ 967 WIV_Overfill_Warn "[DE: WIV_Ueberfuell_Warn]";
CM_ SG_ 967 WIV_Running_Engine "[DE: WIV_laufender_Motor]";
CM_ SG_ 967 MO_Text_EngineStart "[DE: MO_Text_Motorstart]";
CM_ SG_ 967 MO_Text_ParticleFilter_Reg "[DE: MO_Text_Partikelfil_Reg]";
CM_ SG_ 967 WIV_OilQuantity "[DE: WIV_Oelmenge]";
CM_ SG_ 967 MO_SystemLamp "[DE: MO_Systemlampe]";
CM_ SG_ 967 MO_OBD2_Lamp "[DE: MO_OBD2_Lampe]";
CM_ SG_ 967 MO_HotWarningLamp "[DE: MO_Heissleuchte]";
CM_ SG_ 967 MO_Particle_Lamp "[DE: MO_Partikel_Lampe]";
CM_ SG_ 967 MO_WinterProgram "[DE: MO_Winterfahrprog]";
CM_ SG_ 967 WIV_OilLevel_Not_Present "[DE: WIV_Oelstand_nicht_vorhanden]";
CM_ SG_ 967 WIV_RefillDisplay_On "[DE: WIV_nachfuellanzeige_ein]";
CM_ SG_ 967 WIV_Overfill_Deactivated "[DE: WIV_Ueberfuell_deaktiv]";
CM_ SG_ 967 WIV_Underfill_Warn "[DE: WIV_Unterfuell_Warn]";
CM_ SG_ 967 MO_FuelCap_Lamp "[DE: MO_Tankdeckel_Lampe]";
CM_ SG_ 967 MO_Text_FuelCapWarn "[DE: MO_Text_Tankdeckelwarn]";
CM_ SG_ 967 WIV_OilPressure_Warn_Engine "[DE: WIV_Oeldr_Warn_Motor]";
CM_ SG_ 1601 Engine_Code_01_CRC "[DE: Motor_Code_01_CRC]";
CM_ SG_ 1601 Engine_Code_01_BZ "[DE: Motor_Code_01_BZ]";
CM_ SG_ 1601 MO_Factor_Torques_02 "[DE: MO_Faktor_Momente_02]";
CM_ SG_ 1601 MO_HybridVehicle "[DE: MO_Hybridfahrzeug]";
CM_ SG_ 1601 MO_Gearbox_Code "[DE: MO_Getriebe_Code]";
CM_ SG_ 1601 MO_StartStop_Coded "[DE: MO_StartStopp_Codiert]";
CM_ SG_ 1601 MO_Count_Cyl "[DE: MO_Anzahl_Zyl]";
CM_ SG_ 1601 MO_FuelType "[DE: MO_Kraftstoffart]";
CM_ SG_ 1601 MO_Displacement "[DE: MO_Hubraum]";
CM_ SG_ 1601 MO_IntakeSystem "[DE: MO_Ansaugsystem]";
CM_ SG_ 1601 MO_Power "[DE: MO_Leistung]";
CM_ SG_ 1601 MO_ExhaustType_EOBD "[DE: MO_Abgastyp_EOBD]";
CM_ SG_ 1601 MO_ExhaustType_OBD "[DE: MO_Abgastyp_OBD]";
CM_ SG_ 1601 MO_DPF_Fitted "[DE: MO_DPF_verbaut]";
CM_ SG_ 1601 TSK_Coding "[DE: TSK_Codierung]";
CM_ SG_ 1601 MO_InjectionType "[DE: MO_Einspritzart]";
CM_ SG_ 157 Engine_Hybrid_01_CRC "[DE: Motor_Hybrid_01_CRC]";
CM_ SG_ 157 Engine_Hybrid_01_BZ "[DE: Motor_Hybrid_01_BZ]";
CM_ SG_ 157 MO_HYB_ActualStatusK0 "[DE: MO_HYB_IstStatusK0]";
CM_ SG_ 157 MO_HYB_max_ind_VM_Torque "[DE: MO_HYB_max_ind_VM_Mom]";
CM_ SG_ 157 MO_HYB_TargetState "[DE: MO_HYB_Zielzustand]";
CM_ SG_ 157 MO_HYB_StartMode "[DE: MO_HYB_Startmodus]";
CM_ SG_ 157 MO_HYB_StartMode_PQ3x "[DE: MO_HYB_Startmodus_PQ3x]";
CM_ SG_ 157 MO_HYB_StopMode "[DE: MO_HYB_Stoppmodus]";
CM_ SG_ 157 MO_HYB_VM_Torque_oE "[DE: MO_HYB_VM_Mom_oE]";
CM_ SG_ 157 MO_HYB_VM_Active "[DE: MO_HYB_VM_aktiv]";
CM_ SG_ 157 MO_HYB_ShiftPrevention "[DE: MO_HYB_Schaltverhinderung]";
CM_ SG_ 811 MO_HYB_E_Factor "[DE: MO_HYB_E_Faktor]";
CM_ SG_ 811 MO_HYB_Rpm_VM "[DE: MO_HYB_Drehzahl_VM]";
CM_ SG_ 811 MO_HYB_LowSpeedMode "[DE: MO_HYB_LowSpeedModus]";
CM_ SG_ 2600468501 NM_Airbag_01_NM_Active_TERM15 "[DE: NM_Airbag_01_NM_aktiv_KL15]";
CM_ SG_ 2600468501 NM_Airbag_01_NM_Active_Diagnostics "[DE: NM_Airbag_01_NM_aktiv_Diagnose]";
CM_ SG_ 2600468501 NM_Airbag_01_NM_Active_Tmin "[DE: NM_Airbag_01_NM_aktiv_Tmin]";
CM_ SG_ 2600468604 NM_EEngine_01_SNI "[DE: NM_EMotor_01_SNI]";
CM_ SG_ 2600468604 NM_EEngine_01_NM_State "[DE: NM_EMotor_01_NM_State]";
CM_ SG_ 2600468604 NM_EEngine_01_Car_Wakeup "[DE: NM_EMotor_01_Car_Wakeup]";
CM_ SG_ 2600468604 NM_EEngine_01_Wakeup "[DE: NM_EMotor_01_Wakeup]";
CM_ SG_ 2600468604 NM_EEngine_01_NM_Active_TERM15 "[DE: NM_EMotor_01_NM_aktiv_KL15]";
CM_ SG_ 2600468604 NM_EEngine_01_NM_Active_Diagnostics "[DE: NM_EMotor_01_NM_aktiv_Diagnose]";
CM_ SG_ 2600468604 NM_EEngine_01_NM_Active_Tmin "[DE: NM_EMotor_01_NM_aktiv_Tmin]";
CM_ SG_ 2600468604 NM_EEngine_01_NL_Data_EEPROM "[DE: NM_EMotor_01_NL_Daten_EEPROM]";
CM_ SG_ 2600468604 NM_EEngine_01_UDS_CC "[DE: NM_EMotor_01_UDS_CC]";
CM_ SG_ 2600468496 NM_Gateway_NM_Active_TERM15 "[DE: NM_Gateway_NM_aktiv_KL15]";
CM_ SG_ 2600468496 NM_Gateway_NM_Active_Diagnostics "[DE: NM_Gateway_NM_aktiv_Diagnose]";
CM_ SG_ 2600468496 NM_Gateway_NM_Active_Tmin "[DE: NM_Gateway_NM_aktiv_Tmin]";
CM_ SG_ 2600468496 NM_Gateway_ACAN_Activity "[DE: NM_Gateway_ACAN_Aktivitaet]";
CM_ SG_ 2600468496 NM_Gateway_FCAN_Activity "[DE: NM_Gateway_FCAN_Aktivitaet]";
CM_ SG_ 2600468496 NM_Gateway_KCAN_Activity "[DE: NM_Gateway_KCAN_Aktivitaet]";
CM_ SG_ 2600468496 NM_Gateway_ICAN_Activity "[DE: NM_Gateway_ICAN_Aktivitaet]";
CM_ SG_ 2600468496 NM_Gateway_DiagCAN_Activity "[DE: NM_Gateway_DiagCAN_Aktivitaet]";
CM_ SG_ 2600468496 NM_Gateway_ECAN_Activity "[DE: NM_Gateway_ECAN_Aktivitaet]";
CM_ SG_ 2600468496 NM_Gateway_Energy_LIN_Aktivi000 "[DE: NM_Gateway_Energie_LIN_Aktivi000]";
CM_ SG_ 2600468496 NM_Gateway_Bedien_LIN_Activity "[DE: NM_Gateway_Bedien_LIN_Aktivitaet]";
CM_ SG_ 2600468496 NM_Gateway_EM_Activity "[DE: NM_Gateway_EM_Aktivitaet]";
CM_ SG_ 2600468496 NM_Gateway_NL_Volt_Measurement "[DE: NM_Gateway_NL_Spg_Messung]";
CM_ SG_ 2600468599 NM_Gearbox_01_SNI "[DE: NM_Getriebe_01_SNI]";
CM_ SG_ 2600468599 NM_Gearbox_01_NM_State "[DE: NM_Getriebe_01_NM_State]";
CM_ SG_ 2600468599 NM_Gearbox_01_Car_Wakeup "[DE: NM_Getriebe_01_Car_Wakeup]";
CM_ SG_ 2600468599 NM_Gearbox_01_Wakeup "[DE: NM_Getriebe_01_Wakeup]";
CM_ SG_ 2600468599 NM_Gearbox_01_NM_Active_TERM15 "[DE: NM_Getriebe_01_NM_aktiv_KL15]";
CM_ SG_ 2600468599 NM_Gearbox_01_NM_Active_Diagnostics "[DE: NM_Getriebe_01_NM_aktiv_Diagnose]";
CM_ SG_ 2600468599 NM_Gearbox_01_NM_Active_Tmin "[DE: NM_Getriebe_01_NM_aktiv_Tmin]";
CM_ SG_ 2600468599 NM_Gearbox_01_NM_Active_v_gr_0 "[DE: NM_Getriebe_01_NM_aktiv_v_gr_0]";
CM_ SG_ 2600468599 NM_Gearbox_01_NM_Active_Pos_Det "[DE: NM_Getriebe_01_NM_aktiv_Pos_Erk]";
CM_ SG_ 2600468599 NM_Gearbox_01_NM_Active_Umg_Condition "[DE: NM_Getriebe_01_NM_aktiv_Umg_Bed]";
CM_ SG_ 2600468599 NM_Gearbox_01_NL_Data_EEPROM "[DE: NM_Getriebe_01_NL_Daten_EEPROM]";
CM_ SG_ 2600468599 NM_Gearbox_01_UDS_CC "[DE: NM_Getriebe_01_UDS_CC]";
CM_ SG_ 2600468603 NM_Hybrid_01_NM_Active_TERM15 "[DE: NM_Hybrid_01_NM_aktiv_KL15]";
CM_ SG_ 2600468603 NM_Hybrid_01_NM_Active_Diagnostics "[DE: NM_Hybrid_01_NM_aktiv_Diagnose]";
CM_ SG_ 2600468603 NM_Hybrid_01_NM_Active_Tmin "[DE: NM_Hybrid_01_NM_aktiv_Tmin]";
CM_ SG_ 2600468603 NM_Hybrid_01_NL_Data_EEPROM "[DE: NM_Hybrid_01_NL_Daten_EEPROM]";
CM_ SG_ 2600468603 NM_Hybrid_01_NL_Fan "[DE: NM_Hybrid_01_NL_Luefter]";
CM_ SG_ 2600468598 NM_MO_01_NM_Active_TERM15 "[DE: NM_MO_01_NM_aktiv_KL15]";
CM_ SG_ 2600468598 NM_MO_01_NM_Active_Diagnostics "[DE: NM_MO_01_NM_aktiv_Diagnose]";
CM_ SG_ 2600468598 NM_MO_01_NM_Active_Tmin "[DE: NM_MO_01_NM_aktiv_Tmin]";
CM_ SG_ 2600468598 NM_MO_01_NM_Active_HV_Shutdown "[DE: NM_MO_01_NM_aktiv_HV_Abschaltung]";
CM_ SG_ 2600468598 NM_MO_01_NM_Active_EKP_Lead "[DE: NM_MO_01_NM_aktiv_EKP_Vorlauf]";
CM_ SG_ 2600468598 NM_MO_01_NM_Active_STH_Operation "[DE: NM_MO_01_NM_aktiv_STH_Betrieb]";
CM_ SG_ 2600468598 NM_MO_01_NL_RadiatorFan "[DE: NM_MO_01_NL_Kuehlerluefter]";
CM_ SG_ 2600468598 NM_MO_01_NL_Diagnostics "[DE: NM_MO_01_NL_Diagnose]";
CM_ SG_ 2600468598 NM_MO_01_NL_Other "[DE: NM_MO_01_NL_Sonstige]";
CM_ SG_ 913 OBD_ColdStart_Denominator "[DE: OBD_Kaltstart_Denominator]";
CM_ SG_ 1630 OBD_TG_Sens_RawValue_1 "[DE: OBD_TG_Sens_Rohwert_1]";
CM_ SG_ 1630 OBD_TG_Sens_RawValue_2 "[DE: OBD_TG_Sens_Rohwert_2]";
CM_ SG_ 1630 OBD_TG_Sens_RawValue_3 "[DE: OBD_TG_Sens_Rohwert_3]";
CM_ SG_ 1630 OBD_TG_Sens_RawValue_4 "[DE: OBD_TG_Sens_Rohwert_4]";
CM_ SG_ 1437 RSF_KeyCode_1 "[DE: RSF_Tastencode_1]";
CM_ SG_ 1437 RSF_KeyCode_2 "[DE: RSF_Tastencode_2]";
CM_ SG_ 1437 RSF_KeyCode_Maske "[DE: RSF_Tastencode_Maske]";
CM_ SG_ 984 RGS_VL_Charisma_DrivePr "[DE: RGS_VL_Charisma_FahrPr]";
CM_ SG_ 984 RGS_VL_Active "[DE: RGS_VL_aktiv]";
CM_ SG_ 984 RGS_VL_PC_Actuator_Seat "[DE: RGS_VL_PC_Aktuator_Sitz]";
CM_ SG_ 984 RGS_VL_PC_Actuator_Sunroof "[DE: RGS_VL_PC_Aktuator_Schiebedach]";
CM_ SG_ 984 RGS_VL_PC_Actuator_Window "[DE: RGS_VL_PC_Aktuator_Fenster]";
CM_ SG_ 984 RGS_VL_PC_Actuator_HazardFlash "[DE: RGS_VL_PC_Aktuator_Warnblinken]";
CM_ SG_ 984 RGS_VL_Precrash_Base "[DE: RGS_VL_Precrash_Basis]";
CM_ SG_ 1528 SAK_Charisma_DrivePr "[DE: SAK_Charisma_FahrPr]";
CM_ SG_ 1313 STH_Radio_On "[DE: STH_Funk_ein]";
CM_ SG_ 1313 STH_Radio_Off "[DE: STH_Funk_aus]";
CM_ SG_ 1313 STH_AuxHeater "[DE: STH_Zusatzheizung]";
CM_ SG_ 1313 STH_Pump_On "[DE: STH_Pumpe_ein]";
CM_ SG_ 1313 STH_Blower "[DE: STH_Geblaese]";
CM_ SG_ 1313 STH_Start_Follows "[DE: STH_Start_folgt]";
CM_ SG_ 1313 STH_ValveOpeningTime "[DE: STH_Ventiloeffnungszeit]";
CM_ SG_ 1313 STH_Valve_Status "[DE: STH_Ventil_Status]";
CM_ SG_ 1313 STH_ErrorStatus "[DE: STH_Fehlerstatus]";
CM_ SG_ 1313 STH_HeatPower "[DE: STH_Heizleistung]";
CM_ SG_ 1313 STH_WaterTemp "[DE: STH_Wassertemp]";
CM_ SG_ 1313 STH_Was_Active "[DE: STH_war_aktiv]";
CM_ SG_ 1313 STH_KVS_Overflow "[DE: STH_KVS_Ueberlauf]";
CM_ SG_ 1313 STH_KD_Error "[DE: STH_KD_Fehler]";
CM_ SG_ 1172 Status_01_CRC "[DE: STS_01_CRC]";
CM_ SG_ 1172 Status_01_BZ "[DE: STS_01_BZ]";
CM_ SG_ 1172 Status_Car_not_under_theft "[DE: STS_Car_not_under_theft]";
CM_ SG_ 1172 Status_Car_under_theft "[DE: STS_Car_under_theft]";
CM_ SG_ 1172 Status_StarterLock "[DE: STS_Anlassersperre]";
CM_ SG_ 1172 Status_TypeCoding "[DE: STS_Typencodierung]";
CM_ SG_ 1172 Status_LIN_Active "[DE: STS_LIN_aktiv]";
CM_ SG_ 1172 Status_SideLight "[DE: STS_Standlicht]";
CM_ SG_ 1172 Status_Headlights "[DE: STS_Fahrlicht]";
CM_ SG_ 1172 Status_Alarm_still "[DE: STS_Alarm_still]";
CM_ SG_ 1172 Status_Texte "[DE: STS_Texte]";
CM_ SG_ 1172 Status_ChargeRelay "[DE: STS_Laderelais]";
CM_ SG_ 1172 Status_Buzzer "[DE: STS_Summer]";
CM_ SG_ 1172 Status_Alarm_Indicator "[DE: STS_Alarm_Blinker]";
CM_ SG_ 1172 Status_EmergencyStart "[DE: STS_Notstart]";
CM_ SG_ 1172 Status_Horn "[DE: STS_Signalhorn]";
CM_ SG_ 1172 Status_IdleShift "[DE: STS_Leerlaufschaltung]";
CM_ SG_ 1413 SI_Collective_ECU_Error "[DE: SI_Sammel_SG_Fehler]";
CM_ SG_ 1413 SI_NWDF_Valid "[DE: SI_NWDF_gueltig]";
CM_ SG_ 1413 SI_GeneralFault "[DE: SI_Sammelfehler]";
CM_ SG_ 1413 GW_KD_Error "[DE: GW_KD_Fehler]";
CM_ SG_ 288 TSK_WheelBrakeTorque "[DE: TSK_Radbremsmom]";
CM_ SG_ 288 TSK_v_Limit_Active "[DE: TSK_v_Begrenzung_aktiv]";
CM_ SG_ 288 TSK_Standby_Req_ESP "[DE: TSK_Standby_Anf_ESP]";
CM_ SG_ 288 TSK_Enable_WU "[DE: TSK_Freig_WU]";
CM_ SG_ 288 TSK_Enable_Decel_Req "[DE: TSK_Freig_Verzoeg_Anf]";
CM_ SG_ 288 TSK_Limiter_Selected "[DE: TSK_Limiter_ausgewaehlt]";
CM_ SG_ 288 TSK_Request_Ratio "[DE: TSK_Wunsch_Uebersetz]";
CM_ SG_ 288 TSK_MainSwitch_GRA_ACC "[DE: TSK_Hauptschalter_GRA_ACC]";
CM_ SG_ 288 TSK_SRBM_Req_ASIL "[DE: TSK_SRBM_Anf_ASIL]";
CM_ SG_ 288 TSK_ax_Gearbox_02 "[DE: TSK_ax_Getriebe_02]";
CM_ SG_ 288 TSK_Allowed_ControlDeviation "[DE: TSK_zul_Regelabw]";
CM_ SG_ 798 TSK_SetSpeed "[DE: TSK_Wunschgeschw]";
CM_ SG_ 798 TSK_Acoustic "[DE: TSK_Akustik]";
CM_ SG_ 798 TSK_Texte_PrimaryDisplay "[DE: TSK_Texte_Primaeranz]";
CM_ SG_ 798 TSK_Limiter_DriverInfo "[DE: TSK_Limiter_Fahrerinfo]";
CM_ SG_ 798 TSK_Limiter_Display "[DE: TSK_Limiter_Anzeige]";
CM_ SG_ 798 TSK_VehicleStatus_GRA "[DE: TSK_Fahrzeugstatus_GRA]";
CM_ SG_ 798 TSK_VehicleStatus_Limiter "[DE: TSK_Fahrzeugstatus_Limiter]";
CM_ SG_ 798 MO_EngineRunningWarning "[DE: MO_Motorlaufwarnung]";
CM_ SG_ 798 TSK_Status_Display "[DE: TSK_Status_Anzeige]";
CM_ SG_ 346 MO_Request_HMS "[DE: MO_Anforderung_HMS]";
CM_ SG_ 346 TSK_vMax_DriverAssist "[DE: TSK_vMax_Fahrerassistenz]";
CM_ SG_ 346 TSK_Unit_vMax_DriverAssist "[DE: TSK_Einheit_vMax_Fahrerassistenz]";
CM_ SG_ 346 TSK_Active_System "[DE: TSK_aktives_System]";
CM_ SG_ 346 TSK_Increased_Fahrwiderstand "[DE: TSK_erhoehter_Fahrwiderstand]";
CM_ SG_ 346 TSK_Req_DriveTorque "[DE: TSK_Anf_Antriebsmoment]";
CM_ SG_ 1716 KS_Secret_1 "[DE: KS_Geheimnis_1]";
CM_ SG_ 1716 KS_Secret_2 "[DE: KS_Geheimnis_2]";
CM_ SG_ 1716 KS_Secret_3 "[DE: KS_Geheimnis_3]";
CM_ SG_ 1716 KS_Secret_4 "[DE: KS_Geheimnis_4]";
CM_ SG_ 175 WH_Status_Lock "[DE: WH_Status_Sperre]";
CM_ SG_ 175 WH_Initialisation "[DE: WH_Initialisierung]";
CM_ SG_ 175 WH_SensorPos_Raw "[DE: WH_SensorPos_roh]";
CM_ SG_ 175 WH_SensorPos_Raw_inv "[DE: WH_SensorPos_roh_inv]";
CM_ SG_ 175 WH_TestResult "[DE: WH_Testergebnis]";
CM_ SG_ 175 WH_Test_Active "[DE: WH_Test_Aktiv]";
CM_ SG_ 916 WBA_DriveRange_02 "[DE: WBA_Fahrstufe_02]";
CM_ SG_ 916 WBA_TargetDriveRange "[DE: WBA_ZielFahrstufe]";
CM_ SG_ 916 WBA_GE_Warning_02 "[DE: WBA_GE_Warnung_02]";
CM_ SG_ 916 WBA_Input_Gear_02 "[DE: WBA_eing_Gang_02]";
CM_ SG_ 916 WBA_Coasting_Active "[DE: WBA_Segeln_aktiv]";
CM_ SG_ 916 WBA_ShiftPattern "[DE: WBA_Schaltschema]";
CM_ SG_ 1602 WIV_WearIndex "[DE: WIV_Verschleissindex]";
CM_ SG_ 1602 WIV_SootIndex "[DE: WIV_Russindex]";
CM_ SG_ 810 EPS_VoltageReq "[DE: EPS_SpannungsAnf]";
CM_ SG_ 810 EPS_AcousticSignal "[DE: EPS_Akustiksignal]";
CM_ SG_ 810 EPS_FaultLamp "[DE: EPS_Fehlerlampe]";
CM_ SG_ 810 EPS_Warnings "[DE: EPS_Warnungen]";
CM_ SG_ 810 EPS_PLA_Abort "[DE: EPS_PLA_Abbruch]";
CM_ SG_ 810 EPS_PLA_Error "[DE: EPS_PLA_Fehler]";
CM_ SG_ 810 EPS_Charisma_DrivePr "[DE: EPS_Charisma_FahrPr]";
CM_ SG_ 810 EPS_HandlebarPosition "[DE: EPS_Lenkerposition]";
CM_ SG_ 810 EPS_Req_TERM "[DE: EPS_Anf_KL]";
CM_ SG_ 159 EPS_SteeringTorque_QBit "[DE: EPS_Lenkmoment_QBit]";
CM_ SG_ 159 EPS_SteeringType "[DE: EPS_Lenkungstyp]";
CM_ SG_ 286 ESP_ANB_CM_Rueckk_Convert "[DE: ESP_ANB_CM_Rueckk_Umsetz]";
CM_ SG_ 286 ESP_Consistency_ACC_Message "[DE: ESP_Konsistenz_ACC_Botschaft]";
CM_ SG_ 286 ESP_ZT_Rueckk_Convert "[DE: ESP_ZT_Rueckk_Umsetz]";
CM_ SG_ 286 ESP_DoorContact_DriverDoor "[DE: ESP_Tuerkontakt_Fahrertuer]";
CM_ SG_ 286 ESP_Abrutschen_Standstill "[DE: ESP_Abrutschen_Stillstand]";
CM_ SG_ 286 ESP_Driver_Occurs_ZBR_Threshold "[DE: ESP_Fahrer_tritt_ZBR_Schw]";
CM_ SG_ 286 ESP_v_ref_Direction "[DE: ESP_v_ref_Fahrtrichtung]";
CM_ SG_ 286 ESC_BrakePressureGradient "[DE: ESC_Bremsdruckgradient]";
CM_ SG_ 919 LDW_Chime "[DE: LDW_Gong]";
CM_ SG_ 919 LDW_SW_Warning_Left "[DE: LDW_SW_Warnung_links]";
CM_ SG_ 919 LDW_SW_Warning_Right "[DE: LDW_SW_Warnung_rechts]";
CM_ SG_ 919 LDW_Side_DLCTLC "[DE: LDW_Seite_DLCTLC]";
CM_ SG_ 919 LDW_LearnMode "[DE: LDW_Lernmodus]";
CM_ SG_ 919 LDW_StartUpTime_VLR "[DE: LDW_Anlaufzeit_VLR]";
CM_ SG_ 919 LDW_LearnMode_Right "[DE: LDW_Lernmodus_rechts]";
CM_ SG_ 919 LDW_LearnMode_Left "[DE: LDW_Lernmodus_links]";
CM_ SG_ 919 LDW_Warning_Left "[DE: LDW_Warnung_links]";
CM_ SG_ 919 LDW_Warning_Right "[DE: LDW_Warnung_rechts]";
CM_ SG_ 919 LDW_CodingInfo_For_VLR "[DE: LDW_Codierinfo_fuer_VLR]";
CM_ SG_ 919 LDW_WindscreenHeating_Active "[DE: LDW_Frontscheibenheizung_aktiv]";
CM_ SG_ 919 LDW_Status_LED_Yellow "[DE: LDW_Status_LED_gelb]";
CM_ SG_ 919 LDW_Status_LED_Green "[DE: LDW_Status_LED_gruen]";
CM_ SG_ 919 LDW_KD_Error "[DE: LDW_KD_Fehler]";
CM_ SG_ 780 ACC_SetSpeed_02 "[DE: ACC_Wunschgeschw_02]";
CM_ SG_ 780 ACC_Status_Prim_Disp "[DE: ACC_Status_Prim_Anz]";
CM_ SG_ 780 ACC_DistanceIndex "[DE: ACC_Abstandsindex]";
CM_ SG_ 780 ACC_Acoustic_02 "[DE: ACC_Akustik_02]";
CM_ SG_ 780 ACC_Warning_TrafficSign_1 "[DE: ACC_Warnung_Verkehrszeichen_1]";
CM_ SG_ 780 ACC_Set_TimeGap "[DE: ACC_Gesetzte_Zeitluecke]";
CM_ SG_ 780 ACC_Optical_DriverNotice "[DE: ACC_Optischer_Fahrerhinweis]";
CM_ SG_ 780 ACC_Type_SpeedoScale "[DE: ACC_Typ_Tachokranz]";
CM_ SG_ 780 ACC_Display_TimeGap "[DE: ACC_Anzeige_Zeitluecke]";
CM_ SG_ 780 ACC_SpeedoScale "[DE: ACC_Tachokranz]";
CM_ SG_ 780 ACC_Relevant_Object "[DE: ACC_Relevantes_Objekt]";
CM_ SG_ 780 ACC_Texte_PrimaryDisplay "[DE: ACC_Texte_Primaeranz]";
CM_ SG_ 780 ACC_SetSpeed_Reached "[DE: ACC_Wunschgeschw_erreicht]";
CM_ SG_ 780 ACC_Type_SpeedoScale_Bottom "[DE: ACC_Typ_Tachokranz_unten]";
CM_ SG_ 780 ACC_Status_Display "[DE: ACC_Status_Anzeige]";
CM_ SG_ 302 ACC_StoppingDistance "[DE: ACC_Anhalteweg]";
CM_ SG_ 302 ACC_Stop "[DE: ACC_Anhalten]";
CM_ SG_ 302 ACC_Boost_Req "[DE: ACC_Boost_Anf]";
CM_ SG_ 302 ACC_Freewheel_Req "[DE: ACC_Freilauf_Anf]";
CM_ SG_ 302 ACC_Freewheel_Info "[DE: ACC_Freilauf_Info]";
CM_ SG_ 302 ACC_Request_HMS "[DE: ACC_Anforderung_HMS]";
CM_ SG_ 302 ACC_PullAway "[DE: ACC_Anfahren]";
CM_ SG_ 302 ACC_TargetAcceleration_02 "[DE: ACC_Sollbeschleunigung_02]";
CM_ SG_ 264 Chassis_01_BZ "[DE: Fahrwerk_01_BZ]";
CM_ SG_ 264 Chassis_01_CRC "[DE: Fahrwerk_01_CRC]";
CM_ SG_ 783 SWA_Display "[DE: SWA_Anzeigen]";
CM_ SG_ 783 SWA_Blindness_Detected "[DE: SWA_Blindheit_erkannt]";
CM_ SG_ 783 SWA_rel_NotAvail "[DE: SWA_rel_Nichtverf]";
CM_ SG_ 783 SWA_rel_Error "[DE: SWA_rel_Fehler]";
CM_ SG_ 783 SWA_Status_Active "[DE: SWA_Sta_aktiv]";
CM_ SG_ 783 SWA_Status_Passive "[DE: SWA_Sta_passiv]";
CM_ SG_ 783 SWA_StationaryTargets_Left "[DE: SWA_Standziele_li]";
CM_ SG_ 783 SWA_Queue_Left "[DE: SWA_Kolonne_li]";
CM_ SG_ 783 SWA_InfoLevel_SWA_Left "[DE: SWA_Infostufe_SWA_li]";
CM_ SG_ 783 SWA_Warning_SWA_Left "[DE: SWA_Warnung_SWA_li]";
CM_ SG_ 783 ASW_Warning_FS "[DE: ASW_Warnung_FS]";
CM_ SG_ 783 ASW_Warning_BFS "[DE: ASW_Warnung_BFS]";
CM_ SG_ 783 SWA_Queue_mi "[DE: SWA_Kolonne_mi]";
CM_ SG_ 783 SWA_StationaryTargets_Right "[DE: SWA_Standziele_re]";
CM_ SG_ 783 SWA_Queue_Right "[DE: SWA_Kolonne_re]";
CM_ SG_ 783 SWA_InfoLevel_SWA_Right "[DE: SWA_Infostufe_SWA_re]";
CM_ SG_ 783 SWA_Warning_SWA_Right "[DE: SWA_Warnung_SWA_re]";
CM_ SG_ 804 ACC_Texte_SecondaryDisplay "[DE: ACC_Texte_Sekundaeranz]";
CM_ SG_ 804 ACC_Texte_AuxDisplay "[DE: ACC_Texte_Zusatzanz]";
CM_ SG_ 804 ACC_Status_AuxDisplay "[DE: ACC_Status_Zusatzanz]";
CM_ SG_ 804 ACC_WarningNote "[DE: ACC_Warnhinweis]";
CM_ SG_ 804 ACC_TimeGap_DistanceWarner "[DE: ACC_Zeitluecke_Abstandswarner]";
CM_ SG_ 804 ACC_Distance_DistanceWarner "[DE: ACC_Abstand_Abstandswarner]";
CM_ SG_ 804 ACC_SpeedLimit "[DE: ACC_Tempolimit]";
CM_ SG_ 804 ACC_Charisma_DrivePr "[DE: ACC_Charisma_FahrPr]";
CM_ SG_ 804 ACC_Texte_DistanceWarner "[DE: ACC_Texte_Abstandswarner]";
CM_ SG_ 997 DoorECU_FT_02_BZ "[DE: TSG_FT_02_BZ]";
CM_ SG_ 997 DoorECU_FT_02_CRC "[DE: TSG_FT_02_CRC]";
CM_ SG_ 427 ESC_AHW_Active "[DE: ESC_AHW_aktiv]";
CM_ SG_ 427 ESC_AHW_Not_Available "[DE: ESC_AHW_nicht_verfuegbar]";
CM_ SG_ 427 ESC_ANB_CM_Active "[DE: ESC_ANB_CM_aktiv]";
CM_ SG_ 427 ESC_ANB_CM_Not_Available "[DE: ESC_ANB_CM_nicht_verfuegbar]";
CM_ SG_ 427 ESC_WarnJerk_Active "[DE: ESC_Warnruck_aktiv]";
CM_ SG_ 427 ESC_WarnJerk_Not_Available "[DE: ESC_Warnruck_nicht_verfuegbar]";
CM_ SG_ 427 ESC_Prefill_Active "[DE: ESC_Prefill_aktiv]";
CM_ SG_ 427 ESC_Prefill_Not_Available "[DE: ESC_Prefill_nicht_verfuegbar]";
CM_ SG_ 427 ESC_HBA_Active "[DE: ESC_HBA_aktiv]";
CM_ SG_ 427 ESC_HBA_Not_Available "[DE: ESC_HBA_nicht_verfuegbar]";
CM_ SG_ 427 ESC_TSK_SRBM_Req "[DE: ESC_TSK_SRBM_Anf]";
CM_ SG_ 427 ESC_TSK_SRBM_Not_Available "[DE: ESC_TSK_SRBM_nicht_verfuegbar]";
CM_ SG_ 427 ESC_Decel_Reg_Active "[DE: ESC_Verz_Reg_aktiv]";
CM_ SG_ 427 ESC_Decel_Reg_Not_Available "[DE: ESC_Verz_Reg_nicht_verfuegbar]";
CM_ SG_ 427 ESC_Decel_Reg_TB_Not_Available "[DE: ESC_Verz_Reg_TB_nicht_verfuegbar]";
CM_ SG_ 427 ESC_Decel_Reg_ZB_Not_Available "[DE: ESC_Verz_Reg_ZB_nicht_verfuegbar]";
CM_ SG_ 427 ESC_BrakeLight_Implausible "[DE: ESC_Bremslicht_unplausibel]";
CM_ SG_ 427 ESC_Consistency_ACC "[DE: ESC_Konsistenz_ACC]";
CM_ SG_ 427 ESC_Consistency_AWV "[DE: ESC_Konsistenz_AWV]";
CM_ SG_ 427 ESC_Consistency_ARA "[DE: ESC_Konsistenz_ARA]";
CM_ SG_ 427 ESC_Consistency_IPA "[DE: ESC_Konsistenz_IPA]";
CM_ SG_ 427 ESC_Consistency_FCW "[DE: ESC_Konsistenz_FCW]";
CM_ SG_ 427 ESC_Consistency_NV "[DE: ESC_Konsistenz_NV]";
CM_ SG_ 427 ESC_Consistency_RCTA "[DE: ESC_Konsistenz_RCTA]";
CM_ SG_ 427 ESC_Consistency_TSK "[DE: ESC_Konsistenz_TSK]";
CM_ SG_ 427 ESC_Consistency_vFGS "[DE: ESC_Konsistenz_vFGS]";
CM_ SG_ 427 ESC_Consistency_Status "[DE: ESC_Konsistenz_STA]";
CM_ SG_ 427 ESC_Driver_BrakePressure_bestimmend "[DE: ESC_Fahrer_Bremsdruck_bestimmend]";
CM_ SG_ 427 ESC_Consistency_EA "[DE: ESC_Konsistenz_EA]";
CM_ SG_ 427 ESC_Consistency_BFF "[DE: ESC_Konsistenz_BFF]";
CM_ SG_ 427 ESC_Consistency_MKB "[DE: ESC_Konsistenz_MKB]";
CM_ SG_ 427 ESC_Decel_ASIL_Availability "[DE: ESC_Verz_ASIL_Verfuegbarkeit]";
CM_ SG_ 427 ESC_PumpStartUp_Active "[DE: ESC_Pumpenanlauf_aktiv]";
CM_ SG_ 427 ESC_Consistency_AGW "[DE: ESC_Konsistenz_AGW]";
CM_ SG_ 427 ESC_Consistency_KAS "[DE: ESC_Konsistenz_KAS]";
CM_ SG_ 427 ESC_Consistency_PCF "[DE: ESC_Konsistenz_PCF]";
CM_ SG_ 427 ESC_Consistency_FAS_VK "[DE: ESC_Konsistenz_FAS_VK]";
CM_ SG_ 427 ESC_Decel_Limit "[DE: ESC_Verz_Begrenzung]";
CM_ SG_ 427 ESC_Consistency_AWA "[DE: ESC_Konsistenz_AWA]";
CM_ SG_ 988 GE_DriveRange "[DE: GE_Fahrstufe]";
CM_ SG_ 981 BCM1_CorneringLight_Left_Req "[DE: BCM1_Kurvenlicht_links_Anf]";
CM_ SG_ 981 BCM1_CorneringLight_Right_Req "[DE: BCM1_Kurvenlicht_rechts_Anf]";
CM_ SG_ 981 BCM1_SideLight_Req "[DE: BCM1_Standlicht_Anf]";
CM_ SG_ 981 BCM1_LowBeam_Req "[DE: BCM1_Abblendlicht_Anf]";
CM_ SG_ 981 BCM1_HighBeam_Req "[DE: BCM1_Fernlicht_Anf]";
CM_ SG_ 981 BCM1_FogLight_Req "[DE: BCM1_Nebellicht_Anf]";
CM_ SG_ 981 BCM1_ParkingLight_Left_Req "[DE: BCM1_Parklicht_li_Anf]";
CM_ SG_ 981 BCM1_ParkingLight_Right_Req "[DE: BCM1_Parklicht_re_Anf]";
CM_ SG_ 981 BCM1_RearFog_Ahg_Req "[DE: BCM1_Nebelschluss_Ahg_Anf]";
CM_ SG_ 981 BCM1_RearFog_Veh_Req "[DE: BCM1_Nebelschluss_Fzg_Anf]";
CM_ SG_ 981 BCM1_TailLight_Req "[DE: BCM1_Schlusslicht_Anf]";
CM_ SG_ 981 BCM_ReversingLight_Req "[DE: BCM_Rueckfahrlicht_Anf]";
CM_ SG_ 981 BCM1_SignatureLight_Req "[DE: BCM1_Signaturlicht_Anf]";
CM_ SG_ 981 BCM1_Umfeldleuchten_Req "[DE: BCM1_Umfeldleuchten_Anf]";
CM_ SG_ 981 BCM1_DaytimeRunningLight_Req "[DE: BCM1_Tagfahrlicht_Anf]";
CM_ SG_ 981 BCM1_RainLight_Req "[DE: BCM1_Regenlicht_Anf]";
CM_ SG_ 981 BCM1_MotorwayLight_Req "[DE: BCM1_Autobahnlicht_Anf]";
CM_ SG_ 981 BCM1_Tourist_Light_Req "[DE: BCM1_Touristen_Licht_Anf]";
CM_ SG_ 981 BCM1_CH_Active "[DE: BCM1_CH_aktiv]";
CM_ SG_ 981 BCM1_LH_Active "[DE: BCM1_LH_aktiv]";
CM_ SG_ 981 BCM1_Sliding_Leuchtw_Req "[DE: BCM1_Gleitende_Leuchtw_Anf]";
CM_ SG_ 981 BCM1_GLW_HighBeam_Req "[DE: BCM1_GLW_Fernlicht_Anf]";
CM_ SG_ 981 BCM1_Adaptive_LightDistribution_Req "[DE: BCM1_Adaptive_Lichtvert_Anf]";
CM_ SG_ 981 BCM1_CH_LH_Active "[DE: BCM1_CH_LH_aktiv]";
CM_ SG_ 981 BCM1_AllWeatherLight_Req "[DE: BCM1_Allwetterlicht_Anf]";
CM_ SG_ 391 EV_RecuperationStage "[DE: EV_Rekuperationsstufe]";
CM_ SG_ 391 HV_VehicleElectrics_Active "[DE: HV_Bordnetz_aktiv]";
CM_ SG_ 391 MO_Error_NTCircuit "[DE: MO_Fehler_NTKreis]";
CM_ SG_ 391 MO_Error_Notabschaltung_Climate "[DE: MO_Fehler_Notabschaltung_Klima]";
CM_ SG_ 391 MO_Rpm_VM "[DE: MO_Drehzahl_VM]";
CM_ SG_ 391 HV_VehicleElectrics_Error "[DE: HV_Bordnetz_Fehler]";
CM_ SG_ 391 MO_FuelFlapControl "[DE: MO_Tankklappensteuerung]";
CM_ SG_ 391 MO_HVEM_Escalation "[DE: MO_HVEM_Eskalation]";
CM_ SG_ 391 MO_HVEM_MaxPower "[DE: MO_HVEM_MaxLeistung]";
CM_ BO_ 1633 "[DE: Anhaenger_01]";
CM_ BO_ 1714 "[DE: Diagnose_01]";
CM_ BO_ 1520 "[DE: Dimmung_01]";
CM_ BO_ 1603 "[DE: Einheiten_01]";
CM_ BO_ 296 "[DE: Getriebe_06]";
CM_ BO_ 173 "[DE: Getriebe_11]";
CM_ BO_ 174 "[DE: Getriebe_12]";
CM_ BO_ 301 "[DE: Getriebe_13]";
CM_ BO_ 968 "[DE: Getriebe_14]";
CM_ BO_ 158 "[DE: Getriebe_Hybrid_01]";
CM_ BO_ 960 "[DE: Klemmen_Status_01]";
CM_ BO_ 949 "[DE: Klima_11]";
CM_ BO_ 1625 "[DE: Klimakomp_01]";
CM_ BO_ 2549088380 "[DE: KN_EMotor_01]";
CM_ BO_ 2549088375 "[DE: KN_Getriebe_01]";
CM_ BO_ 779 "[DE: Kombi_01]";
CM_ BO_ 1719 "[DE: Kombi_02]";
CM_ BO_ 982 "[DE: Licht_hinten_01]";
CM_ BO_ 263 "[DE: Motor_04]";
CM_ BO_ 1600 "[DE: Motor_07]";
CM_ BO_ 1607 "[DE: Motor_09]";
CM_ BO_ 167 "[DE: Motor_11]";
CM_ BO_ 168 "[DE: Motor_12]";
CM_ BO_ 958 "[DE: Motor_14]";
CM_ BO_ 1631 "[DE: Motor_16]";
CM_ BO_ 812 "[DE: Motor_17]";
CM_ BO_ 1648 "[DE: Motor_18]";
CM_ BO_ 289 "[DE: Motor_20]";
CM_ BO_ 967 "[DE: Motor_26]";
CM_ BO_ 1601 "[DE: Motor_Code_01]";
CM_ BO_ 157 "[DE: Motor_Hybrid_01]";
CM_ BO_ 811 "[DE: Motor_Hybrid_02]";
CM_ BO_ 2600468604 "[DE: NMH_EMotor_01]";
CM_ BO_ 2600468599 "[DE: NMH_Getriebe_01]";
CM_ BO_ 1630 "[DE: OBD_Tankgeber_01]";
CM_ BO_ 1172 "[DE: STS_01]";
CM_ BO_ 1413 "[DE: Systeminfo_01]";
CM_ BO_ 175 "[DE: Waehlhebel_03]";
CM_ BO_ 264 "[DE: Fahrwerk_01]";
CM_ BO_ 997 "[DE: TSG_FT_02]";
CM_ BO_ 1175 "[DE: Parkhilfe_01]";
CM_ BO_ 792 "[DE: Kamera_Status]";
CM_ BO_ 981 "[DE: Licht_Anf_01]";
CM_ BO_ 870 "[DE: Blinkmodi_02]";
CM_ BO_ 1624 "[DE: Licht_vorne_01]";
CM_ BO_ 1646 "[DE: Klima_03]";
CM_ BO_ 1720 "[DE: Kombi_03]";
CM_ BO_ 391 "[DE: Motor_EV_01]";
CM_ "English names by can2gauge tools/dbc/dbc_tool.py from opendbc vw_mqb.dbc (MIT); the original German names are in the comments as [DE: ...]";
